VERSION "HNNBNNNYNNNNNNNNNNNNNNNNNNNNNNNNNNNNNNNNNN/4/%%%/4/'%**4NNN///"

NS_ :

BS_:

BU_: AFS AFS_LMod_L AFS_LMod_R BCM1 BVS FCM GLW_LMod_L GLW_LMod_R LCM_L LCM_R LED_DK3_LM_L LED_DK3_LM_R LED_LM_L LED_LM_R LLP_L LLP_R LWR_MXB_L LWR_MXB_R MXB MXB_LM_L MXB_LM_R ZFAS

BO_ 1357 MXB_Feh_LM_R: 8 LED_DK3_LM_R
 SG_ MXB_R_Fernl_MXB_Def_1 : 0|1@1+ (1,0) [0|1] ""  AFS,FCM,MXB
 SG_ MXB_R_Fernl_MXB_Def_2 : 1|1@1+ (1,0) [0|1] ""  AFS,FCM,MXB
 SG_ MXB_R_Fernl_MXB_Def_3 : 2|1@1+ (1,0) [0|1] ""  AFS,FCM,MXB
 SG_ MXB_R_Fernl_MXB_Def_4 : 3|1@1+ (1,0) [0|1] ""  AFS,FCM,MXB
 SG_ MXB_R_Fernl_MXB_Def_5 : 4|1@1+ (1,0) [0|1] ""  AFS,FCM,MXB
 SG_ MXB_R_Fernl_MXB_Def_6 : 5|1@1+ (1,0) [0|1] ""  AFS,FCM,MXB
 SG_ MXB_R_Fernl_MXB_Def_7 : 6|1@1+ (1,0) [0|1] ""  AFS,FCM,MXB
 SG_ MXB_R_Fernl_MXB_Def_Err_Gultig : 7|1@1+ (1,0) [0|1] ""  AFS,FCM,MXB
 SG_ MXB_R_Allg_Elektr_Def_1 : 8|1@1+ (1,0) [0|1] ""  AFS,FCM,MXB
 SG_ MXB_R_Allg_Elektr_Def_2 : 9|1@1+ (1,0) [0|1] ""  AFS,FCM,MXB
 SG_ MXB_R_Allg_Elektr_Def_3 : 10|1@1+ (1,0) [0|1] ""  AFS,FCM,MXB
 SG_ MXB_R_Allg_Elektr_Def_4 : 11|1@1+ (1,0) [0|1] ""  AFS,FCM,MXB
 SG_ MXB_R_Allg_Elektr_Def_5 : 12|1@1+ (1,0) [0|1] ""  AFS,FCM,MXB
 SG_ MXB_R_Allg_Elektr_Def_6 : 13|1@1+ (1,0) [0|1] ""  AFS,FCM,MXB
 SG_ MXB_R_Allg_Elektr_Def_7 : 14|1@1+ (1,0) [0|1] ""  AFS,FCM,MXB
 SG_ MXB_R_Allg_Elektr_Def_8 : 15|1@1+ (1,0) [0|1] ""  AFS,FCM,MXB
 SG_ MXB_R_Allg_Elektr_Def_Err_Gultig : 16|1@1+ (1,0) [0|1] ""  AFS,FCM,MXB
 SG_ MXB_R_Luefter_1_Def_1 : 17|1@1+ (1,0) [0|1] ""  AFS,FCM,MXB
 SG_ MXB_R_Luefter_1_Def_2 : 18|1@1+ (1,0) [0|1] ""  AFS,FCM,MXB
 SG_ MXB_R_Luefter_1_Def_3 : 19|1@1+ (1,0) [0|1] ""  AFS,FCM,MXB
 SG_ MXB_R_Luefter_1_Def_4 : 20|1@1+ (1,0) [0|1] ""  AFS,FCM,MXB
 SG_ MXB_R_Luefter_2_Def_1 : 21|1@1+ (1,0) [0|1] ""  AFS,FCM,MXB
 SG_ MXB_R_Luefter_2_Def_2 : 22|1@1+ (1,0) [0|1] ""  AFS,FCM,MXB
 SG_ MXB_R_Luefter_2_Def_3 : 23|1@1+ (1,0) [0|1] ""  AFS,FCM,MXB
 SG_ MXB_R_Luefter_2_Def_4 : 24|1@1+ (1,0) [0|1] ""  AFS,FCM,MXB
 SG_ MXB_R_Luefter_1_Def_Err_Gultig : 25|1@1+ (1,0) [0|1] ""  AFS,FCM,MXB
 SG_ MXB_R_Luefter_2_Def_Err_Gultig : 26|1@1+ (1,0) [0|1] ""  AFS,FCM,MXB
 SG_ MXB_R_Allg_Elektr_Def : 27|1@1+ (1,0) [0|1] ""  AFS,BCM1,BVS,FCM,MXB,ZFAS
 SG_ MXB_R_Fernl_MXB_Def : 28|1@1+ (1,0) [0|1] ""  AFS,BCM1,BVS,FCM,MXB,ZFAS

BO_ 1438 MXB_Idt_LM_L: 8 LED_LM_L
 SG_ MXB_L_Mux M : 0|8@1+ (1,0) [0|4] ""  AFS,FCM,MXB
 SG_ MXB_L_SW_Idt_Z01 m0 : 8|8@1+ (1,0) [0|255] ""  AFS,FCM,MXB
 SG_ MXB_L_SW_Idt_Z08 m1 : 8|8@1+ (1,0) [0|255] ""  AFS,FCM,MXB
 SG_ MXB_L_SW_Idx_Z04 m2 : 8|8@1+ (1,0) [0|255] ""  AFS,FCM,MXB
 SG_ MXB_L_HW_Idt_Z07 m3 : 8|8@1+ (1,0) [0|255] ""  AFS,FCM,MXB
 SG_ MXB_L_HW_Idx_Z03 m4 : 8|8@1+ (1,0) [0|255] ""  AFS,FCM,MXB
 SG_ MXB_L_SW_Idt_Z02 m0 : 16|8@1+ (1,0) [0|255] ""  AFS,FCM,MXB
 SG_ MXB_L_SW_Idt_Z09 m1 : 16|8@1+ (1,0) [0|255] ""  AFS,FCM,MXB
 SG_ MXB_L_HW_Idt_Z01 m2 : 16|8@1+ (1,0) [0|255] ""  AFS,FCM,MXB
 SG_ MXB_L_HW_Idt_Z08 m3 : 16|8@1+ (1,0) [0|255] ""  AFS,FCM,MXB
 SG_ MXB_L_SW_Idt_Z03 m0 : 24|8@1+ (1,0) [0|255] ""  AFS,FCM,MXB
 SG_ MXB_L_SW_Idt_Z10 m1 : 24|8@1+ (1,0) [0|255] ""  AFS,FCM,MXB
 SG_ MXB_L_HW_Idt_Z02 m2 : 24|8@1+ (1,0) [0|255] ""  AFS,FCM,MXB
 SG_ MXB_L_HW_Idt_Z09 m3 : 24|8@1+ (1,0) [0|255] ""  AFS,FCM,MXB
 SG_ MXB_L_SW_Idt_Z04 m0 : 32|8@1+ (1,0) [0|255] ""  AFS,FCM,MXB
 SG_ MXB_L_SW_Idt_Z11 m1 : 32|8@1+ (1,0) [0|255] ""  AFS,FCM,MXB
 SG_ MXB_L_HW_Idt_Z03 m2 : 32|8@1+ (1,0) [0|255] ""  AFS,FCM,MXB
 SG_ MXB_L_HW_Idt_Z10 m3 : 32|8@1+ (1,0) [0|255] ""  AFS,FCM,MXB
 SG_ MXB_L_SW_Idt_Z05 m0 : 40|8@1+ (1,0) [0|255] ""  AFS,FCM,MXB
 SG_ MXB_L_SW_Idx_Z01 m1 : 40|8@1+ (1,0) [0|255] ""  AFS,FCM,MXB
 SG_ MXB_L_HW_Idt_Z04 m2 : 40|8@1+ (1,0) [0|255] ""  AFS,FCM,MXB
 SG_ MXB_L_HW_Idt_Z11 m3 : 40|8@1+ (1,0) [0|255] ""  AFS,FCM,MXB
 SG_ MXB_L_SW_Idt_Z06 m0 : 48|8@1+ (1,0) [0|255] ""  AFS,FCM,MXB
 SG_ MXB_L_SW_Idx_Z02 m1 : 48|8@1+ (1,0) [0|255] ""  AFS,FCM,MXB
 SG_ MXB_L_HW_Idt_Z05 m2 : 48|8@1+ (1,0) [0|255] ""  AFS,FCM,MXB
 SG_ MXB_L_HW_Idx_Z01 m3 : 48|8@1+ (1,0) [0|255] ""  AFS,FCM,MXB
 SG_ MXB_L_SW_Idt_Z07 m0 : 56|8@1+ (1,0) [0|255] ""  AFS,FCM,MXB
 SG_ MXB_L_SW_Idx_Z03 m1 : 56|8@1+ (1,0) [0|255] ""  AFS,FCM,MXB
 SG_ MXB_L_HW_Idt_Z06 m2 : 56|8@1+ (1,0) [0|255] ""  AFS,FCM,MXB
 SG_ MXB_L_HW_Idx_Z02 m3 : 56|8@1+ (1,0) [0|255] ""  AFS,FCM,MXB

BO_ 1437 MXB_Idt_LM_R: 8 LED_LM_R
 SG_ MXB_R_Mux M : 0|8@1+ (1,0) [0|4] ""  AFS,FCM,MXB
 SG_ MXB_R_SW_Idt_Z01 m0 : 8|8@1+ (1,0) [0|255] ""  AFS,FCM,MXB
 SG_ MXB_R_SW_Idt_Z08 m1 : 8|8@1+ (1,0) [0|255] ""  AFS,FCM,MXB
 SG_ MXB_R_SW_Idx_Z04 m2 : 8|8@1+ (1,0) [0|255] ""  AFS,FCM,MXB
 SG_ MXB_R_HW_Idt_Z07 m3 : 8|8@1+ (1,0) [0|255] ""  AFS,FCM,MXB
 SG_ MXB_R_HW_Idx_Z03 m4 : 8|8@1+ (1,0) [0|255] ""  AFS,FCM,MXB
 SG_ MXB_R_SW_Idt_Z02 m0 : 16|8@1+ (1,0) [0|255] ""  AFS,FCM,MXB
 SG_ MXB_R_SW_Idt_Z09 m1 : 16|8@1+ (1,0) [0|255] ""  AFS,FCM,MXB
 SG_ MXB_R_HW_Idt_Z01 m2 : 16|8@1+ (1,0) [0|255] ""  AFS,FCM,MXB
 SG_ MXB_R_HW_Idt_Z08 m3 : 16|8@1+ (1,0) [0|255] ""  AFS,FCM,MXB
 SG_ MXB_R_SW_Idt_Z03 m0 : 24|8@1+ (1,0) [0|255] ""  AFS,FCM,MXB
 SG_ MXB_R_SW_Idt_Z10 m1 : 24|8@1+ (1,0) [0|255] ""  AFS,FCM,MXB
 SG_ MXB_R_HW_Idt_Z02 m2 : 24|8@1+ (1,0) [0|255] ""  AFS,FCM,MXB
 SG_ MXB_R_HW_Idt_Z09 m3 : 24|8@1+ (1,0) [0|255] ""  AFS,FCM,MXB
 SG_ MXB_R_SW_Idt_Z04 m0 : 32|8@1+ (1,0) [0|255] ""  AFS,FCM,MXB
 SG_ MXB_R_SW_Idt_Z11 m1 : 32|8@1+ (1,0) [0|255] ""  AFS,FCM,MXB
 SG_ MXB_R_HW_Idt_Z03 m2 : 32|8@1+ (1,0) [0|255] ""  AFS,FCM,MXB
 SG_ MXB_R_HW_Idt_Z10 m3 : 32|8@1+ (1,0) [0|255] ""  AFS,FCM,MXB
 SG_ MXB_R_SW_Idt_Z05 m0 : 40|8@1+ (1,0) [0|255] ""  AFS,FCM,MXB
 SG_ MXB_R_SW_Idx_Z01 m1 : 40|8@1+ (1,0) [0|255] ""  AFS,FCM,MXB
 SG_ MXB_R_HW_Idt_Z04 m2 : 40|8@1+ (1,0) [0|255] ""  AFS,FCM,MXB
 SG_ MXB_R_HW_Idt_Z11 m3 : 40|8@1+ (1,0) [0|255] ""  AFS,FCM,MXB
 SG_ MXB_R_SW_Idt_Z06 m0 : 48|8@1+ (1,0) [0|255] ""  AFS,FCM,MXB
 SG_ MXB_R_SW_Idx_Z02 m1 : 48|8@1+ (1,0) [0|255] ""  AFS,FCM,MXB
 SG_ MXB_R_HW_Idt_Z05 m2 : 48|8@1+ (1,0) [0|255] ""  AFS,FCM,MXB
 SG_ MXB_R_HW_Idx_Z01 m3 : 48|8@1+ (1,0) [0|255] ""  AFS,FCM,MXB
 SG_ MXB_R_SW_Idt_Z07 m0 : 56|8@1+ (1,0) [0|255] ""  AFS,FCM,MXB
 SG_ MXB_R_SW_Idx_Z03 m1 : 56|8@1+ (1,0) [0|255] ""  AFS,FCM,MXB
 SG_ MXB_R_HW_Idt_Z06 m2 : 56|8@1+ (1,0) [0|255] ""  AFS,FCM,MXB
 SG_ MXB_R_HW_Idx_Z02 m3 : 56|8@1+ (1,0) [0|255] ""  AFS,FCM,MXB

BO_ 1306 MXB_Ken_LM_L: 8 LED_LM_L
 SG_ MXB_L_Scheinw_Var_1 : 12|8@1+ (1,0) [0|255] ""  AFS,FCM,MXB
 SG_ MXB_L_Scheinw_Var_2 : 20|8@1+ (1,0) [0|255] ""  AFS,FCM,MXB

BO_ 1307 MXB_Ken_LM_R: 8 LED_LM_R
 SG_ MXB_R_Scheinw_Var_1 : 12|8@1+ (1,0) [0|255] ""  AFS,FCM,MXB
 SG_ MXB_R_Scheinw_Var_2 : 20|8@1+ (1,0) [0|255] ""  AFS,FCM,MXB

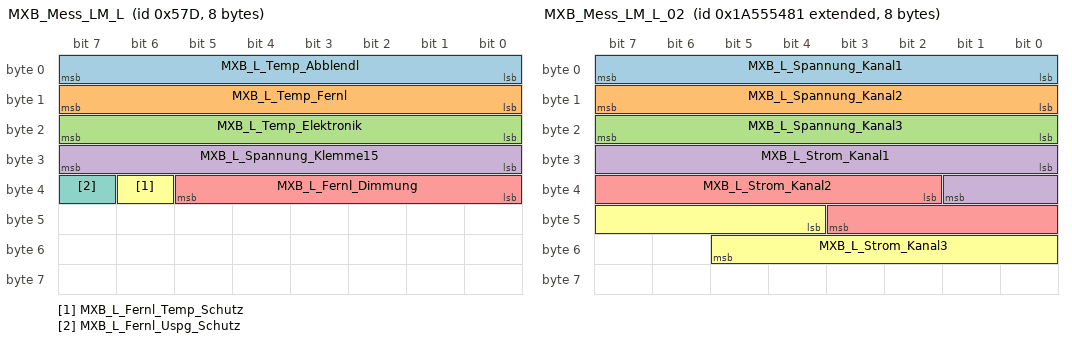
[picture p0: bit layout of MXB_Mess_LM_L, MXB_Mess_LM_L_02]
BO_ 1405 MXB_Mess_LM_L: 8 LED_LM_L
 SG_ MXB_L_Temp_Abblendl : 0|8@1+ (1,-50) [-50|204] "Unit_DegreCelsi"  AFS,FCM,MXB
 SG_ MXB_L_Temp_Fernl : 8|8@1+ (1,-50) [-50|204] "Unit_DegreCelsi"  AFS,FCM,MXB
 SG_ MXB_L_Temp_Elektronik : 16|8@1+ (1,-50) [-50|204] "Unit_DegreCelsi"  AFS,FCM,MXB
 SG_ MXB_L_Spannung_Klemme15 : 24|8@1+ (0.08,0) [0|20.32] "Unit_Volt"  AFS,FCM,MXB
 SG_ MXB_L_Fernl_Dimmung : 32|6@1+ (1.6,0) [1.6|100.8] "Unit_PerCent"  AFS,FCM,MXB
 SG_ MXB_L_Fernl_Temp_Schutz : 38|1@1+ (1,0) [0|1] ""  AFS,FCM,MXB
 SG_ MXB_L_Fernl_Uspg_Schutz : 39|1@1+ (1,0) [0|1] ""  AFS,FCM,MXB

BO_ 2589283457 MXB_Mess_LM_L_02: 8 LED_LM_L
 SG_ MXB_L_Spannung_Kanal1 : 0|8@1+ (0.1,0) [0|25] "Unit_Volt"  FCM,MXB
 SG_ MXB_L_Spannung_Kanal2 : 8|8@1+ (0.1,0) [0|25] "Unit_Volt"  FCM,MXB
 SG_ MXB_L_Spannung_Kanal3 : 16|8@1+ (0.1,0) [0|25] "Unit_Volt"  FCM,MXB
 SG_ MXB_L_Strom_Kanal1 : 24|10@1+ (10,0) [0|10000] "Unit_MilliAmper"  FCM,MXB
 SG_ MXB_L_Strom_Kanal2 : 34|10@1+ (10,0) [0|10000] "Unit_MilliAmper"  FCM,MXB
 SG_ MXB_L_Strom_Kanal3 : 44|10@1+ (10,0) [0|10000] "Unit_MilliAmper"  FCM,MXB

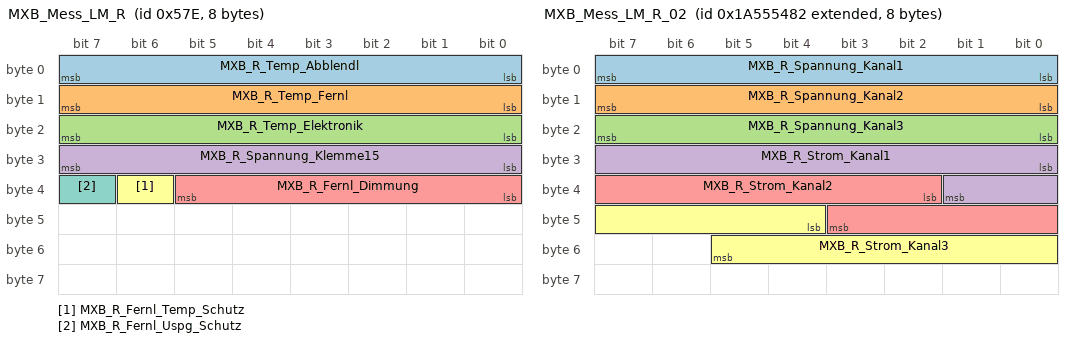
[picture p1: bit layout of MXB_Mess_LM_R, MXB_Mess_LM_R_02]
BO_ 1406 MXB_Mess_LM_R: 8 LED_LM_R
 SG_ MXB_R_Temp_Abblendl : 0|8@1+ (1,-50) [-50|204] "Unit_DegreCelsi"  AFS,FCM,MXB
 SG_ MXB_R_Temp_Fernl : 8|8@1+ (1,-50) [-50|204] "Unit_DegreCelsi"  AFS,FCM,MXB
 SG_ MXB_R_Temp_Elektronik : 16|8@1+ (1,-50) [-50|204] "Unit_DegreCelsi"  AFS,FCM,MXB
 SG_ MXB_R_Spannung_Klemme15 : 24|8@1+ (0.08,0) [0|20.32] "Unit_Volt"  AFS,FCM,MXB
 SG_ MXB_R_Fernl_Dimmung : 32|6@1+ (1.6,0) [1.6|100.8] "Unit_PerCent"  AFS,FCM,MXB
 SG_ MXB_R_Fernl_Temp_Schutz : 38|1@1+ (1,0) [0|1] ""  AFS,FCM,MXB
 SG_ MXB_R_Fernl_Uspg_Schutz : 39|1@1+ (1,0) [0|1] ""  AFS,FCM,MXB

BO_ 2589283458 MXB_Mess_LM_R_02: 8 LED_LM_R
 SG_ MXB_R_Spannung_Kanal1 : 0|8@1+ (0.1,0) [0|25] "Unit_Volt"  FCM,MXB
 SG_ MXB_R_Spannung_Kanal2 : 8|8@1+ (0.1,0) [0|25] "Unit_Volt"  FCM,MXB
 SG_ MXB_R_Spannung_Kanal3 : 16|8@1+ (0.1,0) [0|25] "Unit_Volt"  FCM,MXB
 SG_ MXB_R_Strom_Kanal1 : 24|10@1+ (10,0) [0|10000] "Unit_MilliAmper"  FCM,MXB
 SG_ MXB_R_Strom_Kanal2 : 34|10@1+ (10,0) [0|10000] "Unit_MilliAmper"  FCM,MXB
 SG_ MXB_R_Strom_Kanal3 : 44|10@1+ (10,0) [0|10000] "Unit_MilliAmper"  FCM,MXB

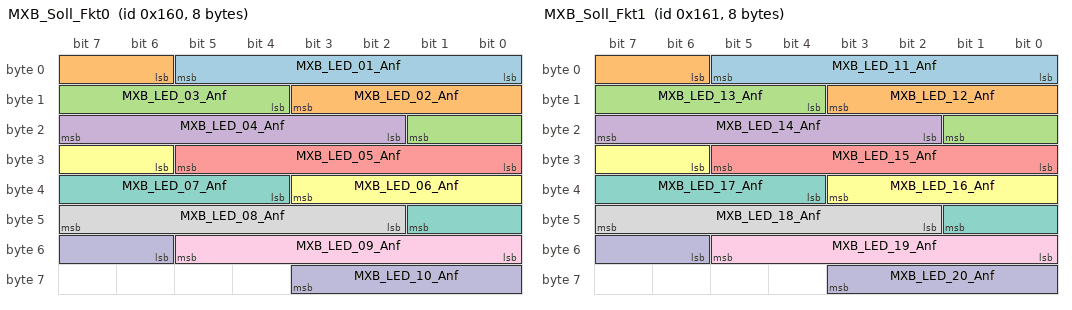
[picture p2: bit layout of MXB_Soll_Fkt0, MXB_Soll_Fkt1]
BO_ 352 MXB_Soll_Fkt0: 8 AFS
 SG_ MXB_LED_01_Anf : 0|6@1+ (1.6,0) [1.6|100.8] "Unit_PerCent"  LED_DK3_LM_L,LED_LM_L,LLP_L,LWR_MXB_L,MXB_LM_L
 SG_ MXB_LED_02_Anf : 6|6@1+ (1.6,0) [1.6|100.8] "Unit_PerCent"  LED_DK3_LM_L,LED_LM_L,LLP_L,LWR_MXB_L,MXB_LM_L
 SG_ MXB_LED_03_Anf : 12|6@1+ (1.6,0) [1.6|100.8] "Unit_PerCent"  LED_DK3_LM_L,LED_LM_L,LLP_L,LWR_MXB_L,MXB_LM_L
 SG_ MXB_LED_04_Anf : 18|6@1+ (1.6,0) [1.6|100.8] "Unit_PerCent"  LED_DK3_LM_L,LED_LM_L,LLP_L,LWR_MXB_L,MXB_LM_L
 SG_ MXB_LED_05_Anf : 24|6@1+ (1.6,0) [1.6|100.8] "Unit_PerCent"  LED_DK3_LM_L,LED_LM_L,LLP_L,LWR_MXB_L,MXB_LM_L
 SG_ MXB_LED_06_Anf : 30|6@1+ (1.6,0) [1.6|100.8] "Unit_PerCent"  LED_DK3_LM_L,LED_LM_L,LLP_L,LWR_MXB_L,MXB_LM_L
 SG_ MXB_LED_07_Anf : 36|6@1+ (1.6,0) [1.6|100.8] "Unit_PerCent"  LED_DK3_LM_L,LED_LM_L,LLP_L,LWR_MXB_L,MXB_LM_L
 SG_ MXB_LED_08_Anf : 42|6@1+ (1.6,0) [1.6|100.8] "Unit_PerCent"  LED_DK3_LM_L,LED_LM_L,LLP_L,LWR_MXB_L,MXB_LM_L
 SG_ MXB_LED_09_Anf : 48|6@1+ (1.6,0) [1.6|100.8] "Unit_PerCent"  LED_DK3_LM_L,LED_LM_L,LLP_L,LWR_MXB_L,MXB_LM_L
 SG_ MXB_LED_10_Anf : 54|6@1+ (1.6,0) [1.6|100.8] "Unit_PerCent"  LED_DK3_LM_L,LED_LM_L,LLP_L,LWR_MXB_L,MXB_LM_L

BO_ 353 MXB_Soll_Fkt1: 8 AFS
 SG_ MXB_LED_11_Anf : 0|6@1+ (1.6,0) [1.6|100.8] "Unit_PerCent"  LED_DK3_LM_L,LED_LM_L,LLP_L,LWR_MXB_L,MXB_LM_L
 SG_ MXB_LED_12_Anf : 6|6@1+ (1.6,0) [1.6|100.8] "Unit_PerCent"  LED_DK3_LM_L,LED_LM_L,LLP_L,LWR_MXB_L,MXB_LM_L
 SG_ MXB_LED_13_Anf : 12|6@1+ (1.6,0) [1.6|100.8] "Unit_PerCent"  LED_DK3_LM_L,LED_LM_L,LLP_L,MXB_LM_L
 SG_ MXB_LED_14_Anf : 18|6@1+ (1.6,0) [1.6|100.8] "Unit_PerCent"  LED_DK3_LM_L,LED_LM_L,LLP_L,MXB_LM_L
 SG_ MXB_LED_15_Anf : 24|6@1+ (1.6,0) [1.6|100.8] "Unit_PerCent"  LED_DK3_LM_L,LED_LM_L,LLP_L,MXB_LM_L
 SG_ MXB_LED_16_Anf : 30|6@1+ (1.6,0) [1.6|100.8] "Unit_PerCent"  LED_DK3_LM_L,LED_LM_L,LLP_L,MXB_LM_L
 SG_ MXB_LED_17_Anf : 36|6@1+ (1.6,0) [1.6|100.8] "Unit_PerCent"  LED_DK3_LM_L,LED_LM_L,LLP_L,MXB_LM_L
 SG_ MXB_LED_18_Anf : 42|6@1+ (1.6,0) [1.6|100.8] "Unit_PerCent"  LED_DK3_LM_L,LED_LM_L,LLP_L,MXB_LM_L
 SG_ MXB_LED_19_Anf : 48|6@1+ (1.6,0) [1.6|100.8] "Unit_PerCent"  LED_DK3_LM_L,LED_LM_L,LLP_L,MXB_LM_L
 SG_ MXB_LED_20_Anf : 54|6@1+ (1.6,0) [1.6|100.8] "Unit_PerCent"  LED_DK3_LM_L,LED_LM_L,LLP_L,MXB_LM_L

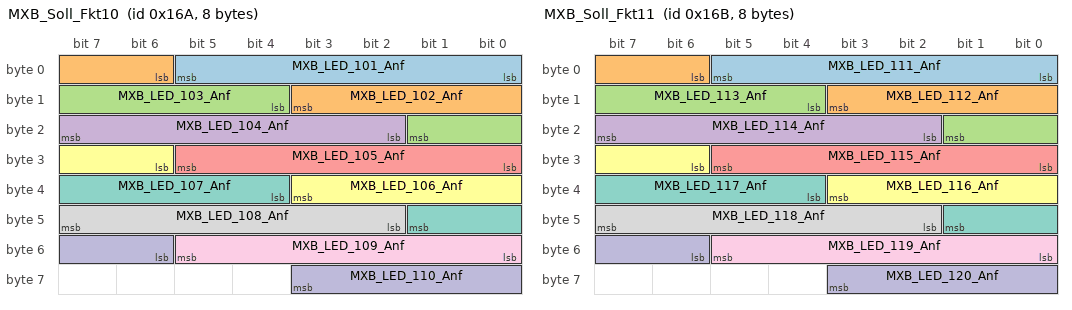
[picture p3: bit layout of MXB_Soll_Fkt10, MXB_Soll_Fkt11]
BO_ 362 MXB_Soll_Fkt10: 8 BVS
 SG_ MXB_LED_101_Anf : 0|6@1+ (1.6,0) [1.6|100.8] "Unit_PerCent"  LED_DK3_LM_R,LLP_R
 SG_ MXB_LED_102_Anf : 6|6@1+ (1.6,0) [1.6|100.8] "Unit_PerCent"  LED_DK3_LM_R,LLP_R
 SG_ MXB_LED_103_Anf : 12|6@1+ (1.6,0) [1.6|100.8] "Unit_PerCent"  LED_DK3_LM_R,LLP_R
 SG_ MXB_LED_104_Anf : 18|6@1+ (1.6,0) [1.6|100.8] "Unit_PerCent"  LED_DK3_LM_R,LLP_R
 SG_ MXB_LED_105_Anf : 24|6@1+ (1.6,0) [1.6|100.8] "Unit_PerCent"  LED_DK3_LM_R,LLP_R
 SG_ MXB_LED_106_Anf : 30|6@1+ (1.6,0) [1.6|100.8] "Unit_PerCent"  LED_DK3_LM_R,LLP_R
 SG_ MXB_LED_107_Anf : 36|6@1+ (1.6,0) [1.6|100.8] "Unit_PerCent"  LED_DK3_LM_R,LLP_R
 SG_ MXB_LED_108_Anf : 42|6@1+ (1.6,0) [1.6|100.8] "Unit_PerCent"  LED_DK3_LM_R,LLP_R
 SG_ MXB_LED_109_Anf : 48|6@1+ (1.6,0) [1.6|100.8] "Unit_PerCent"  LED_DK3_LM_R,LLP_R
 SG_ MXB_LED_110_Anf : 54|6@1+ (1.6,0) [1.6|100.8] "Unit_PerCent"  LED_DK3_LM_R,LLP_R

BO_ 363 MXB_Soll_Fkt11: 8 BVS
 SG_ MXB_LED_111_Anf : 0|6@1+ (1.6,0) [1.6|100.8] "Unit_PerCent"  LED_DK3_LM_R,LLP_R
 SG_ MXB_LED_112_Anf : 6|6@1+ (1.6,0) [1.6|100.8] "Unit_PerCent"  LED_DK3_LM_R,LLP_R
 SG_ MXB_LED_113_Anf : 12|6@1+ (1.6,0) [1.6|100.8] "Unit_PerCent"  LED_DK3_LM_R,LLP_R
 SG_ MXB_LED_114_Anf : 18|6@1+ (1.6,0) [1.6|100.8] "Unit_PerCent"  LED_DK3_LM_R,LLP_R
 SG_ MXB_LED_115_Anf : 24|6@1+ (1.6,0) [1.6|100.8] "Unit_PerCent"  LED_DK3_LM_R,LLP_R
 SG_ MXB_LED_116_Anf : 30|6@1+ (1.6,0) [1.6|100.8] "Unit_PerCent"  LED_DK3_LM_R,LLP_R
 SG_ MXB_LED_117_Anf : 36|6@1+ (1.6,0) [1.6|100.8] "Unit_PerCent"  LED_DK3_LM_R,LLP_R
 SG_ MXB_LED_118_Anf : 42|6@1+ (1.6,0) [1.6|100.8] "Unit_PerCent"  LED_DK3_LM_R,LLP_R
 SG_ MXB_LED_119_Anf : 48|6@1+ (1.6,0) [1.6|100.8] "Unit_PerCent"  LED_DK3_LM_R,LLP_R
 SG_ MXB_LED_120_Anf : 54|6@1+ (1.6,0) [1.6|100.8] "Unit_PerCent"  LED_DK3_LM_R,LLP_R

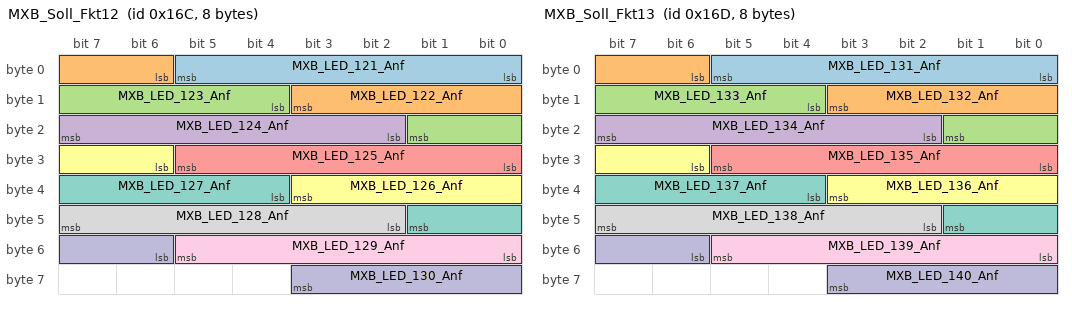
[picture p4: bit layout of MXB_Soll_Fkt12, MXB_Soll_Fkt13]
BO_ 364 MXB_Soll_Fkt12: 8 BVS
 SG_ MXB_LED_121_Anf : 0|6@1+ (1.6,0) [1.6|100.8] "Unit_PerCent"  LED_DK3_LM_R,LLP_R
 SG_ MXB_LED_122_Anf : 6|6@1+ (1.6,0) [1.6|100.8] "Unit_PerCent"  LED_DK3_LM_R,LLP_R
 SG_ MXB_LED_123_Anf : 12|6@1+ (1.6,0) [1.6|100.8] "Unit_PerCent"  LED_DK3_LM_R,LLP_R
 SG_ MXB_LED_124_Anf : 18|6@1+ (1.6,0) [1.6|100.8] "Unit_PerCent"  LED_DK3_LM_R,LLP_R
 SG_ MXB_LED_125_Anf : 24|6@1+ (1.6,0) [1.6|100.8] "Unit_PerCent"  LED_DK3_LM_R,LLP_R
 SG_ MXB_LED_126_Anf : 30|6@1+ (1.6,0) [1.6|100.8] "Unit_PerCent"  LED_DK3_LM_R,LLP_R
 SG_ MXB_LED_127_Anf : 36|6@1+ (1.6,0) [1.6|100.8] "Unit_PerCent"  LED_DK3_LM_R,LLP_R
 SG_ MXB_LED_128_Anf : 42|6@1+ (1.6,0) [1.6|100.8] "Unit_PerCent"  LED_DK3_LM_R,LLP_R
 SG_ MXB_LED_129_Anf : 48|6@1+ (1.6,0) [1.6|100.8] "Unit_PerCent"  LED_DK3_LM_R,LLP_R
 SG_ MXB_LED_130_Anf : 54|6@1+ (1.6,0) [1.6|100.8] "Unit_PerCent"  LED_DK3_LM_R,LLP_R

BO_ 365 MXB_Soll_Fkt13: 8 BVS
 SG_ MXB_LED_131_Anf : 0|6@1+ (1.6,0) [1.6|100.8] "Unit_PerCent"  LED_DK3_LM_R,LLP_R
 SG_ MXB_LED_132_Anf : 6|6@1+ (1.6,0) [1.6|100.8] "Unit_PerCent"  LED_DK3_LM_R,LLP_R
 SG_ MXB_LED_133_Anf : 12|6@1+ (1.6,0) [1.6|100.8] "Unit_PerCent"  LED_DK3_LM_R,LLP_R
 SG_ MXB_LED_134_Anf : 18|6@1+ (1.6,0) [1.6|100.8] "Unit_PerCent"  LED_DK3_LM_R,LLP_R
 SG_ MXB_LED_135_Anf : 24|6@1+ (1.6,0) [1.6|100.8] "Unit_PerCent"  LED_DK3_LM_R,LLP_R
 SG_ MXB_LED_136_Anf : 30|6@1+ (1.6,0) [1.6|100.8] "Unit_PerCent"  LED_DK3_LM_R,LLP_R
 SG_ MXB_LED_137_Anf : 36|6@1+ (1.6,0) [1.6|100.8] "Unit_PerCent"  LED_DK3_LM_R,LLP_R
 SG_ MXB_LED_138_Anf : 42|6@1+ (1.6,0) [1.6|100.8] "Unit_PerCent"  LED_DK3_LM_R,LLP_R
 SG_ MXB_LED_139_Anf : 48|6@1+ (1.6,0) [1.6|100.8] "Unit_PerCent"  LED_DK3_LM_R,LLP_R
 SG_ MXB_LED_140_Anf : 54|6@1+ (1.6,0) [1.6|100.8] "Unit_PerCent"  LED_DK3_LM_R,LLP_R

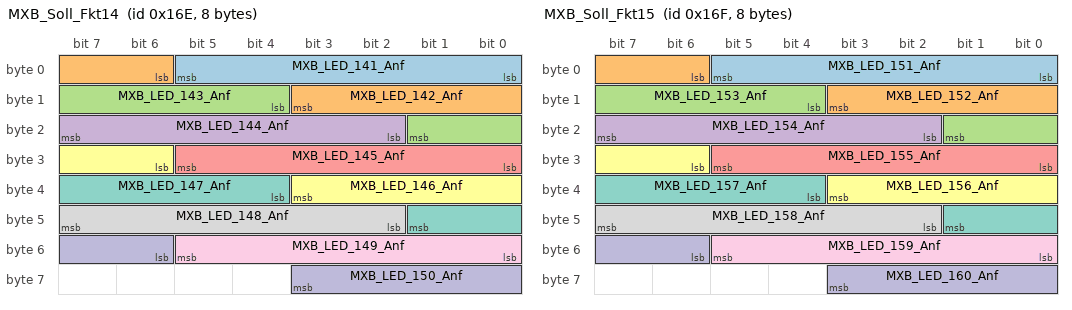
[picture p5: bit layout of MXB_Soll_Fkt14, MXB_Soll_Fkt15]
BO_ 366 MXB_Soll_Fkt14: 8 BVS
 SG_ MXB_LED_141_Anf : 0|6@1+ (1.6,0) [1.6|100.8] "Unit_PerCent"  LED_DK3_LM_R,LLP_R
 SG_ MXB_LED_142_Anf : 6|6@1+ (1.6,0) [1.6|100.8] "Unit_PerCent"  LED_DK3_LM_R,LLP_R
 SG_ MXB_LED_143_Anf : 12|6@1+ (1.6,0) [1.6|100.8] "Unit_PerCent"  LED_DK3_LM_R,LLP_R
 SG_ MXB_LED_144_Anf : 18|6@1+ (1.6,0) [1.6|100.8] "Unit_PerCent"  LED_DK3_LM_R,LLP_R
 SG_ MXB_LED_145_Anf : 24|6@1+ (1.6,0) [1.6|100.8] "Unit_PerCent"  LED_DK3_LM_R,LLP_R
 SG_ MXB_LED_146_Anf : 30|6@1+ (1.6,0) [1.6|100.8] "Unit_PerCent"  LED_DK3_LM_R,LLP_R
 SG_ MXB_LED_147_Anf : 36|6@1+ (1.6,0) [1.6|100.8] "Unit_PerCent"  LED_DK3_LM_R,LLP_R
 SG_ MXB_LED_148_Anf : 42|6@1+ (1.6,0) [1.6|100.8] "Unit_PerCent"  LED_DK3_LM_R,LLP_R
 SG_ MXB_LED_149_Anf : 48|6@1+ (1.6,0) [1.6|100.8] "Unit_PerCent"  LED_DK3_LM_R,LLP_R
 SG_ MXB_LED_150_Anf : 54|6@1+ (1.6,0) [1.6|100.8] "Unit_PerCent"  LED_DK3_LM_R,LLP_R

BO_ 367 MXB_Soll_Fkt15: 8 BVS
 SG_ MXB_LED_151_Anf : 0|6@1+ (1.6,0) [1.6|100.8] "Unit_PerCent"  LED_DK3_LM_R,LLP_R
 SG_ MXB_LED_152_Anf : 6|6@1+ (1.6,0) [1.6|100.8] "Unit_PerCent"  LED_DK3_LM_R,LLP_R
 SG_ MXB_LED_153_Anf : 12|6@1+ (1.6,0) [1.6|100.8] "Unit_PerCent"  LED_DK3_LM_R,LLP_R
 SG_ MXB_LED_154_Anf : 18|6@1+ (1.6,0) [1.6|100.8] "Unit_PerCent"  LED_DK3_LM_R,LLP_R
 SG_ MXB_LED_155_Anf : 24|6@1+ (1.6,0) [1.6|100.8] "Unit_PerCent"  LED_DK3_LM_R,LLP_R
 SG_ MXB_LED_156_Anf : 30|6@1+ (1.6,0) [1.6|100.8] "Unit_PerCent"  LED_DK3_LM_R,LLP_R
 SG_ MXB_LED_157_Anf : 36|6@1+ (1.6,0) [1.6|100.8] "Unit_PerCent"  LED_DK3_LM_R,LLP_R
 SG_ MXB_LED_158_Anf : 42|6@1+ (1.6,0) [1.6|100.8] "Unit_PerCent"  LED_DK3_LM_R,LLP_R
 SG_ MXB_LED_159_Anf : 48|6@1+ (1.6,0) [1.6|100.8] "Unit_PerCent"  LED_DK3_LM_R,LLP_R
 SG_ MXB_LED_160_Anf : 54|6@1+ (1.6,0) [1.6|100.8] "Unit_PerCent"  LED_DK3_LM_R,LLP_R

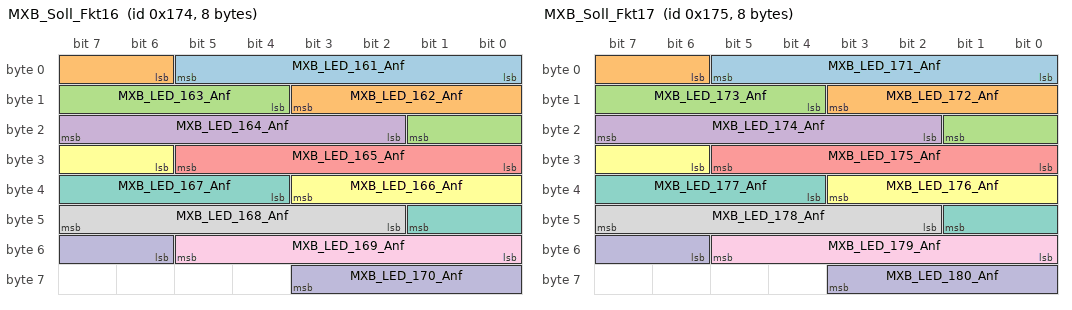
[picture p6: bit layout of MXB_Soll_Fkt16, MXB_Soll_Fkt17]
BO_ 372 MXB_Soll_Fkt16: 8 BVS
 SG_ MXB_LED_161_Anf : 0|6@1+ (1.6,0) [1.6|100.8] "Unit_PerCent"  LED_DK3_LM_R,LLP_R
 SG_ MXB_LED_162_Anf : 6|6@1+ (1.6,0) [1.6|100.8] "Unit_PerCent"  LED_DK3_LM_R,LLP_R
 SG_ MXB_LED_163_Anf : 12|6@1+ (1.6,0) [1.6|100.8] "Unit_PerCent"  LED_DK3_LM_R,LLP_R
 SG_ MXB_LED_164_Anf : 18|6@1+ (1.6,0) [1.6|100.8] "Unit_PerCent"  LED_DK3_LM_R,LLP_R
 SG_ MXB_LED_165_Anf : 24|6@1+ (1.6,0) [1.6|100.8] "Unit_PerCent"  LED_DK3_LM_R,LLP_R
 SG_ MXB_LED_166_Anf : 30|6@1+ (1.6,0) [1.6|100.8] "Unit_PerCent"  LED_DK3_LM_R,LLP_R
 SG_ MXB_LED_167_Anf : 36|6@1+ (1.6,0) [1.6|100.8] "Unit_PerCent"  LED_DK3_LM_R,LLP_R
 SG_ MXB_LED_168_Anf : 42|6@1+ (1.6,0) [1.6|100.8] "Unit_PerCent"  LED_DK3_LM_R,LLP_R
 SG_ MXB_LED_169_Anf : 48|6@1+ (1.6,0) [1.6|100.8] "Unit_PerCent"  LED_DK3_LM_R,LLP_R
 SG_ MXB_LED_170_Anf : 54|6@1+ (1.6,0) [1.6|100.8] "Unit_PerCent"  LED_DK3_LM_R,LLP_R

BO_ 373 MXB_Soll_Fkt17: 8 BVS
 SG_ MXB_LED_171_Anf : 0|6@1+ (1.6,0) [1.6|100.8] "Unit_PerCent"  LED_DK3_LM_R,LLP_R
 SG_ MXB_LED_172_Anf : 6|6@1+ (1.6,0) [1.6|100.8] "Unit_PerCent"  LED_DK3_LM_R,LLP_R
 SG_ MXB_LED_173_Anf : 12|6@1+ (1.6,0) [1.6|100.8] "Unit_PerCent"  LED_DK3_LM_R,LLP_R
 SG_ MXB_LED_174_Anf : 18|6@1+ (1.6,0) [1.6|100.8] "Unit_PerCent"  LED_DK3_LM_R,LLP_R
 SG_ MXB_LED_175_Anf : 24|6@1+ (1.6,0) [1.6|100.8] "Unit_PerCent"  LED_DK3_LM_R,LLP_R
 SG_ MXB_LED_176_Anf : 30|6@1+ (1.6,0) [1.6|100.8] "Unit_PerCent"  LED_DK3_LM_R,LLP_R
 SG_ MXB_LED_177_Anf : 36|6@1+ (1.6,0) [1.6|100.8] "Unit_PerCent"  LED_DK3_LM_R,LLP_R
 SG_ MXB_LED_178_Anf : 42|6@1+ (1.6,0) [1.6|100.8] "Unit_PerCent"  LED_DK3_LM_R,LLP_R
 SG_ MXB_LED_179_Anf : 48|6@1+ (1.6,0) [1.6|100.8] "Unit_PerCent"  LED_DK3_LM_R,LLP_R
 SG_ MXB_LED_180_Anf : 54|6@1+ (1.6,0) [1.6|100.8] "Unit_PerCent"  LED_DK3_LM_R,LLP_R

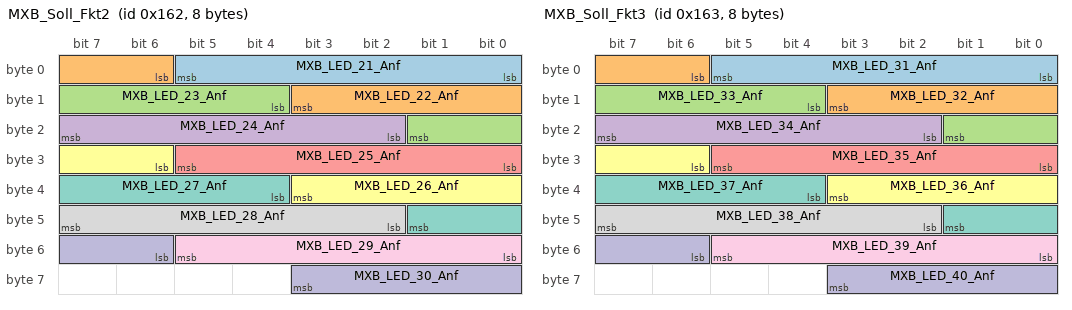
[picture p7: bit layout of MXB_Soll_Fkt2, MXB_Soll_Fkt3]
BO_ 354 MXB_Soll_Fkt2: 8 AFS
 SG_ MXB_LED_21_Anf : 0|6@1+ (1.6,0) [1.6|100.8] "Unit_PerCent"  LED_DK3_LM_L,LED_LM_L,LLP_L,MXB_LM_L
 SG_ MXB_LED_22_Anf : 6|6@1+ (1.6,0) [1.6|100.8] "Unit_PerCent"  LED_DK3_LM_L,LED_LM_L,LLP_L,MXB_LM_L
 SG_ MXB_LED_23_Anf : 12|6@1+ (1.6,0) [1.6|100.8] "Unit_PerCent"  LED_DK3_LM_L,LED_LM_L,LLP_L,MXB_LM_L
 SG_ MXB_LED_24_Anf : 18|6@1+ (1.6,0) [1.6|100.8] "Unit_PerCent"  LED_DK3_LM_L,LED_LM_L,LLP_L,MXB_LM_L
 SG_ MXB_LED_25_Anf : 24|6@1+ (1.6,0) [1.6|100.8] "Unit_PerCent"  LED_DK3_LM_L,LED_LM_L,LLP_L,MXB_LM_L
 SG_ MXB_LED_26_Anf : 30|6@1+ (1.6,0) [1.6|100.8] "Unit_PerCent"  LED_DK3_LM_L,LED_LM_L,LLP_L,MXB_LM_L
 SG_ MXB_LED_27_Anf : 36|6@1+ (1.6,0) [1.6|100.8] "Unit_PerCent"  LED_DK3_LM_L,LED_LM_L,LLP_L,MXB_LM_L
 SG_ MXB_LED_28_Anf : 42|6@1+ (1.6,0) [1.6|100.8] "Unit_PerCent"  LED_DK3_LM_L,LED_LM_L,LLP_L,MXB_LM_L
 SG_ MXB_LED_29_Anf : 48|6@1+ (1.6,0) [1.6|100.8] "Unit_PerCent"  LED_DK3_LM_L,LED_LM_L,LLP_L,MXB_LM_L
 SG_ MXB_LED_30_Anf : 54|6@1+ (1.6,0) [1.6|100.8] "Unit_PerCent"  LED_DK3_LM_L,LED_LM_L,LLP_L,MXB_LM_L

BO_ 355 MXB_Soll_Fkt3: 8 AFS
 SG_ MXB_LED_31_Anf : 0|6@1+ (1.6,0) [1.6|100.8] "Unit_PerCent"  LED_DK3_LM_L,LED_LM_L,LLP_L,MXB_LM_L
 SG_ MXB_LED_32_Anf : 6|6@1+ (1.6,0) [1.6|100.8] "Unit_PerCent"  LED_DK3_LM_L,LED_LM_L,LLP_L,MXB_LM_L
 SG_ MXB_LED_33_Anf : 12|6@1+ (1.6,0) [1.6|100.8] "Unit_PerCent"  LED_DK3_LM_L,LED_LM_L,LLP_L,MXB_LM_L
 SG_ MXB_LED_34_Anf : 18|6@1+ (1.6,0) [1.6|100.8] "Unit_PerCent"  LED_DK3_LM_L,LED_LM_L,LLP_L,MXB_LM_L
 SG_ MXB_LED_35_Anf : 24|6@1+ (1.6,0) [1.6|100.8] "Unit_PerCent"  LED_DK3_LM_L,LED_LM_L,LLP_L,MXB_LM_L
 SG_ MXB_LED_36_Anf : 30|6@1+ (1.6,0) [1.6|100.8] "Unit_PerCent"  LED_DK3_LM_L,LED_LM_L,LLP_L,MXB_LM_L
 SG_ MXB_LED_37_Anf : 36|6@1+ (1.6,0) [1.6|100.8] "Unit_PerCent"  LED_DK3_LM_L,LED_LM_L,LLP_L,MXB_LM_L
 SG_ MXB_LED_38_Anf : 42|6@1+ (1.6,0) [1.6|100.8] "Unit_PerCent"  LED_DK3_LM_L,LED_LM_L,LLP_L,MXB_LM_L
 SG_ MXB_LED_39_Anf : 48|6@1+ (1.6,0) [1.6|100.8] "Unit_PerCent"  LED_DK3_LM_L,LED_LM_L,LLP_L,MXB_LM_L
 SG_ MXB_LED_40_Anf : 54|6@1+ (1.6,0) [1.6|100.8] "Unit_PerCent"  LED_DK3_LM_L,LED_LM_L,LLP_L,MXB_LM_L

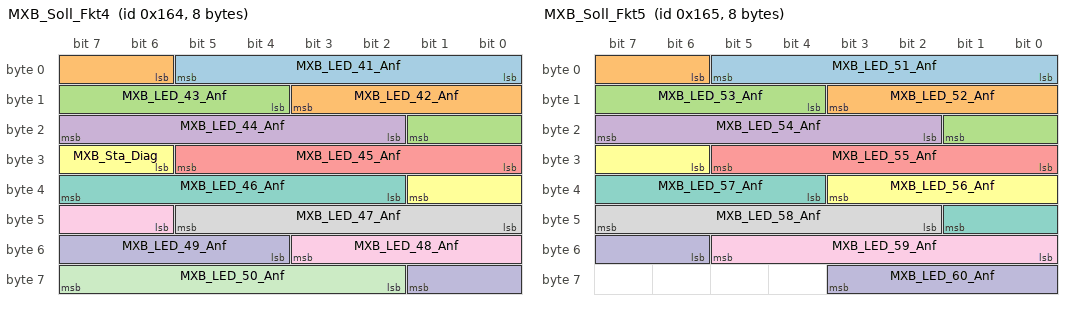
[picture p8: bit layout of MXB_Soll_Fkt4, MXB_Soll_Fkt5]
BO_ 356 MXB_Soll_Fkt4: 8 AFS
 SG_ MXB_LED_41_Anf : 0|6@1+ (1.6,0) [1.6|100.8] "Unit_PerCent"  LED_DK3_LM_L,LED_LM_L,LLP_L,MXB_LM_L
 SG_ MXB_LED_42_Anf : 6|6@1+ (1.6,0) [1.6|100.8] "Unit_PerCent"  LED_DK3_LM_L,LED_LM_L,LLP_L,MXB_LM_L
 SG_ MXB_LED_43_Anf : 12|6@1+ (1.6,0) [1.6|100.8] "Unit_PerCent"  LED_DK3_LM_L,LED_LM_L,LLP_L,MXB_LM_L
 SG_ MXB_LED_44_Anf : 18|6@1+ (1.6,0) [1.6|100.8] "Unit_PerCent"  LED_DK3_LM_L,LED_LM_L,LLP_L,MXB_LM_L
 SG_ MXB_LED_45_Anf : 24|6@1+ (1.6,0) [1.6|100.8] "Unit_PerCent"  LED_DK3_LM_L,LED_LM_L,LLP_L,MXB_LM_L
 SG_ MXB_Sta_Diag : 30|4@1+ (1,0) [0|15] ""  LWR_MXB_L,LWR_MXB_R,MXB_LM_L,MXB_LM_R
 SG_ MXB_LED_46_Anf : 34|6@1+ (1.6,0) [1.6|100.8] "Unit_PerCent"  LED_DK3_LM_L,LED_LM_R,LLP_L,LWR_MXB_R,MXB_LM_R
 SG_ MXB_LED_47_Anf : 40|6@1+ (1.6,0) [1.6|100.8] "Unit_PerCent"  LED_DK3_LM_L,LED_LM_R,LLP_L,LWR_MXB_R,MXB_LM_R
 SG_ MXB_LED_48_Anf : 46|6@1+ (1.6,0) [1.6|100.8] "Unit_PerCent"  LED_DK3_LM_L,LED_LM_R,LLP_L,LWR_MXB_R,MXB_LM_R
 SG_ MXB_LED_49_Anf : 52|6@1+ (1.6,0) [1.6|100.8] "Unit_PerCent"  LED_DK3_LM_L,LED_LM_R,LLP_L,LWR_MXB_R,MXB_LM_R
 SG_ MXB_LED_50_Anf : 58|6@1+ (1.6,0) [1.6|100.8] "Unit_PerCent"  LED_DK3_LM_L,LED_LM_R,LLP_L,LWR_MXB_R,MXB_LM_R

BO_ 357 MXB_Soll_Fkt5: 8 AFS
 SG_ MXB_LED_51_Anf : 0|6@1+ (1.6,0) [1.6|100.8] "Unit_PerCent"  LED_DK3_LM_L,LED_LM_R,LLP_L,LWR_MXB_R,MXB_LM_R
 SG_ MXB_LED_52_Anf : 6|6@1+ (1.6,0) [1.6|100.8] "Unit_PerCent"  LED_DK3_LM_L,LED_LM_R,LLP_L,LWR_MXB_R,MXB_LM_R
 SG_ MXB_LED_53_Anf : 12|6@1+ (1.6,0) [1.6|100.8] "Unit_PerCent"  LED_DK3_LM_L,LED_LM_R,LLP_L,LWR_MXB_R,MXB_LM_R
 SG_ MXB_LED_54_Anf : 18|6@1+ (1.6,0) [1.6|100.8] "Unit_PerCent"  LED_DK3_LM_L,LED_LM_R,LLP_L,LWR_MXB_R,MXB_LM_R
 SG_ MXB_LED_55_Anf : 24|6@1+ (1.6,0) [1.6|100.8] "Unit_PerCent"  LED_DK3_LM_L,LED_LM_R,LLP_L,LWR_MXB_R,MXB_LM_R
 SG_ MXB_LED_56_Anf : 30|6@1+ (1.6,0) [1.6|100.8] "Unit_PerCent"  LED_DK3_LM_L,LED_LM_R,LLP_L,LWR_MXB_R,MXB_LM_R
 SG_ MXB_LED_57_Anf : 36|6@1+ (1.6,0) [1.6|100.8] "Unit_PerCent"  LED_DK3_LM_L,LED_LM_R,LLP_L,LWR_MXB_R,MXB_LM_R
 SG_ MXB_LED_58_Anf : 42|6@1+ (1.6,0) [1.6|100.8] "Unit_PerCent"  LED_DK3_LM_L,LED_LM_R,LLP_L,MXB_LM_R
 SG_ MXB_LED_59_Anf : 48|6@1+ (1.6,0) [1.6|100.8] "Unit_PerCent"  LED_DK3_LM_L,LED_LM_R,LLP_L,MXB_LM_R
 SG_ MXB_LED_60_Anf : 54|6@1+ (1.6,0) [1.6|100.8] "Unit_PerCent"  LED_DK3_LM_L,LED_LM_R,LLP_L,MXB_LM_R

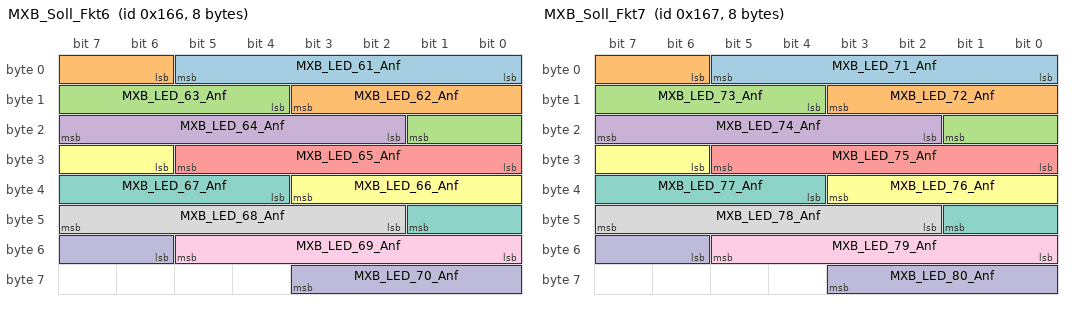
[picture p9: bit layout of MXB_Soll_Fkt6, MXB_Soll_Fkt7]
BO_ 358 MXB_Soll_Fkt6: 8 AFS
 SG_ MXB_LED_61_Anf : 0|6@1+ (1.6,0) [1.6|100.8] "Unit_PerCent"  LED_DK3_LM_L,LED_LM_R,LLP_L,MXB_LM_R
 SG_ MXB_LED_62_Anf : 6|6@1+ (1.6,0) [1.6|100.8] "Unit_PerCent"  LED_DK3_LM_L,LED_LM_R,LLP_L,MXB_LM_R
 SG_ MXB_LED_63_Anf : 12|6@1+ (1.6,0) [1.6|100.8] "Unit_PerCent"  LED_DK3_LM_L,LED_LM_R,LLP_L,MXB_LM_R
 SG_ MXB_LED_64_Anf : 18|6@1+ (1.6,0) [1.6|100.8] "Unit_PerCent"  LED_DK3_LM_L,LED_LM_R,LLP_L,MXB_LM_R
 SG_ MXB_LED_65_Anf : 24|6@1+ (1.6,0) [1.6|100.8] "Unit_PerCent"  LED_DK3_LM_L,LED_LM_R,LLP_L,MXB_LM_R
 SG_ MXB_LED_66_Anf : 30|6@1+ (1.6,0) [1.6|100.8] "Unit_PerCent"  LED_DK3_LM_L,LED_LM_R,LLP_L,MXB_LM_R
 SG_ MXB_LED_67_Anf : 36|6@1+ (1.6,0) [1.6|100.8] "Unit_PerCent"  LED_DK3_LM_L,LED_LM_R,LLP_L,MXB_LM_R
 SG_ MXB_LED_68_Anf : 42|6@1+ (1.6,0) [1.6|100.8] "Unit_PerCent"  LED_DK3_LM_L,LED_LM_R,LLP_L,MXB_LM_R
 SG_ MXB_LED_69_Anf : 48|6@1+ (1.6,0) [1.6|100.8] "Unit_PerCent"  LED_DK3_LM_L,LED_LM_R,LLP_L,MXB_LM_R
 SG_ MXB_LED_70_Anf : 54|6@1+ (1.6,0) [1.6|100.8] "Unit_PerCent"  LED_DK3_LM_L,LED_LM_R,LLP_L,MXB_LM_R

BO_ 359 MXB_Soll_Fkt7: 8 AFS
 SG_ MXB_LED_71_Anf : 0|6@1+ (1.6,0) [1.6|100.8] "Unit_PerCent"  LED_DK3_LM_L,LED_LM_R,LLP_L,MXB_LM_R
 SG_ MXB_LED_72_Anf : 6|6@1+ (1.6,0) [1.6|100.8] "Unit_PerCent"  LED_DK3_LM_L,LED_LM_R,LLP_L,MXB_LM_R
 SG_ MXB_LED_73_Anf : 12|6@1+ (1.6,0) [1.6|100.8] "Unit_PerCent"  LED_DK3_LM_L,LED_LM_R,LLP_L,MXB_LM_R
 SG_ MXB_LED_74_Anf : 18|6@1+ (1.6,0) [1.6|100.8] "Unit_PerCent"  LED_DK3_LM_L,LED_LM_R,LLP_L,MXB_LM_R
 SG_ MXB_LED_75_Anf : 24|6@1+ (1.6,0) [1.6|100.8] "Unit_PerCent"  LED_DK3_LM_L,LED_LM_R,LLP_L,MXB_LM_R
 SG_ MXB_LED_76_Anf : 30|6@1+ (1.6,0) [1.6|100.8] "Unit_PerCent"  LED_DK3_LM_L,LED_LM_R,LLP_L,MXB_LM_R
 SG_ MXB_LED_77_Anf : 36|6@1+ (1.6,0) [1.6|100.8] "Unit_PerCent"  LED_DK3_LM_L,LED_LM_R,LLP_L,MXB_LM_R
 SG_ MXB_LED_78_Anf : 42|6@1+ (1.6,0) [1.6|100.8] "Unit_PerCent"  LED_DK3_LM_L,LED_LM_R,LLP_L,MXB_LM_R
 SG_ MXB_LED_79_Anf : 48|6@1+ (1.6,0) [1.6|100.8] "Unit_PerCent"  LED_DK3_LM_L,LED_LM_R,LLP_L,MXB_LM_R
 SG_ MXB_LED_80_Anf : 54|6@1+ (1.6,0) [1.6|100.8] "Unit_PerCent"  LED_DK3_LM_L,LED_LM_R,LLP_L,MXB_LM_R

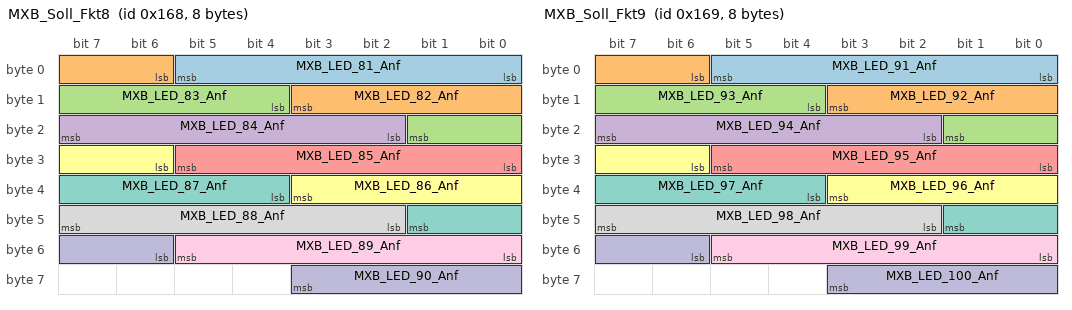
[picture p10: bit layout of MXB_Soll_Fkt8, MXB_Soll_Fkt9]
BO_ 360 MXB_Soll_Fkt8: 8 AFS
 SG_ MXB_LED_81_Anf : 0|6@1+ (1.6,0) [1.6|100.8] "Unit_PerCent"  LED_DK3_LM_L,LED_LM_R,LLP_L,MXB_LM_R
 SG_ MXB_LED_82_Anf : 6|6@1+ (1.6,0) [1.6|100.8] "Unit_PerCent"  LED_DK3_LM_L,LED_LM_R,LLP_L,MXB_LM_R
 SG_ MXB_LED_83_Anf : 12|6@1+ (1.6,0) [1.6|100.8] "Unit_PerCent"  LED_DK3_LM_L,LED_LM_R,LLP_L,MXB_LM_R
 SG_ MXB_LED_84_Anf : 18|6@1+ (1.6,0) [1.6|100.8] "Unit_PerCent"  LED_DK3_LM_L,LED_LM_R,LLP_L,MXB_LM_R
 SG_ MXB_LED_85_Anf : 24|6@1+ (1.6,0) [1.6|100.8] "Unit_PerCent"  LED_DK3_LM_L,LED_LM_R,LLP_L,MXB_LM_R
 SG_ MXB_LED_86_Anf : 30|6@1+ (1.6,0) [1.6|100.8] "Unit_PerCent"  LED_DK3_LM_L,LED_LM_R,LLP_L,MXB_LM_R
 SG_ MXB_LED_87_Anf : 36|6@1+ (1.6,0) [1.6|100.8] "Unit_PerCent"  LED_DK3_LM_L,LED_LM_R,LLP_L,MXB_LM_R
 SG_ MXB_LED_88_Anf : 42|6@1+ (1.6,0) [1.6|100.8] "Unit_PerCent"  LED_DK3_LM_L,LED_LM_R,LLP_L,MXB_LM_R
 SG_ MXB_LED_89_Anf : 48|6@1+ (1.6,0) [1.6|100.8] "Unit_PerCent"  LED_DK3_LM_L,LED_LM_R,LLP_L,MXB_LM_R
 SG_ MXB_LED_90_Anf : 54|6@1+ (1.6,0) [1.6|100.8] "Unit_PerCent"  LED_DK3_LM_L,LED_LM_R,LLP_L,MXB_LM_R

BO_ 361 MXB_Soll_Fkt9: 8 BVS
 SG_ MXB_LED_91_Anf : 0|6@1+ (1.6,0) [1.6|100.8] "Unit_PerCent"  LED_DK3_LM_R,LLP_R
 SG_ MXB_LED_92_Anf : 6|6@1+ (1.6,0) [1.6|100.8] "Unit_PerCent"  LED_DK3_LM_R,LLP_R
 SG_ MXB_LED_93_Anf : 12|6@1+ (1.6,0) [1.6|100.8] "Unit_PerCent"  LED_DK3_LM_R,LLP_R
 SG_ MXB_LED_94_Anf : 18|6@1+ (1.6,0) [1.6|100.8] "Unit_PerCent"  LED_DK3_LM_R,LLP_R
 SG_ MXB_LED_95_Anf : 24|6@1+ (1.6,0) [1.6|100.8] "Unit_PerCent"  LED_DK3_LM_R,LLP_R
 SG_ MXB_LED_96_Anf : 30|6@1+ (1.6,0) [1.6|100.8] "Unit_PerCent"  LED_DK3_LM_R,LLP_R
 SG_ MXB_LED_97_Anf : 36|6@1+ (1.6,0) [1.6|100.8] "Unit_PerCent"  LED_DK3_LM_R,LLP_R
 SG_ MXB_LED_98_Anf : 42|6@1+ (1.6,0) [1.6|100.8] "Unit_PerCent"  LED_DK3_LM_R,LLP_R
 SG_ MXB_LED_99_Anf : 48|6@1+ (1.6,0) [1.6|100.8] "Unit_PerCent"  LED_DK3_LM_R,LLP_R
 SG_ MXB_LED_100_Anf : 54|6@1+ (1.6,0) [1.6|100.8] "Unit_PerCent"  LED_DK3_LM_R,LLP_R

BO_ 2549875330 OBDC_LCM_L_Req: 8 AFS
 SG_ OBDC_LCM_L_Req_Data : 0|64@1+ (1,0) [0|1.84467440737096E+019] ""  LCM_L

BO_ 2550006402 OBDC_LCM_L_Resp: 8 LCM_L
 SG_ OBDC_LCM_L_Resp_Data : 0|64@1+ (1,0) [0|1.84467440737096E+019] ""  AFS,BCM1,FCM,MXB

BO_ 2549875331 OBDC_LCM_R_Req: 8 AFS
 SG_ OBDC_LCM_R_Req_Data : 0|64@1+ (1,0) [0|1.84467440737096E+019] ""  LCM_R

BO_ 2550006403 OBDC_LCM_R_Resp: 8 LCM_R
 SG_ OBDC_LCM_R_Resp_Data : 0|64@1+ (1,0) [0|1.84467440737096E+019] ""  AFS,BCM1,FCM,MXB

BO_ 2549875350 OBDC_LED_LM_L_Req: 8 AFS
 SG_ OBDC_LED_LM_L_Req_Data : 0|64@1+ (1,0) [0|1.84467440737096E+019] ""  LED_DK3_LM_L,LED_LM_L,LLP_L

BO_ 2550006422 OBDC_LED_LM_L_Resp: 8 LED_DK3_LM_L
 SG_ OBDC_LED_LM_L_Resp_Data : 0|64@1+ (1,0) [0|1.84467440737096E+019] ""  AFS,BCM1,FCM,MXB

BO_ 2549875351 OBDC_LED_LM_R_Req: 8 AFS
 SG_ OBDC_LED_LM_R_Req_Data : 0|64@1+ (1,0) [0|1.84467440737096E+019] ""  LED_DK3_LM_R,LED_LM_R,LLP_R

BO_ 2550006423 OBDC_LED_LM_R_Resp: 8 LED_DK3_LM_R
 SG_ OBDC_LED_LM_R_Resp_Data : 0|64@1+ (1,0) [0|1.84467440737096E+019] ""  AFS,BCM1,FCM,MXB

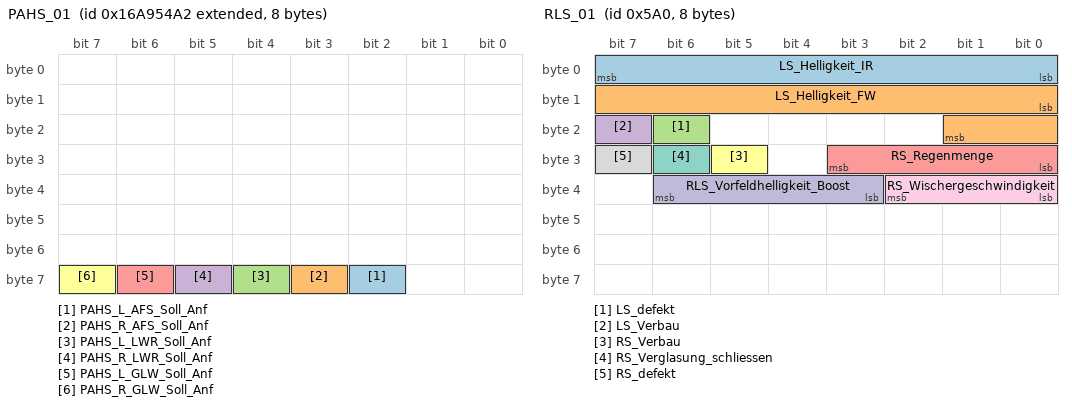
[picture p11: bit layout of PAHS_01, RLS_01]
BO_ 2527679650 PAHS_01: 8 ZFAS
 SG_ PAHS_L_AFS_Soll_Anf : 58|1@1+ (1,0) [0|1] ""  BCM1
 SG_ PAHS_R_AFS_Soll_Anf : 59|1@1+ (1,0) [0|1] ""  BCM1
 SG_ PAHS_L_LWR_Soll_Anf : 60|1@1+ (1,0) [0|1] ""  BCM1
 SG_ PAHS_R_LWR_Soll_Anf : 61|1@1+ (1,0) [0|1] ""  BCM1
 SG_ PAHS_L_GLW_Soll_Anf : 62|1@1+ (1,0) [0|1] ""  BCM1
 SG_ PAHS_R_GLW_Soll_Anf : 63|1@1+ (1,0) [0|1] ""  BCM1

BO_ 1440 RLS_01: 8 AFS
 SG_ LS_Helligkeit_IR : 0|8@1+ (400,0) [0|101200] "Unit_Lux" Vector__XXX
 SG_ LS_Helligkeit_FW : 8|10@1+ (6,0) [0|6126] "Unit_Lux"  LCM_L,LCM_R,LLP_L,LLP_R
 SG_ LS_defekt : 22|1@1+ (1,0) [0|1] "" Vector__XXX
 SG_ LS_Verbau : 23|1@1+ (1,0) [0|1] "" Vector__XXX
 SG_ RS_Regenmenge : 24|4@1+ (10,0) [0|100] "Unit_PerCent" Vector__XXX
 SG_ RS_Verbau : 29|1@1+ (1,0) [0|1] "" Vector__XXX
 SG_ RS_Verglasung_schliessen : 30|1@1+ (1,0) [0|1] "" Vector__XXX
 SG_ RS_defekt : 31|1@1+ (1,0) [0|1] "" Vector__XXX
 SG_ RS_Wischergeschwindigkeit : 32|3@1+ (1,0) [0|7] "" Vector__XXX
 SG_ RLS_Vorfeldhelligkeit_Boost : 35|4@1+ (1,0) [0|15] "" Vector__XXX

BO_ 1413 Systeminfo_01: 8 AFS
 SG_ SI_Sammel_SG_Fehler : 0|6@1+ (1,0) [0|60] "" Vector__XXX
 SG_ SI_Diagnose_Aktiv : 7|1@1+ (1,0) [0|1] "" Vector__XXX
 SG_ SI_QRS_Mode : 8|1@1+ (1,0) [0|1] "" Vector__XXX
 SG_ SI_T_Mode : 9|1@1+ (1,0) [0|1] "" Vector__XXX
 SG_ SI_NWDF : 10|1@1+ (1,0) [0|1] ""  LCM_L,LCM_R,LED_DK3_LM_L,LED_DK3_LM_R,LLP_L,LLP_R
 SG_ SI_NWDF_gueltig : 11|1@1+ (1,0) [0|1] ""  LCM_L,LCM_R,LED_DK3_LM_L,LED_DK3_LM_R,LLP_L,LLP_R
 SG_ SI_Sammelfehler : 12|1@1+ (1,0) [0|1] "" Vector__XXX
 SG_ GW_KD_Fehler : 13|1@1+ (1,0) [0|1] "" Vector__XXX
 SG_ SI_T_Schutz : 14|1@1+ (1,0) [0|1] "" Vector__XXX
 SG_ SI_BUS_01 : 16|1@1+ (1,0) [0|1] "" Vector__XXX
 SG_ SI_BUS_02 : 17|1@1+ (1,0) [0|1] "" Vector__XXX
 SG_ SI_BUS_03 : 18|1@1+ (1,0) [0|1] "" Vector__XXX
 SG_ SI_BUS_04 : 19|1@1+ (1,0) [0|1] "" Vector__XXX
 SG_ SI_BUS_05 : 20|1@1+ (1,0) [0|1] "" Vector__XXX
 SG_ SI_BUS_06 : 21|1@1+ (1,0) [0|1] "" Vector__XXX
 SG_ SI_BUS_07 : 22|1@1+ (1,0) [0|1] "" Vector__XXX
 SG_ SI_BUS_08 : 23|1@1+ (1,0) [0|1] "" Vector__XXX
 SG_ SI_BUS_09 : 24|1@1+ (1,0) [0|1] "" Vector__XXX
 SG_ SI_BUS_10 : 25|1@1+ (1,0) [0|1] "" Vector__XXX
 SG_ SI_BUS_11 : 26|1@1+ (1,0) [0|1] "" Vector__XXX
 SG_ SI_BUS_12 : 27|1@1+ (1,0) [0|1] "" Vector__XXX
 SG_ SI_BUS_13 : 28|1@1+ (1,0) [0|1] "" Vector__XXX
 SG_ SI_BUS_14 : 29|1@1+ (1,0) [0|1] "" Vector__XXX
 SG_ SI_BUS_15 : 30|1@1+ (1,0) [0|1] "" Vector__XXX
 SG_ SI_Bus_Identifikation : 32|8@1+ (1,0) [0|255] "" Vector__XXX

BO_ 2616989440 XCP_LCM_L_CRO_01: 8 Vector__XXX
 SG_ XCP_LCM_L_CRO_01_Data : 0|64@1+ (1,0) [0|1] ""  LCM_L

BO_ 2616989441 XCP_LCM_L_DTO_01: 8 LCM_L
 SG_ XCP_LCM_L_DTO_01_Data : 0|64@1+ (1,0) [0|1] "" Vector__XXX

BO_ 2616991488 XCP_LCM_R_CRO_01: 8 Vector__XXX
 SG_ XCP_LCM_R_CRO_01_Data : 0|64@1+ (1,0) [0|1] ""  LCM_R

BO_ 2616991489 XCP_LCM_R_DTO_01: 8 LCM_R
 SG_ XCP_LCM_R_DTO_01_Data : 0|64@1+ (1,0) [0|1] "" Vector__XXX

BO_ 2617030400 XCP_LED_DK3_L_CRO_01: 8 Vector__XXX
 SG_ XCP_LED_DK3_L_CRO_01_Data : 0|64@1+ (1,0) [0|1] ""  LED_DK3_LM_L,LLP_L

BO_ 2617030401 XCP_LED_DK3_L_DTO_01: 8 LED_DK3_LM_L
 SG_ XCP_LED_DK3_L_DTO_01_Data : 0|64@1+ (1,0) [0|1] "" Vector__XXX

BO_ 2617032448 XCP_LED_DK3_R_CRO_01: 8 Vector__XXX
 SG_ XCP_LED_DK3_R_CRO_01_Data : 0|64@1+ (1,0) [0|1] ""  LED_DK3_LM_R,LLP_R

BO_ 2617032449 XCP_LED_DK3_R_DTO_01: 8 LED_DK3_LM_R
 SG_ XCP_LED_DK3_R_DTO_01_Data : 0|64@1+ (1,0) [0|1] "" Vector__XXX

BO_TX_BU_ 1357 : LED_DK3_LM_R,LED_LM_R,LLP_R,LWR_MXB_R,MXB_LM_R;
BO_TX_BU_ 1438 : LED_LM_L,LWR_MXB_L,MXB_LM_L;
BO_TX_BU_ 1437 : LED_LM_R,LWR_MXB_R,MXB_LM_R;
BO_TX_BU_ 1306 : LED_LM_L,LWR_MXB_L,MXB_LM_L;
BO_TX_BU_ 1307 : LED_LM_R,LWR_MXB_R,MXB_LM_R;
BO_TX_BU_ 1405 : LED_LM_L,LWR_MXB_L,MXB_LM_L;
BO_TX_BU_ 2589283457 : LED_LM_L,LWR_MXB_L,MXB_LM_L;
BO_TX_BU_ 1406 : LED_LM_R,LWR_MXB_R,MXB_LM_R;
BO_TX_BU_ 2589283458 : LED_LM_R,LWR_MXB_R,MXB_LM_R;
BO_TX_BU_ 352 : AFS,BVS,FCM,MXB,ZFAS;
BO_TX_BU_ 353 : AFS,BVS,FCM,MXB,ZFAS;
BO_TX_BU_ 362 : BVS,MXB,ZFAS;
BO_TX_BU_ 363 : BVS,MXB,ZFAS;
BO_TX_BU_ 364 : BVS,MXB,ZFAS;
BO_TX_BU_ 365 : BVS,MXB,ZFAS;
BO_TX_BU_ 366 : BVS,MXB,ZFAS;
BO_TX_BU_ 367 : BVS,MXB,ZFAS;
BO_TX_BU_ 372 : BVS,MXB,ZFAS;
BO_TX_BU_ 373 : BVS,MXB,ZFAS;
BO_TX_BU_ 354 : AFS,BVS,FCM,MXB,ZFAS;
BO_TX_BU_ 355 : AFS,BVS,FCM,MXB,ZFAS;
BO_TX_BU_ 356 : AFS,BVS,FCM,MXB,ZFAS;
BO_TX_BU_ 357 : AFS,BVS,FCM,MXB,ZFAS;
BO_TX_BU_ 358 : AFS,BVS,FCM,MXB,ZFAS;
BO_TX_BU_ 359 : AFS,BVS,FCM,MXB,ZFAS;
BO_TX_BU_ 360 : AFS,BVS,FCM,MXB,ZFAS;
BO_TX_BU_ 361 : BVS,MXB,ZFAS;
BO_TX_BU_ 2549875330 : AFS,BCM1,FCM,MXB;
BO_TX_BU_ 2549875331 : AFS,BCM1,FCM,MXB;
BO_TX_BU_ 2549875350 : AFS,BCM1,FCM,MXB;
BO_TX_BU_ 2550006422 : LED_DK3_LM_L,LLP_L;
BO_TX_BU_ 2549875351 : AFS,BCM1,FCM,MXB;
BO_TX_BU_ 2550006423 : LED_DK3_LM_R,LLP_R;
BO_TX_BU_ 1440 : AFS,BCM1,FCM,MXB;
BO_TX_BU_ 1413 : AFS,BCM1,FCM,MXB;
BO_TX_BU_ 2617030401 : LED_DK3_LM_L,LLP_L;
BO_TX_BU_ 2617032449 : LED_DK3_LM_R,LLP_R;
CM_ SG_ 1357 MXB_R_Fernl_MXB_Def_1 "Unterspannung";
CM_ SG_ 1357 MXB_R_Fernl_MXB_Def_2 "Ueberspannung";
CM_ SG_ 1357 MXB_R_Fernl_MXB_Def_3 "Abweichung_CAN_Info_zu_Klemmenspg";
CM_ SG_ 1357 MXB_R_Fernl_MXB_Def_4 "Fehler_Stromcodierung";
CM_ SG_ 1357 MXB_R_Fernl_MXB_Def_5 "Fehler_Temperatursensor";
CM_ SG_ 1357 MXB_R_Fernl_MXB_Def_6 "Uebertemperatur";
CM_ SG_ 1357 MXB_R_Fernl_MXB_Def_7 "Fehler_Lichtfunktion";
CM_ SG_ 1357 MXB_R_Allg_Elektr_Def_1 "Fehler_Versorgungsspannung";
CM_ SG_ 1357 MXB_R_Allg_Elektr_Def_2 "Uebertemperatur";
CM_ SG_ 1357 MXB_R_Allg_Elektr_Def_3 "Fehler_RAM_Check";
CM_ SG_ 1357 MXB_R_Allg_Elektr_Def_4 "Fehler_ROM_Check";
CM_ SG_ 1357 MXB_R_Allg_Elektr_Def_5 "Fehler_EEPROM";
CM_ SG_ 1357 MXB_R_Allg_Elektr_Def_6 "Fehler_interner_Temperatursensor";
CM_ SG_ 1357 MXB_R_Allg_Elektr_Def_7 "Fehler_R_L_Erkennung";
CM_ SG_ 1357 MXB_R_Allg_Elektr_Def_8 "Sonstige_Fehler";
CM_ SG_ 1357 MXB_R_Luefter_1_Def_1 "Luefter_1_Open_Load";
CM_ SG_ 1357 MXB_R_Luefter_1_Def_2 "Luefter_1_Kurzschluss";
CM_ SG_ 1357 MXB_R_Luefter_1_Def_3 "Luefter_1_Unterspannung";
CM_ SG_ 1357 MXB_R_Luefter_1_Def_4 "Luefter_1_Ueberspannung";
CM_ SG_ 1357 MXB_R_Luefter_2_Def_1 "Luefter_2_Open_Load";
CM_ SG_ 1357 MXB_R_Luefter_2_Def_2 "Luefter_2_Kurzschluss";
CM_ SG_ 1357 MXB_R_Luefter_2_Def_3 "Luefter_2_Unterspannung";
CM_ SG_ 1357 MXB_R_Luefter_2_Def_4 "Luefter_2_Ueberspannung";
CM_ SG_ 1357 MXB_R_Allg_Elektr_Def "MXB-Leimo defekt";
CM_ SG_ 1357 MXB_R_Fernl_MXB_Def "MXB-Fernlicht defekt";
CM_ SG_ 1438 MXB_L_Mux "Durch Setzen der Multiplexer-IDENT Bits werden die einzelnen Bytes der Botschaft abgefragt ähnlich der Wegfahrsperre";
CM_ SG_ 1438 MXB_L_SW_Idt_Z01 "Software Ident Zeichen 1";
CM_ SG_ 1438 MXB_L_SW_Idt_Z08 "Software Ident Zeichen 8";
CM_ SG_ 1438 MXB_L_SW_Idx_Z04 "Software Idex Zeichen 4";
CM_ SG_ 1438 MXB_L_HW_Idt_Z07 "Hardware Ident Zeichen 1";
CM_ SG_ 1438 MXB_L_HW_Idx_Z03 "Hardware Index Zeichen 3";
CM_ SG_ 1438 MXB_L_SW_Idt_Z02 "Software Ident Zeichen 2";
CM_ SG_ 1438 MXB_L_SW_Idt_Z09 "Software Ident Zeichen 9";
CM_ SG_ 1438 MXB_L_HW_Idt_Z01 "Hardware Ident Zeichen 1";
CM_ SG_ 1438 MXB_L_HW_Idt_Z08 "Hardware Ident Zeichen 1";
CM_ SG_ 1438 MXB_L_SW_Idt_Z03 "Software Ident Zeichen 3";
CM_ SG_ 1438 MXB_L_SW_Idt_Z10 "Software Ident Zeichen 10";
CM_ SG_ 1438 MXB_L_HW_Idt_Z02 "Hardware Ident Zeichen 2";
CM_ SG_ 1438 MXB_L_HW_Idt_Z09 "Hardware Ident Zeichen 9";
CM_ SG_ 1438 MXB_L_SW_Idt_Z04 "Software Ident Zeichen 4";
CM_ SG_ 1438 MXB_L_SW_Idt_Z11 "Software Ident Zeichen 11";
CM_ SG_ 1438 MXB_L_HW_Idt_Z03 "Hardware Ident Zeichen 1";
CM_ SG_ 1438 MXB_L_HW_Idt_Z10 "Hardware Ident Zeichen 1";
CM_ SG_ 1438 MXB_L_SW_Idt_Z05 "Software Ident Zeichen 5";
CM_ SG_ 1438 MXB_L_SW_Idx_Z01 "Software Idex Zeichen 1";
CM_ SG_ 1438 MXB_L_HW_Idt_Z04 "Hardware Ident Zeichen 4";
CM_ SG_ 1438 MXB_L_HW_Idt_Z11 "Hardware Ident Zeichen 11";
CM_ SG_ 1438 MXB_L_SW_Idt_Z06 "Software Ident Zeichen 6";
CM_ SG_ 1438 MXB_L_SW_Idx_Z02 "Software Idex Zeichen 2";
CM_ SG_ 1438 MXB_L_HW_Idt_Z05 "Hardware Ident Zeichen 1";
CM_ SG_ 1438 MXB_L_HW_Idx_Z01 "Hardware Index Zeichen 1";
CM_ SG_ 1438 MXB_L_SW_Idt_Z07 "Software Ident Zeichen 7";
CM_ SG_ 1438 MXB_L_SW_Idx_Z03 "Software Idex Zeichen 3";
CM_ SG_ 1438 MXB_L_HW_Idt_Z06 "Hardware Ident Zeichen 6";
CM_ SG_ 1438 MXB_L_HW_Idx_Z02 "Hardware Index Zeichen 2";
CM_ SG_ 1437 MXB_R_Mux "Durch Setzen der Multiplexer-IDENT Bits werden die einzelnen Bytes der Botschaft abgefragt ähnlich der Wegfahrsperre";
CM_ SG_ 1437 MXB_R_SW_Idt_Z01 "Software Ident Zeichen 1";
CM_ SG_ 1437 MXB_R_SW_Idt_Z08 "Software Ident Zeichen 8";
CM_ SG_ 1437 MXB_R_SW_Idx_Z04 "Software Idex Zeichen 4";
CM_ SG_ 1437 MXB_R_HW_Idt_Z07 "Hardware Ident Zeichen 7";
CM_ SG_ 1437 MXB_R_HW_Idx_Z03 "Hardware Index Zeichen 3";
CM_ SG_ 1437 MXB_R_SW_Idt_Z02 "Software Ident Zeichen 2";
CM_ SG_ 1437 MXB_R_SW_Idt_Z09 "Software Ident Zeichen 9";
CM_ SG_ 1437 MXB_R_HW_Idt_Z01 "Hardware Ident Zeichen 1";
CM_ SG_ 1437 MXB_R_HW_Idt_Z08 "Hardware Ident Zeichen 8";
CM_ SG_ 1437 MXB_R_SW_Idt_Z03 "Software Ident Zeichen 3";
CM_ SG_ 1437 MXB_R_SW_Idt_Z10 "Software Ident Zeichen 10";
CM_ SG_ 1437 MXB_R_HW_Idt_Z02 "Hardware Ident Zeichen 2";
CM_ SG_ 1437 MXB_R_HW_Idt_Z09 "Hardware Ident Zeichen 9";
CM_ SG_ 1437 MXB_R_SW_Idt_Z04 "Software Ident Zeichen 4";
CM_ SG_ 1437 MXB_R_SW_Idt_Z11 "Software Ident Zeichen 11";
CM_ SG_ 1437 MXB_R_HW_Idt_Z03 "Hardware Ident Zeichen 3";
CM_ SG_ 1437 MXB_R_HW_Idt_Z10 "Hardware Ident Zeichen 10";
CM_ SG_ 1437 MXB_R_SW_Idt_Z05 "Software Ident Zeichen 5";
CM_ SG_ 1437 MXB_R_SW_Idx_Z01 "Software Idex Zeichen 1";
CM_ SG_ 1437 MXB_R_HW_Idt_Z04 "Hardware Ident Zeichen 4";
CM_ SG_ 1437 MXB_R_HW_Idt_Z11 "Hardware Ident Zeichen 11";
CM_ SG_ 1437 MXB_R_SW_Idt_Z06 "Software Ident Zeichen 6";
CM_ SG_ 1437 MXB_R_SW_Idx_Z02 "Software Idex Zeichen 2";
CM_ SG_ 1437 MXB_R_HW_Idt_Z05 "Hardware Ident Zeichen 5";
CM_ SG_ 1437 MXB_R_HW_Idx_Z01 "Hardware Index Zeichen 1";
CM_ SG_ 1437 MXB_R_SW_Idt_Z07 "Software Ident Zeichen 7";
CM_ SG_ 1437 MXB_R_SW_Idx_Z03 "Software Idex Zeichen 3";
CM_ SG_ 1437 MXB_R_HW_Idt_Z06 "Hardware Ident Zeichen 6";
CM_ SG_ 1437 MXB_R_HW_Idx_Z02 "Hardware Index Zeichen 2";
CM_ SG_ 1306 MXB_L_Scheinw_Var_1 "MXB_L_Scheinw_Var_1 und MXB_L_Scheinw_Var_2 bilden zusammen eine laufende Nummer zur Spezifierung der scheinwerfervarianten- abhängigen Codierung.

Die Scheinwerfervariante beinhaltet die firmenspezifische Funktionalität im Master!
Der Codierforgang wi";
CM_ SG_ 1306 MXB_L_Scheinw_Var_2 "MXB_L_Scheinw_Var_1 und MXB_L_Scheinw_Var_2 bilden zusammen eine laufende Nummer zur Spezifierung der scheinwerfervarianten- abhängigen Codierung.

Die Scheinwerfervariante beinhaltet die firmenspezifische Funktionalität im Master!
Der Codierforgang wi";
CM_ SG_ 1307 MXB_R_Scheinw_Var_1 "MXB_R_Scheinw_Var_1 und MXB_R_Scheinw_Var_2 bilden zusammen eine laufende Nummer zur Spezifierung der scheinwerfervarianten- abhängigen Codierung.

Die Scheinwerfervariante beinhaltet die firmenspezifische Funktionalität im Master!
Der Codierforgang wi";
CM_ SG_ 1307 MXB_R_Scheinw_Var_2 "MXB_R_Scheinw_Var_1 und MXB_R_Scheinw_Var_2 bilden zusammen eine laufende Nummer zur Spezifierung der scheinwerfervarianten- abhängigen Codierung.

Die Scheinwerfervariante beinhaltet die firmenspezifische Funktionalität im Master!
Der Codierforgang wi";
CM_ SG_ 1405 MXB_L_Temp_Abblendl "Temperaturwert an Hot Spot Abblendlicht";
CM_ SG_ 1405 MXB_L_Temp_Fernl "Temperaturwert an Hot Spot Fernlicht";
CM_ SG_ 1405 MXB_L_Temp_Elektronik "Temperaturwert an Hot Spot Elektronik";
CM_ SG_ 1405 MXB_L_Spannung_Klemme15 "Versorgungsspannung";
CM_ SG_ 1405 MXB_L_Fernl_Dimmung "Max. LED PWM Ansteuerung";
CM_ SG_ 1405 MXB_L_Fernl_Temp_Schutz "Temperatur-Schutz in einem der MXB-Fernlicht-Kanäle";
CM_ SG_ 1405 MXB_L_Fernl_Uspg_Schutz "Unterspannungs-Schutz in einem der MXB-Fernlicht-Kanäle";
CM_ SG_ 2589283457 MXB_L_Spannung_Kanal1 "Spannung am MXB-Kanal 1";
CM_ SG_ 2589283457 MXB_L_Spannung_Kanal2 "Spannung am MXB-Kanal 2";
CM_ SG_ 2589283457 MXB_L_Spannung_Kanal3 "Spannung am MXB-Kanal 3";
CM_ SG_ 2589283457 MXB_L_Strom_Kanal1 "Strom von MXB-Kanal 1";
CM_ SG_ 2589283457 MXB_L_Strom_Kanal2 "Strom von MXB-Kanal 2";
CM_ SG_ 2589283457 MXB_L_Strom_Kanal3 "Strom von MXB-Kanal 3";
CM_ SG_ 1406 MXB_R_Temp_Abblendl "Temperaturwert an Hot Spot Abblendlicht";
CM_ SG_ 1406 MXB_R_Temp_Fernl "Temperaturwert an Hot Spot Fernlicht";
CM_ SG_ 1406 MXB_R_Temp_Elektronik "Temperaturwert an Hot Spot Elektronik";
CM_ SG_ 1406 MXB_R_Spannung_Klemme15 "Versorgungsspannung";
CM_ SG_ 1406 MXB_R_Fernl_Dimmung "Max. LED PWM Ansteuerung";
CM_ SG_ 1406 MXB_R_Fernl_Temp_Schutz "Temperatur-Schutz in einem der MXB-Fernlicht-Kanäle";
CM_ SG_ 1406 MXB_R_Fernl_Uspg_Schutz "Unterspannungs-Schutz in einem der MXB-Fernlicht-Kanäle";
CM_ SG_ 2589283458 MXB_R_Spannung_Kanal1 "Spannung am MXB-Kanal 1";
CM_ SG_ 2589283458 MXB_R_Spannung_Kanal2 "Spannung am MXB-Kanal 2";
CM_ SG_ 2589283458 MXB_R_Spannung_Kanal3 "Spannung am MXB-Kanal 3";
CM_ SG_ 2589283458 MXB_R_Strom_Kanal1 "Strom von MXB-Kanal 1";
CM_ SG_ 2589283458 MXB_R_Strom_Kanal2 "Strom von MXB-Kanal 2";
CM_ SG_ 2589283458 MXB_R_Strom_Kanal3 "Strom von MXB-Kanal 3";
CM_ SG_ 352 MXB_LED_01_Anf "LED PWM Ansteuerung
Die Skalierung erfolgt von 0% - 100%  je nach Kennlinie im LEIMO";
CM_ SG_ 352 MXB_LED_02_Anf "LED PWM Ansteuerung
Die Skalierung erfolgt von 0% - 100%  je nach Kennlinie im LEIMO";
CM_ SG_ 352 MXB_LED_03_Anf "LED PWM Ansteuerung
Die Skalierung erfolgt von 0% - 100%  je nach Kennlinie im LEIMO";
CM_ SG_ 352 MXB_LED_04_Anf "LED PWM Ansteuerung
Die Skalierung erfolgt von 0% - 100%  je nach Kennlinie im LEIMO";
CM_ SG_ 352 MXB_LED_05_Anf "LED PWM Ansteuerung
Die Skalierung erfolgt von 0% - 100%  je nach Kennlinie im LEIMO";
CM_ SG_ 352 MXB_LED_06_Anf "LED PWM Ansteuerung
Die Skalierung erfolgt von 0% - 100%  je nach Kennlinie im LEIMO";
CM_ SG_ 352 MXB_LED_07_Anf "LED PWM Ansteuerung
Die Skalierung erfolgt von 0% - 100%  je nach Kennlinie im LEIMO";
CM_ SG_ 352 MXB_LED_08_Anf "LED PWM Ansteuerung
Die Skalierung erfolgt von 0% - 100%  je nach Kennlinie im LEIMO";
CM_ SG_ 352 MXB_LED_09_Anf "LED PWM Ansteuerung
Die Skalierung erfolgt von 0% - 100%  je nach Kennlinie im LEIMO";
CM_ SG_ 352 MXB_LED_10_Anf "LED PWM Ansteuerung
Die Skalierung erfolgt von 0% - 100%  je nach Kennlinie im LEIMO";
CM_ SG_ 353 MXB_LED_11_Anf "LED PWM Ansteuerung
Die Skalierung erfolgt von 0% - 100%  je nach Kennlinie im LEIMO";
CM_ SG_ 353 MXB_LED_12_Anf "LED PWM Ansteuerung
Die Skalierung erfolgt von 0% - 100%  je nach Kennlinie im LEIMO";
CM_ SG_ 353 MXB_LED_13_Anf "LED PWM Ansteuerung
Die Skalierung erfolgt von 0% - 100%  je nach Kennlinie im LEIMO";
CM_ SG_ 353 MXB_LED_14_Anf "LED PWM Ansteuerung
Die Skalierung erfolgt von 0% - 100%  je nach Kennlinie im LEIMO";
CM_ SG_ 353 MXB_LED_15_Anf "LED PWM Ansteuerung
Die Skalierung erfolgt von 0% - 100%  je nach Kennlinie im LEIMO";
CM_ SG_ 353 MXB_LED_16_Anf "LED PWM Ansteuerung
Die Skalierung erfolgt von 0% - 100%  je nach Kennlinie im LEIMO";
CM_ SG_ 353 MXB_LED_17_Anf "LED PWM Ansteuerung
Die Skalierung erfolgt von 0% - 100%  je nach Kennlinie im LEIMO";
CM_ SG_ 353 MXB_LED_18_Anf "LED PWM Ansteuerung
Die Skalierung erfolgt von 0% - 100%  je nach Kennlinie im LEIMO";
CM_ SG_ 353 MXB_LED_19_Anf "LED PWM Ansteuerung
Die Skalierung erfolgt von 0% - 100%  je nach Kennlinie im LEIMO";
CM_ SG_ 353 MXB_LED_20_Anf "LED PWM Ansteuerung
Die Skalierung erfolgt von 0% - 100%  je nach Kennlinie im LEIMO";
CM_ SG_ 362 MXB_LED_101_Anf "LED PWM Ansteuerung
Die Skalierung erfolgt von 0% - 100%  je nach Kennlinie im LEIMO";
CM_ SG_ 362 MXB_LED_102_Anf "LED PWM Ansteuerung
Die Skalierung erfolgt von 0% - 100%  je nach Kennlinie im LEIMO";
CM_ SG_ 362 MXB_LED_103_Anf "LED PWM Ansteuerung
Die Skalierung erfolgt von 0% - 100%  je nach Kennlinie im LEIMO";
CM_ SG_ 362 MXB_LED_104_Anf "LED PWM Ansteuerung
Die Skalierung erfolgt von 0% - 100%  je nach Kennlinie im LEIMO";
CM_ SG_ 362 MXB_LED_105_Anf "LED PWM Ansteuerung
Die Skalierung erfolgt von 0% - 100%  je nach Kennlinie im LEIMO";
CM_ SG_ 362 MXB_LED_106_Anf "LED PWM Ansteuerung
Die Skalierung erfolgt von 0% - 100%  je nach Kennlinie im LEIMO";
CM_ SG_ 362 MXB_LED_107_Anf "LED PWM Ansteuerung
Die Skalierung erfolgt von 0% - 100%  je nach Kennlinie im LEIMO";
CM_ SG_ 362 MXB_LED_108_Anf "LED PWM Ansteuerung
Die Skalierung erfolgt von 0% - 100%  je nach Kennlinie im LEIMO";
CM_ SG_ 362 MXB_LED_109_Anf "LED PWM Ansteuerung
Die Skalierung erfolgt von 0% - 100%  je nach Kennlinie im LEIMO";
CM_ SG_ 362 MXB_LED_110_Anf "LED PWM Ansteuerung
Die Skalierung erfolgt von 0% - 100%  je nach Kennlinie im LEIMO";
CM_ SG_ 363 MXB_LED_111_Anf "LED PWM Ansteuerung
Die Skalierung erfolgt von 0% - 100%  je nach Kennlinie im LEIMO";
CM_ SG_ 363 MXB_LED_112_Anf "LED PWM Ansteuerung
Die Skalierung erfolgt von 0% - 100%  je nach Kennlinie im LEIMO";
CM_ SG_ 363 MXB_LED_113_Anf "LED PWM Ansteuerung
Die Skalierung erfolgt von 0% - 100%  je nach Kennlinie im LEIMO";
CM_ SG_ 363 MXB_LED_114_Anf "LED PWM Ansteuerung
Die Skalierung erfolgt von 0% - 100%  je nach Kennlinie im LEIMO";
CM_ SG_ 363 MXB_LED_115_Anf "LED PWM Ansteuerung
Die Skalierung erfolgt von 0% - 100%  je nach Kennlinie im LEIMO";
CM_ SG_ 363 MXB_LED_116_Anf "LED PWM Ansteuerung
Die Skalierung erfolgt von 0% - 100%  je nach Kennlinie im LEIMO";
CM_ SG_ 363 MXB_LED_117_Anf "LED PWM Ansteuerung
Die Skalierung erfolgt von 0% - 100%  je nach Kennlinie im LEIMO";
CM_ SG_ 363 MXB_LED_118_Anf "LED PWM Ansteuerung
Die Skalierung erfolgt von 0% - 100%  je nach Kennlinie im LEIMO";
CM_ SG_ 363 MXB_LED_119_Anf "LED PWM Ansteuerung
Die Skalierung erfolgt von 0% - 100%  je nach Kennlinie im LEIMO";
CM_ SG_ 363 MXB_LED_120_Anf "LED PWM Ansteuerung
Die Skalierung erfolgt von 0% - 100%  je nach Kennlinie im LEIMO";
CM_ SG_ 364 MXB_LED_121_Anf "LED PWM Ansteuerung
Die Skalierung erfolgt von 0% - 100%  je nach Kennlinie im LEIMO";
CM_ SG_ 364 MXB_LED_122_Anf "LED PWM Ansteuerung
Die Skalierung erfolgt von 0% - 100%  je nach Kennlinie im LEIMO";
CM_ SG_ 364 MXB_LED_123_Anf "LED PWM Ansteuerung
Die Skalierung erfolgt von 0% - 100%  je nach Kennlinie im LEIMO";
CM_ SG_ 364 MXB_LED_124_Anf "LED PWM Ansteuerung
Die Skalierung erfolgt von 0% - 100%  je nach Kennlinie im LEIMO";
CM_ SG_ 364 MXB_LED_125_Anf "LED PWM Ansteuerung
Die Skalierung erfolgt von 0% - 100%  je nach Kennlinie im LEIMO";
CM_ SG_ 364 MXB_LED_126_Anf "LED PWM Ansteuerung
Die Skalierung erfolgt von 0% - 100%  je nach Kennlinie im LEIMO";
CM_ SG_ 364 MXB_LED_127_Anf "LED PWM Ansteuerung
Die Skalierung erfolgt von 0% - 100%  je nach Kennlinie im LEIMO";
CM_ SG_ 364 MXB_LED_128_Anf "LED PWM Ansteuerung
Die Skalierung erfolgt von 0% - 100%  je nach Kennlinie im LEIMO";
CM_ SG_ 364 MXB_LED_129_Anf "LED PWM Ansteuerung
Die Skalierung erfolgt von 0% - 100%  je nach Kennlinie im LEIMO";
CM_ SG_ 364 MXB_LED_130_Anf "LED PWM Ansteuerung
Die Skalierung erfolgt von 0% - 100%  je nach Kennlinie im LEIMO";
CM_ SG_ 365 MXB_LED_131_Anf "LED PWM Ansteuerung
Die Skalierung erfolgt von 0% - 100%  je nach Kennlinie im LEIMO";
CM_ SG_ 365 MXB_LED_132_Anf "LED PWM Ansteuerung
Die Skalierung erfolgt von 0% - 100%  je nach Kennlinie im LEIMO";
CM_ SG_ 365 MXB_LED_133_Anf "LED PWM Ansteuerung
Die Skalierung erfolgt von 0% - 100%  je nach Kennlinie im LEIMO";
CM_ SG_ 365 MXB_LED_134_Anf "LED PWM Ansteuerung
Die Skalierung erfolgt von 0% - 100%  je nach Kennlinie im LEIMO";
CM_ SG_ 365 MXB_LED_135_Anf "LED PWM Ansteuerung
Die Skalierung erfolgt von 0% - 100%  je nach Kennlinie im LEIMO";
CM_ SG_ 365 MXB_LED_136_Anf "LED PWM Ansteuerung
Die Skalierung erfolgt von 0% - 100%  je nach Kennlinie im LEIMO";
CM_ SG_ 365 MXB_LED_137_Anf "LED PWM Ansteuerung
Die Skalierung erfolgt von 0% - 100%  je nach Kennlinie im LEIMO";
CM_ SG_ 365 MXB_LED_138_Anf "LED PWM Ansteuerung
Die Skalierung erfolgt von 0% - 100%  je nach Kennlinie im LEIMO";
CM_ SG_ 365 MXB_LED_139_Anf "LED PWM Ansteuerung
Die Skalierung erfolgt von 0% - 100%  je nach Kennlinie im LEIMO";
CM_ SG_ 365 MXB_LED_140_Anf "LED PWM Ansteuerung
Die Skalierung erfolgt von 0% - 100%  je nach Kennlinie im LEIMO";
CM_ SG_ 366 MXB_LED_141_Anf "LED PWM Ansteuerung
Die Skalierung erfolgt von 0% - 100%  je nach Kennlinie im LEIMO";
CM_ SG_ 366 MXB_LED_142_Anf "LED PWM Ansteuerung
Die Skalierung erfolgt von 0% - 100%  je nach Kennlinie im LEIMO";
CM_ SG_ 366 MXB_LED_143_Anf "LED PWM Ansteuerung
Die Skalierung erfolgt von 0% - 100%  je nach Kennlinie im LEIMO";
CM_ SG_ 366 MXB_LED_144_Anf "LED PWM Ansteuerung
Die Skalierung erfolgt von 0% - 100%  je nach Kennlinie im LEIMO";
CM_ SG_ 366 MXB_LED_145_Anf "LED PWM Ansteuerung
Die Skalierung erfolgt von 0% - 100%  je nach Kennlinie im LEIMO";
CM_ SG_ 366 MXB_LED_146_Anf "LED PWM Ansteuerung
Die Skalierung erfolgt von 0% - 100%  je nach Kennlinie im LEIMO";
CM_ SG_ 366 MXB_LED_147_Anf "LED PWM Ansteuerung
Die Skalierung erfolgt von 0% - 100%  je nach Kennlinie im LEIMO";
CM_ SG_ 366 MXB_LED_148_Anf "LED PWM Ansteuerung
Die Skalierung erfolgt von 0% - 100%  je nach Kennlinie im LEIMO";
CM_ SG_ 366 MXB_LED_149_Anf "LED PWM Ansteuerung
Die Skalierung erfolgt von 0% - 100%  je nach Kennlinie im LEIMO";
CM_ SG_ 366 MXB_LED_150_Anf "LED PWM Ansteuerung
Die Skalierung erfolgt von 0% - 100%  je nach Kennlinie im LEIMO";
CM_ SG_ 367 MXB_LED_151_Anf "LED PWM Ansteuerung
Die Skalierung erfolgt von 0% - 100%  je nach Kennlinie im LEIMO";
CM_ SG_ 367 MXB_LED_152_Anf "LED PWM Ansteuerung
Die Skalierung erfolgt von 0% - 100%  je nach Kennlinie im LEIMO";
CM_ SG_ 367 MXB_LED_153_Anf "LED PWM Ansteuerung
Die Skalierung erfolgt von 0% - 100%  je nach Kennlinie im LEIMO";
CM_ SG_ 367 MXB_LED_154_Anf "LED PWM Ansteuerung
Die Skalierung erfolgt von 0% - 100%  je nach Kennlinie im LEIMO";
CM_ SG_ 367 MXB_LED_155_Anf "LED PWM Ansteuerung
Die Skalierung erfolgt von 0% - 100%  je nach Kennlinie im LEIMO";
CM_ SG_ 367 MXB_LED_156_Anf "LED PWM Ansteuerung
Die Skalierung erfolgt von 0% - 100%  je nach Kennlinie im LEIMO";
CM_ SG_ 367 MXB_LED_157_Anf "LED PWM Ansteuerung
Die Skalierung erfolgt von 0% - 100%  je nach Kennlinie im LEIMO";
CM_ SG_ 367 MXB_LED_158_Anf "LED PWM Ansteuerung
Die Skalierung erfolgt von 0% - 100%  je nach Kennlinie im LEIMO";
CM_ SG_ 367 MXB_LED_159_Anf "LED PWM Ansteuerung
Die Skalierung erfolgt von 0% - 100%  je nach Kennlinie im LEIMO";
CM_ SG_ 367 MXB_LED_160_Anf "LED PWM Ansteuerung
Die Skalierung erfolgt von 0% - 100%  je nach Kennlinie im LEIMO";
CM_ SG_ 372 MXB_LED_161_Anf "LED PWM Ansteuerung
Die Skalierung erfolgt von 0% - 100%  je nach Kennlinie im LEIMO";
CM_ SG_ 372 MXB_LED_162_Anf "LED PWM Ansteuerung
Die Skalierung erfolgt von 0% - 100%  je nach Kennlinie im LEIMO";
CM_ SG_ 372 MXB_LED_163_Anf "LED PWM Ansteuerung
Die Skalierung erfolgt von 0% - 100%  je nach Kennlinie im LEIMO";
CM_ SG_ 372 MXB_LED_164_Anf "LED PWM Ansteuerung
Die Skalierung erfolgt von 0% - 100%  je nach Kennlinie im LEIMO";
CM_ SG_ 372 MXB_LED_165_Anf "LED PWM Ansteuerung
Die Skalierung erfolgt von 0% - 100%  je nach Kennlinie im LEIMO";
CM_ SG_ 372 MXB_LED_166_Anf "LED PWM Ansteuerung
Die Skalierung erfolgt von 0% - 100%  je nach Kennlinie im LEIMO";
CM_ SG_ 372 MXB_LED_167_Anf "LED PWM Ansteuerung
Die Skalierung erfolgt von 0% - 100%  je nach Kennlinie im LEIMO";
CM_ SG_ 372 MXB_LED_168_Anf "LED PWM Ansteuerung
Die Skalierung erfolgt von 0% - 100%  je nach Kennlinie im LEIMO";
CM_ SG_ 372 MXB_LED_169_Anf "LED PWM Ansteuerung
Die Skalierung erfolgt von 0% - 100%  je nach Kennlinie im LEIMO";
CM_ SG_ 372 MXB_LED_170_Anf "LED PWM Ansteuerung
Die Skalierung erfolgt von 0% - 100%  je nach Kennlinie im LEIMO";
CM_ SG_ 373 MXB_LED_171_Anf "LED PWM Ansteuerung
Die Skalierung erfolgt von 0% - 100%  je nach Kennlinie im LEIMO";
CM_ SG_ 373 MXB_LED_172_Anf "LED PWM Ansteuerung
Die Skalierung erfolgt von 0% - 100%  je nach Kennlinie im LEIMO";
CM_ SG_ 373 MXB_LED_173_Anf "LED PWM Ansteuerung
Die Skalierung erfolgt von 0% - 100%  je nach Kennlinie im LEIMO";
CM_ SG_ 373 MXB_LED_174_Anf "LED PWM Ansteuerung
Die Skalierung erfolgt von 0% - 100%  je nach Kennlinie im LEIMO";
CM_ SG_ 373 MXB_LED_175_Anf "LED PWM Ansteuerung
Die Skalierung erfolgt von 0% - 100%  je nach Kennlinie im LEIMO";
CM_ SG_ 373 MXB_LED_176_Anf "LED PWM Ansteuerung
Die Skalierung erfolgt von 0% - 100%  je nach Kennlinie im LEIMO";
CM_ SG_ 373 MXB_LED_177_Anf "LED PWM Ansteuerung
Die Skalierung erfolgt von 0% - 100%  je nach Kennlinie im LEIMO";
CM_ SG_ 373 MXB_LED_178_Anf "LED PWM Ansteuerung
Die Skalierung erfolgt von 0% - 100%  je nach Kennlinie im LEIMO";
CM_ SG_ 373 MXB_LED_179_Anf "LED PWM Ansteuerung
Die Skalierung erfolgt von 0% - 100%  je nach Kennlinie im LEIMO";
CM_ SG_ 373 MXB_LED_180_Anf "LED PWM Ansteuerung
Die Skalierung erfolgt von 0% - 100%  je nach Kennlinie im LEIMO";
CM_ SG_ 354 MXB_LED_21_Anf "LED PWM Ansteuerung
Die Skalierung erfolgt von 0% - 100%  je nach Kennlinie im LEIMO";
CM_ SG_ 354 MXB_LED_22_Anf "LED PWM Ansteuerung
Die Skalierung erfolgt von 0% - 100%  je nach Kennlinie im LEIMO";
CM_ SG_ 354 MXB_LED_23_Anf "LED PWM Ansteuerung
Die Skalierung erfolgt von 0% - 100%  je nach Kennlinie im LEIMO";
CM_ SG_ 354 MXB_LED_24_Anf "LED PWM Ansteuerung
Die Skalierung erfolgt von 0% - 100%  je nach Kennlinie im LEIMO";
CM_ SG_ 354 MXB_LED_25_Anf "LED PWM Ansteuerung
Die Skalierung erfolgt von 0% - 100%  je nach Kennlinie im LEIMO";
CM_ SG_ 354 MXB_LED_26_Anf "LED PWM Ansteuerung
Die Skalierung erfolgt von 0% - 100%  je nach Kennlinie im LEIMO";
CM_ SG_ 354 MXB_LED_27_Anf "LED PWM Ansteuerung
Die Skalierung erfolgt von 0% - 100%  je nach Kennlinie im LEIMO";
CM_ SG_ 354 MXB_LED_28_Anf "LED PWM Ansteuerung
Die Skalierung erfolgt von 0% - 100%  je nach Kennlinie im LEIMO";
CM_ SG_ 354 MXB_LED_29_Anf "LED PWM Ansteuerung
Die Skalierung erfolgt von 0% - 100%  je nach Kennlinie im LEIMO";
CM_ SG_ 354 MXB_LED_30_Anf "LED PWM Ansteuerung
Die Skalierung erfolgt von 0% - 100%  je nach Kennlinie im LEIMO";
CM_ SG_ 355 MXB_LED_31_Anf "LED PWM Ansteuerung
Die Skalierung erfolgt von 0% - 100%  je nach Kennlinie im LEIMO";
CM_ SG_ 355 MXB_LED_32_Anf "LED PWM Ansteuerung
Die Skalierung erfolgt von 0% - 100%  je nach Kennlinie im LEIMO";
CM_ SG_ 355 MXB_LED_33_Anf "LED PWM Ansteuerung
Die Skalierung erfolgt von 0% - 100%  je nach Kennlinie im LEIMO";
CM_ SG_ 355 MXB_LED_34_Anf "LED PWM Ansteuerung
Die Skalierung erfolgt von 0% - 100%  je nach Kennlinie im LEIMO";
CM_ SG_ 355 MXB_LED_35_Anf "LED PWM Ansteuerung
Die Skalierung erfolgt von 0% - 100%  je nach Kennlinie im LEIMO";
CM_ SG_ 355 MXB_LED_36_Anf "LED PWM Ansteuerung
Die Skalierung erfolgt von 0% - 100%  je nach Kennlinie im LEIMO";
CM_ SG_ 355 MXB_LED_37_Anf "LED PWM Ansteuerung
Die Skalierung erfolgt von 0% - 100%  je nach Kennlinie im LEIMO";
CM_ SG_ 355 MXB_LED_38_Anf "LED PWM Ansteuerung
Die Skalierung erfolgt von 0% - 100%  je nach Kennlinie im LEIMO";
CM_ SG_ 355 MXB_LED_39_Anf "LED PWM Ansteuerung
Die Skalierung erfolgt von 0% - 100%  je nach Kennlinie im LEIMO";
CM_ SG_ 355 MXB_LED_40_Anf "LED PWM Ansteuerung
Die Skalierung erfolgt von 0% - 100%  je nach Kennlinie im LEIMO";
CM_ SG_ 356 MXB_LED_41_Anf "LED PWM Ansteuerung
Die Skalierung erfolgt von 0% - 100%  je nach Kennlinie im LEIMO";
CM_ SG_ 356 MXB_LED_42_Anf "LED PWM Ansteuerung
Die Skalierung erfolgt von 0% - 100%  je nach Kennlinie im LEIMO";
CM_ SG_ 356 MXB_LED_43_Anf "LED PWM Ansteuerung
Die Skalierung erfolgt von 0% - 100%  je nach Kennlinie im LEIMO";
CM_ SG_ 356 MXB_LED_44_Anf "LED PWM Ansteuerung
Die Skalierung erfolgt von 0% - 100%  je nach Kennlinie im LEIMO";
CM_ SG_ 356 MXB_LED_45_Anf "LED PWM Ansteuerung
Die Skalierung erfolgt von 0% - 100%  je nach Kennlinie im LEIMO";
CM_ SG_ 356 MXB_Sta_Diag "1010: Normalbetrieb: Diagnose nicht eingeleitet. Eine Umcodierung, Stellgliedtest, und Fehlerspeicherlöschen der Slaves ist über diese Bitreihenfolge verriegelt!
0101: Diagnosebetrieb. Diagnose mit VAS Tester läuft. Ein Stellgliedtest, und Fehlerspeicher";
CM_ SG_ 356 MXB_LED_46_Anf "LED PWM Ansteuerung
Die Skalierung erfolgt von 0% - 100%  je nach Kennlinie im LEIMO";
CM_ SG_ 356 MXB_LED_47_Anf "LED PWM Ansteuerung
Die Skalierung erfolgt von 0% - 100%  je nach Kennlinie im LEIMO";
CM_ SG_ 356 MXB_LED_48_Anf "LED PWM Ansteuerung
Die Skalierung erfolgt von 0% - 100%  je nach Kennlinie im LEIMO";
CM_ SG_ 356 MXB_LED_49_Anf "LED PWM Ansteuerung
Die Skalierung erfolgt von 0% - 100%  je nach Kennlinie im LEIMO";
CM_ SG_ 356 MXB_LED_50_Anf "LED PWM Ansteuerung
Die Skalierung erfolgt von 0% - 100%  je nach Kennlinie im LEIMO";
CM_ SG_ 357 MXB_LED_51_Anf "LED PWM Ansteuerung
Die Skalierung erfolgt von 0% - 100%  je nach Kennlinie im LEIMO";
CM_ SG_ 357 MXB_LED_52_Anf "LED PWM Ansteuerung
Die Skalierung erfolgt von 0% - 100%  je nach Kennlinie im LEIMO";
CM_ SG_ 357 MXB_LED_53_Anf "LED PWM Ansteuerung
Die Skalierung erfolgt von 0% - 100%  je nach Kennlinie im LEIMO";
CM_ SG_ 357 MXB_LED_54_Anf "LED PWM Ansteuerung
Die Skalierung erfolgt von 0% - 100%  je nach Kennlinie im LEIMO";
CM_ SG_ 357 MXB_LED_55_Anf "LED PWM Ansteuerung
Die Skalierung erfolgt von 0% - 100%  je nach Kennlinie im LEIMO";
CM_ SG_ 357 MXB_LED_56_Anf "LED PWM Ansteuerung
Die Skalierung erfolgt von 0% - 100%  je nach Kennlinie im LEIMO";
CM_ SG_ 357 MXB_LED_57_Anf "LED PWM Ansteuerung
Die Skalierung erfolgt von 0% - 100%  je nach Kennlinie im LEIMO";
CM_ SG_ 357 MXB_LED_58_Anf "LED PWM Ansteuerung
Die Skalierung erfolgt von 0% - 100%  je nach Kennlinie im LEIMO";
CM_ SG_ 357 MXB_LED_59_Anf "LED PWM Ansteuerung
Die Skalierung erfolgt von 0% - 100%  je nach Kennlinie im LEIMO";
CM_ SG_ 357 MXB_LED_60_Anf "LED PWM Ansteuerung
Die Skalierung erfolgt von 0% - 100%  je nach Kennlinie im LEIMO";
CM_ SG_ 358 MXB_LED_61_Anf "LED PWM Ansteuerung
Die Skalierung erfolgt von 0% - 100%  je nach Kennlinie im LEIMO";
CM_ SG_ 358 MXB_LED_62_Anf "LED PWM Ansteuerung
Die Skalierung erfolgt von 0% - 100%  je nach Kennlinie im LEIMO";
CM_ SG_ 358 MXB_LED_63_Anf "LED PWM Ansteuerung
Die Skalierung erfolgt von 0% - 100%  je nach Kennlinie im LEIMO";
CM_ SG_ 358 MXB_LED_64_Anf "LED PWM Ansteuerung
Die Skalierung erfolgt von 0% - 100%  je nach Kennlinie im LEIMO";
CM_ SG_ 358 MXB_LED_65_Anf "LED PWM Ansteuerung
Die Skalierung erfolgt von 0% - 100%  je nach Kennlinie im LEIMO";
CM_ SG_ 358 MXB_LED_66_Anf "LED PWM Ansteuerung
Die Skalierung erfolgt von 0% - 100%  je nach Kennlinie im LEIMO";
CM_ SG_ 358 MXB_LED_67_Anf "LED PWM Ansteuerung
Die Skalierung erfolgt von 0% - 100%  je nach Kennlinie im LEIMO";
CM_ SG_ 358 MXB_LED_68_Anf "LED PWM Ansteuerung
Die Skalierung erfolgt von 0% - 100%  je nach Kennlinie im LEIMO";
CM_ SG_ 358 MXB_LED_69_Anf "LED PWM Ansteuerung
Die Skalierung erfolgt von 0% - 100%  je nach Kennlinie im LEIMO";
CM_ SG_ 358 MXB_LED_70_Anf "LED PWM Ansteuerung
Die Skalierung erfolgt von 0% - 100%  je nach Kennlinie im LEIMO";
CM_ SG_ 359 MXB_LED_71_Anf "LED PWM Ansteuerung
Die Skalierung erfolgt von 0% - 100%  je nach Kennlinie im LEIMO";
CM_ SG_ 359 MXB_LED_72_Anf "LED PWM Ansteuerung
Die Skalierung erfolgt von 0% - 100%  je nach Kennlinie im LEIMO";
CM_ SG_ 359 MXB_LED_73_Anf "LED PWM Ansteuerung
Die Skalierung erfolgt von 0% - 100%  je nach Kennlinie im LEIMO";
CM_ SG_ 359 MXB_LED_74_Anf "LED PWM Ansteuerung
Die Skalierung erfolgt von 0% - 100%  je nach Kennlinie im LEIMO";
CM_ SG_ 359 MXB_LED_75_Anf "LED PWM Ansteuerung
Die Skalierung erfolgt von 0% - 100%  je nach Kennlinie im LEIMO";
CM_ SG_ 359 MXB_LED_76_Anf "LED PWM Ansteuerung
Die Skalierung erfolgt von 0% - 100%  je nach Kennlinie im LEIMO";
CM_ SG_ 359 MXB_LED_77_Anf "LED PWM Ansteuerung
Die Skalierung erfolgt von 0% - 100%  je nach Kennlinie im LEIMO";
CM_ SG_ 359 MXB_LED_78_Anf "LED PWM Ansteuerung
Die Skalierung erfolgt von 0% - 100%  je nach Kennlinie im LEIMO";
CM_ SG_ 359 MXB_LED_79_Anf "LED PWM Ansteuerung
Die Skalierung erfolgt von 0% - 100%  je nach Kennlinie im LEIMO";
CM_ SG_ 359 MXB_LED_80_Anf "LED PWM Ansteuerung
Die Skalierung erfolgt von 0% - 100%  je nach Kennlinie im LEIMO";
CM_ SG_ 360 MXB_LED_81_Anf "LED PWM Ansteuerung
Die Skalierung erfolgt von 0% - 100%  je nach Kennlinie im LEIMO";
CM_ SG_ 360 MXB_LED_82_Anf "LED PWM Ansteuerung
Die Skalierung erfolgt von 0% - 100%  je nach Kennlinie im LEIMO";
CM_ SG_ 360 MXB_LED_83_Anf "LED PWM Ansteuerung
Die Skalierung erfolgt von 0% - 100%  je nach Kennlinie im LEIMO";
CM_ SG_ 360 MXB_LED_84_Anf "LED PWM Ansteuerung
Die Skalierung erfolgt von 0% - 100%  je nach Kennlinie im LEIMO";
CM_ SG_ 360 MXB_LED_85_Anf "LED PWM Ansteuerung
Die Skalierung erfolgt von 0% - 100%  je nach Kennlinie im LEIMO";
CM_ SG_ 360 MXB_LED_86_Anf "LED PWM Ansteuerung
Die Skalierung erfolgt von 0% - 100%  je nach Kennlinie im LEIMO";
CM_ SG_ 360 MXB_LED_87_Anf "LED PWM Ansteuerung
Die Skalierung erfolgt von 0% - 100%  je nach Kennlinie im LEIMO";
CM_ SG_ 360 MXB_LED_88_Anf "LED PWM Ansteuerung
Die Skalierung erfolgt von 0% - 100%  je nach Kennlinie im LEIMO";
CM_ SG_ 360 MXB_LED_89_Anf "LED PWM Ansteuerung
Die Skalierung erfolgt von 0% - 100%  je nach Kennlinie im LEIMO";
CM_ SG_ 360 MXB_LED_90_Anf "LED PWM Ansteuerung
Die Skalierung erfolgt von 0% - 100%  je nach Kennlinie im LEIMO";
CM_ SG_ 361 MXB_LED_91_Anf "LED PWM Ansteuerung
Die Skalierung erfolgt von 0% - 100%  je nach Kennlinie im LEIMO";
CM_ SG_ 361 MXB_LED_92_Anf "LED PWM Ansteuerung
Die Skalierung erfolgt von 0% - 100%  je nach Kennlinie im LEIMO";
CM_ SG_ 361 MXB_LED_93_Anf "LED PWM Ansteuerung
Die Skalierung erfolgt von 0% - 100%  je nach Kennlinie im LEIMO";
CM_ SG_ 361 MXB_LED_94_Anf "LED PWM Ansteuerung
Die Skalierung erfolgt von 0% - 100%  je nach Kennlinie im LEIMO";
CM_ SG_ 361 MXB_LED_95_Anf "LED PWM Ansteuerung
Die Skalierung erfolgt von 0% - 100%  je nach Kennlinie im LEIMO";
CM_ SG_ 361 MXB_LED_96_Anf "LED PWM Ansteuerung
Die Skalierung erfolgt von 0% - 100%  je nach Kennlinie im LEIMO";
CM_ SG_ 361 MXB_LED_97_Anf "LED PWM Ansteuerung
Die Skalierung erfolgt von 0% - 100%  je nach Kennlinie im LEIMO";
CM_ SG_ 361 MXB_LED_98_Anf "LED PWM Ansteuerung
Die Skalierung erfolgt von 0% - 100%  je nach Kennlinie im LEIMO";
CM_ SG_ 361 MXB_LED_99_Anf "LED PWM Ansteuerung
Die Skalierung erfolgt von 0% - 100%  je nach Kennlinie im LEIMO";
CM_ SG_ 361 MXB_LED_100_Anf "LED PWM Ansteuerung
Die Skalierung erfolgt von 0% - 100%  je nach Kennlinie im LEIMO";
CM_ SG_ 2527679650 PAHS_L_AFS_Soll_Anf "PAHS Verstellanforderung für AFS";
CM_ SG_ 2527679650 PAHS_R_AFS_Soll_Anf "PAHS Verstellanforderung für AFS";
CM_ SG_ 2527679650 PAHS_L_LWR_Soll_Anf "PAHS Verstellanforderung für LWR";
CM_ SG_ 2527679650 PAHS_R_LWR_Soll_Anf "PAHS Verstellanforderung für LWR";
CM_ SG_ 2527679650 PAHS_L_GLW_Soll_Anf "PAHS Verstellanforderung für GLW";
CM_ SG_ 2527679650 PAHS_R_GLW_Soll_Anf "PAHS Verstellanforderung für GLW";
CM_ BO_ 1440 "8Byte ab MLBevo
LIN-CAN (1:1) Botschaften werden geroutet
-  wenn entsprechender Slave codiert ist
-  wenn fehlerfreie Kommunikation zum Slave besteht
-  bei fehlerhafter Kommunikation zum Slave wird die Botschaft für 4s mit den letzten gültigen Werte";
CM_ SG_ 1440 LS_defekt "Fehlererkennung Lichtsensor
";
CM_ SG_ 1440 LS_Verbau "Verbauinfo Lichtsensor
";
CM_ SG_ 1440 RS_Regenmenge "Regenmenge für intel. Heckleuchte ";
CM_ SG_ 1440 RS_Verbau "Verbauinfo Regensensor";
CM_ SG_ 1440 RS_Verglasung_schliessen "Anforderung: Verglasung schliessen
";
CM_ SG_ 1440 RS_defekt "Fehlererkennung Regensensor";
CM_ SG_ 1440 RS_Wischergeschwindigkeit "Wischergeschwindigkeit (Hübe/min)";
CM_ SG_ 1440 RLS_Vorfeldhelligkeit_Boost "erweiterte Helligkeitssensierung für HUD";
CM_ BO_ 1413 "MQB, MLBevo";
CM_ SG_ 1413 SI_Sammel_SG_Fehler "Anzahl der gesetzten KD-Fehler direkt angeschlossener Steuergeräte der DK3 und DK4 gemäß 80127.
Hinweis: Ein Subbusmaster stellt nur die gesammelte Information der an ihn angeschlossenen Steuergeräte der DK3 und DK4 zur Verfügung.

Für ServiceKey Auswe";
CM_ SG_ 1413 SI_Diagnose_Aktiv "Gibt an ob Diagnose-Botschaften empfangen werden und somit eine Diagnose aktiv ist.
MQB: Gibt an ob Diagnose-Bus Botschaften empfangen werden und somit eine Diagnose aktiv ist.";
CM_ SG_ 1413 SI_T_Mode "0x0: Transportmodus nicht aktiv
0x1: Transportmodus aktiv";
CM_ SG_ 1413 SI_NWDF "Netzwerk-Diagnose Freigebe zur zentralen Aktivierung der Netzwerkdiagnose";
CM_ SG_ 1413 SI_NWDF_gueltig "Gültigkeitsbit zu SI_NWDF gemäß Lastenheft: Zentrale Aktivierung Netzwerkdiagnose";
CM_ SG_ 1413 SI_Sammelfehler "Sammelfehlermeldung zur Anzeige im Kombi - siehe Spez. Sammelfehlermeldung
Hinweis: Einzelne Steuergeräte können zur Anpassung an den Produktionsprozess im Gateway auskodiert werden!";
CM_ SG_ 1413 GW_KD_Fehler "Kundendienstfehlerbit Gateway zur Anzeige eines im Gateway abgelegten Fehlerspeichereintrages.";
CM_ SG_ 1413 SI_T_Schutz "Transportschutz-Signal, das bei Transportmodus und Motorlauf aktiv bleibt
0x0: Transportschutz nicht aktiv
0x1: Transportschutz aktiv";
CM_ SG_ 1413 SI_BUS_01 "MQB/PQ26: ACAN
MLBevo: HCAN";
CM_ SG_ 1413 SI_BUS_02 "MQB: FCAN
MLBevo: Frei";
CM_ SG_ 1413 SI_BUS_03 "MQB/PQ26: KCAN
MLBevo: KCAN";
CM_ SG_ 1413 SI_BUS_04 "MQB: ICAN
MLBevo: ICAN";
CM_ SG_ 1413 SI_BUS_05 "MQB/PQ26: DiagCAN
MLBevo: DiagCAN";
CM_ SG_ 1413 SI_BUS_06 "MQB/PQ26: ECAN
MLBevo: ECAN";
CM_ SG_ 1413 SI_BUS_07 "MQB: LIN1 (Energie)
MLBevo: LIN1 (Energie)";
CM_ SG_ 1413 SI_BUS_08 "MQB: LIN2 (MFL)
MLBevo: LIN2 (MFL)";
CM_ SG_ 1413 SI_BUS_09 "MQB: LIN3 (unbelegt)
MLBevo: LIN3 (Energie2)";
CM_ SG_ 1413 SI_BUS_10 "MLBevo: Flexray";
CM_ SG_ 1413 SI_BUS_11 "MLBevo: Ethernet";
CM_ SG_ 1413 SI_BUS_12 "MQB: unbelegt
MLBevo: K2CAN";
CM_ SG_ 1413 SI_BUS_13 "MQB: unbelegt
MLBevo: DCAN";
CM_ SG_ 1413 SI_Bus_Identifikation "Das Signal identifiziert den Bus eindeutig. Das Signal ist konstant auf jedem Bus.
Der Signalwert entspricht dem Wert 'Busnummer' aus der VW80127 Gateway_component_list_databus_identification (0x2A2D) 'Bus-Identifier'.";
BA_DEF_ BO_  "DiagRequest" ENUM  "No","Yes";
BA_DEF_ BO_  "DiagResponse" ENUM  "No","Yes";
BA_DEF_ BO_  "DiagState" ENUM  "No","Yes";
BA_DEF_ BO_  "GenMsgChkConstant" HEX 0 4095;
BA_DEF_ BO_  "GenMsgCycleTime" INT 0 65535;
BA_DEF_ BO_  "GenMsgCycleTimeFast" INT 0 65535;
BA_DEF_ BO_  "GenMsgDelayTime" INT 0 100000;
BA_DEF_ BO_  "GenMsgILSupport" ENUM  "No","Yes";
BA_DEF_ BO_  "GenMsgNrOfRepetition" INT 0 100;
BA_DEF_ BO_  "GenMsgPDUConstants" STRING ;
BA_DEF_ BO_  "GenMsgSendType" ENUM  "Cyclic","not_used","not_used","not_used","not_used","not_used","not_used","IfActive","NoMsgSendType";
BA_DEF_ BO_  "GenMsgStartDelayTime" INT 0 100000;
BA_DEF_ BO_  "NmMessage" ENUM  "No","Yes";
BA_DEF_ BO_  "NmhMessage" ENUM  "No","Yes";
BA_DEF_ BO_  "MsgType" ENUM  "Application","NM ","NMH","TP2.0","ISO-TP ","BAP","EID","KS";
BA_DEF_ BO_  "VAGTP20_API" HEX 0 255;
BA_DEF_ BO_  "VAGTP20_DynConnection" ENUM  "No","Yes";
BA_DEF_ BO_  "VAGTP20_DynSetup" ENUM  "No","Yes";
BA_DEF_ BO_  "VAGTP20_StatConnection" ENUM  "No","Yes";
BA_DEF_ SG_  "GenSigActiveRepetitions" INT -2147483648 2147483647;
BA_DEF_ SG_  "GenSigSendType" ENUM  "Cyclic","OnWrite","OnWriteWithRepetition","OnChange","OnChangeWithRepetition","IfActive","IfActiveWithRepetition","NoSigSendType","OnChangeAndIfActive","OnChangeAndIfActiveWithRepetition";
BA_DEF_ SG_  "GenSigStartValue" INT -2147483648 2147483647;
BA_DEF_ SG_  "NWM-WakeupAllowed" ENUM  "No","Yes";
BA_DEF_ SG_  "GenSigFuncType" ENUM  "NoFunction","MsgCounter","CRC-8","XOR","XOR-2","DatedBit","SW-Kl15","CHK","Constant","Protocol","CRC-8-SAE_J1850";
BA_DEF_ SG_  "GenSigSwitchedByIgnition" ENUM  "No","Yes";
BA_DEF_ SG_  "Fehlerwert" HEX 0 2147483647;
BA_DEF_ SG_  "GenSigMissingSourceValue" HEX 0 2147483647;
BA_DEF_REL_ BU_SG_REL_  "GenSigTimeoutTime" INT 0 65535;
BA_DEF_DEF_  "DiagRequest" "No";
BA_DEF_DEF_  "DiagResponse" "No";
BA_DEF_DEF_  "DiagState" "No";
BA_DEF_DEF_  "GenMsgChkConstant" 0;
BA_DEF_DEF_  "GenMsgCycleTime" 0;
BA_DEF_DEF_  "GenMsgCycleTimeFast" 0;
BA_DEF_DEF_  "GenMsgDelayTime" 0;
BA_DEF_DEF_  "GenMsgILSupport" "No";
BA_DEF_DEF_  "GenMsgNrOfRepetition" 0;
BA_DEF_DEF_  "GenMsgPDUConstants" "";
BA_DEF_DEF_  "GenMsgSendType" "NoMsgSendType";
BA_DEF_DEF_  "GenMsgStartDelayTime" 0;
BA_DEF_DEF_  "NmMessage" "No";
BA_DEF_DEF_  "NmhMessage" "No";
BA_DEF_DEF_  "MsgType" "Application";
BA_DEF_DEF_  "VAGTP20_API" 0;
BA_DEF_DEF_  "VAGTP20_DynConnection" "No";
BA_DEF_DEF_  "VAGTP20_DynSetup" "No";
BA_DEF_DEF_  "VAGTP20_StatConnection" "No";
BA_DEF_DEF_  "GenSigActiveRepetitions" 0;
BA_DEF_DEF_  "GenSigSendType" "NoSigSendType";
BA_DEF_DEF_  "GenSigStartValue" 0;
BA_DEF_DEF_  "NWM-WakeupAllowed" "No";
BA_DEF_DEF_  "GenSigFuncType" "NoFunction";
BA_DEF_DEF_  "GenSigSwitchedByIgnition" "Yes";
BA_DEF_DEF_  "Fehlerwert" 0;
BA_DEF_DEF_  "GenSigMissingSourceValue" 0;
BA_DEF_DEF_REL_ "GenSigTimeoutTime" 0;
BA_ "GenMsgCycleTime" BO_ 1357 200;
BA_ "GenMsgILSupport" BO_ 1357 1;
BA_ "GenMsgSendType" BO_ 1357 0;
BA_ "GenMsgCycleTime" BO_ 1438 100;
BA_ "GenMsgILSupport" BO_ 1438 1;
BA_ "GenMsgSendType" BO_ 1438 0;
BA_ "GenMsgCycleTime" BO_ 1437 100;
BA_ "GenMsgILSupport" BO_ 1437 1;
BA_ "GenMsgSendType" BO_ 1437 0;
BA_ "GenMsgCycleTime" BO_ 1306 100;
BA_ "GenMsgILSupport" BO_ 1306 1;
BA_ "GenMsgSendType" BO_ 1306 0;
BA_ "GenMsgCycleTime" BO_ 1307 100;
BA_ "GenMsgILSupport" BO_ 1307 1;
BA_ "GenMsgSendType" BO_ 1307 0;
BA_ "GenMsgCycleTime" BO_ 1405 1000;
BA_ "GenMsgILSupport" BO_ 1405 1;
BA_ "GenMsgSendType" BO_ 1405 0;
BA_ "GenMsgCycleTime" BO_ 2589283457 1000;
BA_ "GenMsgILSupport" BO_ 2589283457 1;
BA_ "GenMsgSendType" BO_ 2589283457 0;
BA_ "GenMsgCycleTime" BO_ 1406 1000;
BA_ "GenMsgILSupport" BO_ 1406 1;
BA_ "GenMsgSendType" BO_ 1406 0;
BA_ "GenMsgCycleTime" BO_ 2589283458 1000;
BA_ "GenMsgILSupport" BO_ 2589283458 1;
BA_ "GenMsgSendType" BO_ 2589283458 0;
BA_ "GenMsgCycleTime" BO_ 352 200;
BA_ "GenMsgDelayTime" BO_ 352 20;
BA_ "GenMsgILSupport" BO_ 352 1;
BA_ "GenMsgSendType" BO_ 352 0;
BA_ "GenMsgCycleTime" BO_ 353 200;
BA_ "GenMsgDelayTime" BO_ 353 20;
BA_ "GenMsgILSupport" BO_ 353 1;
BA_ "GenMsgSendType" BO_ 353 0;
BA_ "GenMsgCycleTime" BO_ 362 200;
BA_ "GenMsgDelayTime" BO_ 362 20;
BA_ "GenMsgILSupport" BO_ 362 1;
BA_ "GenMsgSendType" BO_ 362 0;
BA_ "GenMsgStartDelayTime" BO_ 362 5;
BA_ "GenMsgCycleTime" BO_ 363 200;
BA_ "GenMsgDelayTime" BO_ 363 20;
BA_ "GenMsgILSupport" BO_ 363 1;
BA_ "GenMsgSendType" BO_ 363 0;
BA_ "GenMsgStartDelayTime" BO_ 363 5;
BA_ "GenMsgCycleTime" BO_ 364 200;
BA_ "GenMsgDelayTime" BO_ 364 20;
BA_ "GenMsgILSupport" BO_ 364 1;
BA_ "GenMsgSendType" BO_ 364 0;
BA_ "GenMsgStartDelayTime" BO_ 364 10;
BA_ "GenMsgCycleTime" BO_ 365 200;
BA_ "GenMsgDelayTime" BO_ 365 20;
BA_ "GenMsgILSupport" BO_ 365 1;
BA_ "GenMsgSendType" BO_ 365 0;
BA_ "GenMsgStartDelayTime" BO_ 365 10;
BA_ "GenMsgCycleTime" BO_ 366 200;
BA_ "GenMsgDelayTime" BO_ 366 20;
BA_ "GenMsgILSupport" BO_ 366 1;
BA_ "GenMsgSendType" BO_ 366 0;
BA_ "GenMsgStartDelayTime" BO_ 366 10;
BA_ "GenMsgCycleTime" BO_ 367 200;
BA_ "GenMsgDelayTime" BO_ 367 20;
BA_ "GenMsgILSupport" BO_ 367 1;
BA_ "GenMsgSendType" BO_ 367 0;
BA_ "GenMsgStartDelayTime" BO_ 367 10;
BA_ "GenMsgCycleTime" BO_ 372 200;
BA_ "GenMsgDelayTime" BO_ 372 20;
BA_ "GenMsgILSupport" BO_ 372 1;
BA_ "GenMsgSendType" BO_ 372 0;
BA_ "GenMsgStartDelayTime" BO_ 372 10;
BA_ "GenMsgCycleTime" BO_ 373 200;
BA_ "GenMsgDelayTime" BO_ 373 20;
BA_ "GenMsgILSupport" BO_ 373 1;
BA_ "GenMsgSendType" BO_ 373 0;
BA_ "GenMsgStartDelayTime" BO_ 373 10;
BA_ "GenMsgCycleTime" BO_ 354 200;
BA_ "GenMsgDelayTime" BO_ 354 20;
BA_ "GenMsgILSupport" BO_ 354 1;
BA_ "GenMsgSendType" BO_ 354 0;
BA_ "GenMsgCycleTime" BO_ 355 200;
BA_ "GenMsgDelayTime" BO_ 355 20;
BA_ "GenMsgILSupport" BO_ 355 1;
BA_ "GenMsgSendType" BO_ 355 0;
BA_ "GenMsgCycleTime" BO_ 356 200;
BA_ "GenMsgDelayTime" BO_ 356 20;
BA_ "GenMsgILSupport" BO_ 356 1;
BA_ "GenMsgSendType" BO_ 356 0;
BA_ "GenMsgCycleTime" BO_ 357 200;
BA_ "GenMsgDelayTime" BO_ 357 20;
BA_ "GenMsgILSupport" BO_ 357 1;
BA_ "GenMsgSendType" BO_ 357 0;
BA_ "GenMsgCycleTime" BO_ 358 200;
BA_ "GenMsgDelayTime" BO_ 358 20;
BA_ "GenMsgILSupport" BO_ 358 1;
BA_ "GenMsgSendType" BO_ 358 0;
BA_ "GenMsgStartDelayTime" BO_ 358 5;
BA_ "GenMsgCycleTime" BO_ 359 200;
BA_ "GenMsgDelayTime" BO_ 359 20;
BA_ "GenMsgILSupport" BO_ 359 1;
BA_ "GenMsgSendType" BO_ 359 0;
BA_ "GenMsgStartDelayTime" BO_ 359 5;
BA_ "GenMsgCycleTime" BO_ 360 200;
BA_ "GenMsgDelayTime" BO_ 360 20;
BA_ "GenMsgILSupport" BO_ 360 1;
BA_ "GenMsgSendType" BO_ 360 0;
BA_ "GenMsgStartDelayTime" BO_ 360 5;
BA_ "GenMsgCycleTime" BO_ 361 200;
BA_ "GenMsgDelayTime" BO_ 361 20;
BA_ "GenMsgILSupport" BO_ 361 1;
BA_ "GenMsgSendType" BO_ 361 0;
BA_ "GenMsgStartDelayTime" BO_ 361 5;
BA_ "MsgType" BO_ 2549875330 4;
BA_ "MsgType" BO_ 2550006402 4;
BA_ "MsgType" BO_ 2549875331 4;
BA_ "MsgType" BO_ 2550006403 4;
BA_ "MsgType" BO_ 2549875350 4;
BA_ "MsgType" BO_ 2550006422 4;
BA_ "MsgType" BO_ 2549875351 4;
BA_ "MsgType" BO_ 2550006423 4;
BA_ "GenMsgCycleTime" BO_ 2527679650 1000;
BA_ "GenMsgDelayTime" BO_ 2527679650 100;
BA_ "GenMsgILSupport" BO_ 2527679650 1;
BA_ "GenMsgSendType" BO_ 2527679650 0;
BA_ "GenMsgCycleTime" BO_ 1440 200;
BA_ "GenMsgILSupport" BO_ 1440 1;
BA_ "GenMsgSendType" BO_ 1440 0;
BA_ "GenMsgCycleTime" BO_ 1413 1000;
BA_ "GenMsgDelayTime" BO_ 1413 10;
BA_ "GenMsgILSupport" BO_ 1413 1;
BA_ "GenMsgSendType" BO_ 1413 0;
BA_ "MsgType" BO_ 2616989440 6;
BA_ "MsgType" BO_ 2616989441 6;
BA_ "MsgType" BO_ 2616991488 6;
BA_ "MsgType" BO_ 2616991489 6;
BA_ "MsgType" BO_ 2617030400 6;
BA_ "MsgType" BO_ 2617030401 6;
BA_ "MsgType" BO_ 2617032448 6;
BA_ "MsgType" BO_ 2617032449 6;
BA_ "GenSigSendType" SG_ 1357 MXB_R_Fernl_MXB_Def_1 0;
BA_ "Fehlerwert" SG_ 1357 MXB_R_Fernl_MXB_Def_1 1;
BA_ "GenSigSendType" SG_ 1357 MXB_R_Fernl_MXB_Def_2 0;
BA_ "Fehlerwert" SG_ 1357 MXB_R_Fernl_MXB_Def_2 1;
BA_ "GenSigSendType" SG_ 1357 MXB_R_Fernl_MXB_Def_3 0;
BA_ "Fehlerwert" SG_ 1357 MXB_R_Fernl_MXB_Def_3 1;
BA_ "GenSigSendType" SG_ 1357 MXB_R_Fernl_MXB_Def_4 0;
BA_ "Fehlerwert" SG_ 1357 MXB_R_Fernl_MXB_Def_4 1;
BA_ "GenSigSendType" SG_ 1357 MXB_R_Fernl_MXB_Def_5 0;
BA_ "Fehlerwert" SG_ 1357 MXB_R_Fernl_MXB_Def_5 1;
BA_ "GenSigSendType" SG_ 1357 MXB_R_Fernl_MXB_Def_6 0;
BA_ "Fehlerwert" SG_ 1357 MXB_R_Fernl_MXB_Def_6 1;
BA_ "GenSigSendType" SG_ 1357 MXB_R_Fernl_MXB_Def_7 0;
BA_ "Fehlerwert" SG_ 1357 MXB_R_Fernl_MXB_Def_7 1;
BA_ "GenSigSendType" SG_ 1357 MXB_R_Fernl_MXB_Def_Err_Gultig 0;
BA_ "GenSigSendType" SG_ 1357 MXB_R_Allg_Elektr_Def_1 0;
BA_ "Fehlerwert" SG_ 1357 MXB_R_Allg_Elektr_Def_1 1;
BA_ "GenSigSendType" SG_ 1357 MXB_R_Allg_Elektr_Def_2 0;
BA_ "Fehlerwert" SG_ 1357 MXB_R_Allg_Elektr_Def_2 1;
BA_ "GenSigSendType" SG_ 1357 MXB_R_Allg_Elektr_Def_3 0;
BA_ "Fehlerwert" SG_ 1357 MXB_R_Allg_Elektr_Def_3 1;
BA_ "GenSigSendType" SG_ 1357 MXB_R_Allg_Elektr_Def_4 0;
BA_ "Fehlerwert" SG_ 1357 MXB_R_Allg_Elektr_Def_4 1;
BA_ "GenSigSendType" SG_ 1357 MXB_R_Allg_Elektr_Def_5 0;
BA_ "Fehlerwert" SG_ 1357 MXB_R_Allg_Elektr_Def_5 1;
BA_ "GenSigSendType" SG_ 1357 MXB_R_Allg_Elektr_Def_6 0;
BA_ "Fehlerwert" SG_ 1357 MXB_R_Allg_Elektr_Def_6 1;
BA_ "GenSigSendType" SG_ 1357 MXB_R_Allg_Elektr_Def_7 0;
BA_ "Fehlerwert" SG_ 1357 MXB_R_Allg_Elektr_Def_7 1;
BA_ "GenSigSendType" SG_ 1357 MXB_R_Allg_Elektr_Def_8 0;
BA_ "Fehlerwert" SG_ 1357 MXB_R_Allg_Elektr_Def_8 1;
BA_ "GenSigSendType" SG_ 1357 MXB_R_Allg_Elektr_Def_Err_Gultig 0;
BA_ "GenSigSendType" SG_ 1357 MXB_R_Luefter_1_Def_1 0;
BA_ "Fehlerwert" SG_ 1357 MXB_R_Luefter_1_Def_1 1;
BA_ "GenSigSendType" SG_ 1357 MXB_R_Luefter_1_Def_2 0;
BA_ "Fehlerwert" SG_ 1357 MXB_R_Luefter_1_Def_2 1;
BA_ "GenSigSendType" SG_ 1357 MXB_R_Luefter_1_Def_3 0;
BA_ "Fehlerwert" SG_ 1357 MXB_R_Luefter_1_Def_3 1;
BA_ "GenSigSendType" SG_ 1357 MXB_R_Luefter_1_Def_4 0;
BA_ "Fehlerwert" SG_ 1357 MXB_R_Luefter_1_Def_4 1;
BA_ "GenSigSendType" SG_ 1357 MXB_R_Luefter_2_Def_1 0;
BA_ "Fehlerwert" SG_ 1357 MXB_R_Luefter_2_Def_1 1;
BA_ "GenSigSendType" SG_ 1357 MXB_R_Luefter_2_Def_2 0;
BA_ "Fehlerwert" SG_ 1357 MXB_R_Luefter_2_Def_2 1;
BA_ "GenSigSendType" SG_ 1357 MXB_R_Luefter_2_Def_3 0;
BA_ "Fehlerwert" SG_ 1357 MXB_R_Luefter_2_Def_3 1;
BA_ "GenSigSendType" SG_ 1357 MXB_R_Luefter_2_Def_4 0;
BA_ "Fehlerwert" SG_ 1357 MXB_R_Luefter_2_Def_4 1;
BA_ "GenSigSendType" SG_ 1357 MXB_R_Luefter_1_Def_Err_Gultig 0;
BA_ "GenSigSendType" SG_ 1357 MXB_R_Luefter_2_Def_Err_Gultig 0;
BA_ "GenSigSendType" SG_ 1357 MXB_R_Allg_Elektr_Def 0;
BA_ "GenSigSendType" SG_ 1357 MXB_R_Fernl_MXB_Def 0;
BA_ "GenSigSendType" SG_ 1438 MXB_L_Mux 0;
BA_ "GenSigSendType" SG_ 1437 MXB_R_Mux 0;
BA_ "GenSigSendType" SG_ 1306 MXB_L_Scheinw_Var_1 0;
BA_ "GenSigSendType" SG_ 1306 MXB_L_Scheinw_Var_2 0;
BA_ "GenSigSendType" SG_ 1307 MXB_R_Scheinw_Var_1 0;
BA_ "GenSigSendType" SG_ 1307 MXB_R_Scheinw_Var_2 0;
BA_ "GenSigSendType" SG_ 1405 MXB_L_Temp_Abblendl 0;
BA_ "Fehlerwert" SG_ 1405 MXB_L_Temp_Abblendl 255;
BA_ "GenSigSendType" SG_ 1405 MXB_L_Temp_Fernl 0;
BA_ "Fehlerwert" SG_ 1405 MXB_L_Temp_Fernl 255;
BA_ "GenSigSendType" SG_ 1405 MXB_L_Temp_Elektronik 0;
BA_ "Fehlerwert" SG_ 1405 MXB_L_Temp_Elektronik 255;
BA_ "GenSigSendType" SG_ 1405 MXB_L_Spannung_Klemme15 0;
BA_ "Fehlerwert" SG_ 1405 MXB_L_Spannung_Klemme15 255;
BA_ "GenSigSendType" SG_ 1405 MXB_L_Fernl_Dimmung 0;
BA_ "GenSigSendType" SG_ 1405 MXB_L_Fernl_Temp_Schutz 0;
BA_ "GenSigSendType" SG_ 1405 MXB_L_Fernl_Uspg_Schutz 0;
BA_ "GenSigSendType" SG_ 2589283457 MXB_L_Spannung_Kanal1 0;
BA_ "Fehlerwert" SG_ 2589283457 MXB_L_Spannung_Kanal1 255;
BA_ "GenSigSendType" SG_ 2589283457 MXB_L_Spannung_Kanal2 0;
BA_ "Fehlerwert" SG_ 2589283457 MXB_L_Spannung_Kanal2 255;
BA_ "GenSigSendType" SG_ 2589283457 MXB_L_Spannung_Kanal3 0;
BA_ "Fehlerwert" SG_ 2589283457 MXB_L_Spannung_Kanal3 255;
BA_ "GenSigSendType" SG_ 2589283457 MXB_L_Strom_Kanal1 0;
BA_ "GenSigStartValue" SG_ 2589283457 MXB_L_Strom_Kanal1 1021;
BA_ "Fehlerwert" SG_ 2589283457 MXB_L_Strom_Kanal1 1023;
BA_ "GenSigSendType" SG_ 2589283457 MXB_L_Strom_Kanal2 0;
BA_ "GenSigStartValue" SG_ 2589283457 MXB_L_Strom_Kanal2 1021;
BA_ "Fehlerwert" SG_ 2589283457 MXB_L_Strom_Kanal2 1023;
BA_ "GenSigSendType" SG_ 2589283457 MXB_L_Strom_Kanal3 0;
BA_ "GenSigStartValue" SG_ 2589283457 MXB_L_Strom_Kanal3 1021;
BA_ "Fehlerwert" SG_ 2589283457 MXB_L_Strom_Kanal3 1023;
BA_ "GenSigSendType" SG_ 1406 MXB_R_Temp_Abblendl 0;
BA_ "Fehlerwert" SG_ 1406 MXB_R_Temp_Abblendl 255;
BA_ "GenSigSendType" SG_ 1406 MXB_R_Temp_Fernl 0;
BA_ "Fehlerwert" SG_ 1406 MXB_R_Temp_Fernl 255;
BA_ "GenSigSendType" SG_ 1406 MXB_R_Temp_Elektronik 0;
BA_ "Fehlerwert" SG_ 1406 MXB_R_Temp_Elektronik 255;
BA_ "GenSigSendType" SG_ 1406 MXB_R_Spannung_Klemme15 0;
BA_ "Fehlerwert" SG_ 1406 MXB_R_Spannung_Klemme15 255;
BA_ "GenSigSendType" SG_ 1406 MXB_R_Fernl_Dimmung 0;
BA_ "GenSigSendType" SG_ 1406 MXB_R_Fernl_Temp_Schutz 0;
BA_ "GenSigSendType" SG_ 1406 MXB_R_Fernl_Uspg_Schutz 0;
BA_ "GenSigSendType" SG_ 2589283458 MXB_R_Spannung_Kanal1 0;
BA_ "GenSigStartValue" SG_ 2589283458 MXB_R_Spannung_Kanal1 253;
BA_ "Fehlerwert" SG_ 2589283458 MXB_R_Spannung_Kanal1 255;
BA_ "GenSigSendType" SG_ 2589283458 MXB_R_Spannung_Kanal2 0;
BA_ "GenSigStartValue" SG_ 2589283458 MXB_R_Spannung_Kanal2 253;
BA_ "Fehlerwert" SG_ 2589283458 MXB_R_Spannung_Kanal2 255;
BA_ "GenSigSendType" SG_ 2589283458 MXB_R_Spannung_Kanal3 0;
BA_ "GenSigStartValue" SG_ 2589283458 MXB_R_Spannung_Kanal3 253;
BA_ "Fehlerwert" SG_ 2589283458 MXB_R_Spannung_Kanal3 255;
BA_ "GenSigSendType" SG_ 2589283458 MXB_R_Strom_Kanal1 0;
BA_ "GenSigStartValue" SG_ 2589283458 MXB_R_Strom_Kanal1 1021;
BA_ "Fehlerwert" SG_ 2589283458 MXB_R_Strom_Kanal1 1023;
BA_ "GenSigSendType" SG_ 2589283458 MXB_R_Strom_Kanal2 0;
BA_ "GenSigStartValue" SG_ 2589283458 MXB_R_Strom_Kanal2 1021;
BA_ "Fehlerwert" SG_ 2589283458 MXB_R_Strom_Kanal2 1023;
BA_ "GenSigSendType" SG_ 2589283458 MXB_R_Strom_Kanal3 0;
BA_ "GenSigStartValue" SG_ 2589283458 MXB_R_Strom_Kanal3 1021;
BA_ "Fehlerwert" SG_ 2589283458 MXB_R_Strom_Kanal3 1023;
BA_ "GenSigSendType" SG_ 352 MXB_LED_01_Anf 3;
BA_ "GenSigSendType" SG_ 352 MXB_LED_02_Anf 3;
BA_ "GenSigSendType" SG_ 352 MXB_LED_03_Anf 3;
BA_ "GenSigSendType" SG_ 352 MXB_LED_04_Anf 3;
BA_ "GenSigSendType" SG_ 352 MXB_LED_05_Anf 3;
BA_ "GenSigSendType" SG_ 352 MXB_LED_06_Anf 3;
BA_ "GenSigSendType" SG_ 352 MXB_LED_07_Anf 3;
BA_ "GenSigSendType" SG_ 352 MXB_LED_08_Anf 3;
BA_ "GenSigSendType" SG_ 352 MXB_LED_09_Anf 3;
BA_ "GenSigSendType" SG_ 352 MXB_LED_10_Anf 3;
BA_ "GenSigSendType" SG_ 353 MXB_LED_11_Anf 3;
BA_ "GenSigSendType" SG_ 353 MXB_LED_12_Anf 3;
BA_ "GenSigSendType" SG_ 353 MXB_LED_13_Anf 3;
BA_ "GenSigSendType" SG_ 353 MXB_LED_14_Anf 3;
BA_ "GenSigSendType" SG_ 353 MXB_LED_15_Anf 3;
BA_ "GenSigSendType" SG_ 353 MXB_LED_16_Anf 3;
BA_ "GenSigSendType" SG_ 353 MXB_LED_17_Anf 3;
BA_ "GenSigSendType" SG_ 353 MXB_LED_18_Anf 3;
BA_ "GenSigSendType" SG_ 353 MXB_LED_19_Anf 3;
BA_ "GenSigSendType" SG_ 353 MXB_LED_20_Anf 3;
BA_ "GenSigSendType" SG_ 362 MXB_LED_101_Anf 3;
BA_ "GenSigSendType" SG_ 362 MXB_LED_102_Anf 3;
BA_ "GenSigSendType" SG_ 362 MXB_LED_103_Anf 3;
BA_ "GenSigSendType" SG_ 362 MXB_LED_104_Anf 3;
BA_ "GenSigSendType" SG_ 362 MXB_LED_105_Anf 3;
BA_ "GenSigSendType" SG_ 362 MXB_LED_106_Anf 3;
BA_ "GenSigSendType" SG_ 362 MXB_LED_107_Anf 3;
BA_ "GenSigSendType" SG_ 362 MXB_LED_108_Anf 3;
BA_ "GenSigSendType" SG_ 362 MXB_LED_109_Anf 3;
BA_ "GenSigSendType" SG_ 362 MXB_LED_110_Anf 3;
BA_ "GenSigSendType" SG_ 363 MXB_LED_111_Anf 3;
BA_ "GenSigSendType" SG_ 363 MXB_LED_112_Anf 3;
BA_ "GenSigSendType" SG_ 363 MXB_LED_113_Anf 3;
BA_ "GenSigSendType" SG_ 363 MXB_LED_114_Anf 3;
BA_ "GenSigSendType" SG_ 363 MXB_LED_115_Anf 3;
BA_ "GenSigSendType" SG_ 363 MXB_LED_116_Anf 3;
BA_ "GenSigSendType" SG_ 363 MXB_LED_117_Anf 3;
BA_ "GenSigSendType" SG_ 363 MXB_LED_118_Anf 3;
BA_ "GenSigSendType" SG_ 363 MXB_LED_119_Anf 3;
BA_ "GenSigSendType" SG_ 363 MXB_LED_120_Anf 3;
BA_ "GenSigSendType" SG_ 364 MXB_LED_121_Anf 3;
BA_ "GenSigSendType" SG_ 364 MXB_LED_122_Anf 3;
BA_ "GenSigSendType" SG_ 364 MXB_LED_123_Anf 3;
BA_ "GenSigSendType" SG_ 364 MXB_LED_124_Anf 3;
BA_ "GenSigSendType" SG_ 364 MXB_LED_125_Anf 3;
BA_ "GenSigSendType" SG_ 364 MXB_LED_126_Anf 3;
BA_ "GenSigSendType" SG_ 364 MXB_LED_127_Anf 3;
BA_ "GenSigSendType" SG_ 364 MXB_LED_128_Anf 3;
BA_ "GenSigSendType" SG_ 364 MXB_LED_129_Anf 3;
BA_ "GenSigSendType" SG_ 364 MXB_LED_130_Anf 3;
BA_ "GenSigSendType" SG_ 365 MXB_LED_131_Anf 3;
BA_ "GenSigSendType" SG_ 365 MXB_LED_132_Anf 3;
BA_ "GenSigSendType" SG_ 365 MXB_LED_133_Anf 3;
BA_ "GenSigSendType" SG_ 365 MXB_LED_134_Anf 3;
BA_ "GenSigSendType" SG_ 365 MXB_LED_135_Anf 3;
BA_ "GenSigSendType" SG_ 365 MXB_LED_136_Anf 3;
BA_ "GenSigSendType" SG_ 365 MXB_LED_137_Anf 3;
BA_ "GenSigSendType" SG_ 365 MXB_LED_138_Anf 3;
BA_ "GenSigSendType" SG_ 365 MXB_LED_139_Anf 3;
BA_ "GenSigSendType" SG_ 365 MXB_LED_140_Anf 3;
BA_ "GenSigSendType" SG_ 366 MXB_LED_141_Anf 3;
BA_ "GenSigSendType" SG_ 366 MXB_LED_142_Anf 3;
BA_ "GenSigSendType" SG_ 366 MXB_LED_143_Anf 3;
BA_ "GenSigSendType" SG_ 366 MXB_LED_144_Anf 3;
BA_ "GenSigSendType" SG_ 366 MXB_LED_145_Anf 3;
BA_ "GenSigSendType" SG_ 366 MXB_LED_146_Anf 3;
BA_ "GenSigSendType" SG_ 366 MXB_LED_147_Anf 3;
BA_ "GenSigSendType" SG_ 366 MXB_LED_148_Anf 3;
BA_ "GenSigSendType" SG_ 366 MXB_LED_149_Anf 3;
BA_ "GenSigSendType" SG_ 366 MXB_LED_150_Anf 3;
BA_ "GenSigSendType" SG_ 367 MXB_LED_151_Anf 3;
BA_ "GenSigSendType" SG_ 367 MXB_LED_152_Anf 3;
BA_ "GenSigSendType" SG_ 367 MXB_LED_153_Anf 3;
BA_ "GenSigSendType" SG_ 367 MXB_LED_154_Anf 3;
BA_ "GenSigSendType" SG_ 367 MXB_LED_155_Anf 3;
BA_ "GenSigSendType" SG_ 367 MXB_LED_156_Anf 3;
BA_ "GenSigSendType" SG_ 367 MXB_LED_157_Anf 3;
BA_ "GenSigSendType" SG_ 367 MXB_LED_158_Anf 3;
BA_ "GenSigSendType" SG_ 367 MXB_LED_159_Anf 3;
BA_ "GenSigSendType" SG_ 367 MXB_LED_160_Anf 3;
BA_ "GenSigSendType" SG_ 372 MXB_LED_161_Anf 3;
BA_ "GenSigSendType" SG_ 372 MXB_LED_162_Anf 3;
BA_ "GenSigSendType" SG_ 372 MXB_LED_163_Anf 3;
BA_ "GenSigSendType" SG_ 372 MXB_LED_164_Anf 3;
BA_ "GenSigSendType" SG_ 372 MXB_LED_165_Anf 3;
BA_ "GenSigSendType" SG_ 372 MXB_LED_166_Anf 3;
BA_ "GenSigSendType" SG_ 372 MXB_LED_167_Anf 3;
BA_ "GenSigSendType" SG_ 372 MXB_LED_168_Anf 3;
BA_ "GenSigSendType" SG_ 372 MXB_LED_169_Anf 3;
BA_ "GenSigSendType" SG_ 372 MXB_LED_170_Anf 3;
BA_ "GenSigSendType" SG_ 373 MXB_LED_171_Anf 3;
BA_ "GenSigSendType" SG_ 373 MXB_LED_172_Anf 3;
BA_ "GenSigSendType" SG_ 373 MXB_LED_173_Anf 3;
BA_ "GenSigSendType" SG_ 373 MXB_LED_174_Anf 3;
BA_ "GenSigSendType" SG_ 373 MXB_LED_175_Anf 3;
BA_ "GenSigSendType" SG_ 373 MXB_LED_176_Anf 3;
BA_ "GenSigSendType" SG_ 373 MXB_LED_177_Anf 3;
BA_ "GenSigSendType" SG_ 373 MXB_LED_178_Anf 3;
BA_ "GenSigSendType" SG_ 373 MXB_LED_179_Anf 3;
BA_ "GenSigSendType" SG_ 373 MXB_LED_180_Anf 3;
BA_ "GenSigSendType" SG_ 354 MXB_LED_21_Anf 3;
BA_ "GenSigSendType" SG_ 354 MXB_LED_22_Anf 3;
BA_ "GenSigSendType" SG_ 354 MXB_LED_23_Anf 3;
BA_ "GenSigSendType" SG_ 354 MXB_LED_24_Anf 3;
BA_ "GenSigSendType" SG_ 354 MXB_LED_25_Anf 3;
BA_ "GenSigSendType" SG_ 354 MXB_LED_26_Anf 3;
BA_ "GenSigSendType" SG_ 354 MXB_LED_27_Anf 3;
BA_ "GenSigSendType" SG_ 354 MXB_LED_28_Anf 3;
BA_ "GenSigSendType" SG_ 354 MXB_LED_29_Anf 3;
BA_ "GenSigSendType" SG_ 354 MXB_LED_30_Anf 3;
BA_ "GenSigSendType" SG_ 355 MXB_LED_31_Anf 3;
BA_ "GenSigSendType" SG_ 355 MXB_LED_32_Anf 3;
BA_ "GenSigSendType" SG_ 355 MXB_LED_33_Anf 3;
BA_ "GenSigSendType" SG_ 355 MXB_LED_34_Anf 3;
BA_ "GenSigSendType" SG_ 355 MXB_LED_35_Anf 3;
BA_ "GenSigSendType" SG_ 355 MXB_LED_36_Anf 3;
BA_ "GenSigSendType" SG_ 355 MXB_LED_37_Anf 3;
BA_ "GenSigSendType" SG_ 355 MXB_LED_38_Anf 3;
BA_ "GenSigSendType" SG_ 355 MXB_LED_39_Anf 3;
BA_ "GenSigSendType" SG_ 355 MXB_LED_40_Anf 3;
BA_ "GenSigSendType" SG_ 356 MXB_LED_41_Anf 3;
BA_ "GenSigSendType" SG_ 356 MXB_LED_42_Anf 3;
BA_ "GenSigSendType" SG_ 356 MXB_LED_43_Anf 3;
BA_ "GenSigSendType" SG_ 356 MXB_LED_44_Anf 3;
BA_ "GenSigSendType" SG_ 356 MXB_LED_45_Anf 3;
BA_ "GenSigSendType" SG_ 356 MXB_Sta_Diag 3;
BA_ "GenSigSendType" SG_ 356 MXB_LED_46_Anf 3;
BA_ "GenSigSendType" SG_ 356 MXB_LED_47_Anf 3;
BA_ "GenSigSendType" SG_ 356 MXB_LED_48_Anf 3;
BA_ "GenSigSendType" SG_ 356 MXB_LED_49_Anf 3;
BA_ "GenSigSendType" SG_ 356 MXB_LED_50_Anf 3;
BA_ "GenSigSendType" SG_ 357 MXB_LED_51_Anf 3;
BA_ "GenSigSendType" SG_ 357 MXB_LED_52_Anf 3;
BA_ "GenSigSendType" SG_ 357 MXB_LED_53_Anf 3;
BA_ "GenSigSendType" SG_ 357 MXB_LED_54_Anf 3;
BA_ "GenSigSendType" SG_ 357 MXB_LED_55_Anf 3;
BA_ "GenSigSendType" SG_ 357 MXB_LED_56_Anf 3;
BA_ "GenSigSendType" SG_ 357 MXB_LED_57_Anf 3;
BA_ "GenSigSendType" SG_ 357 MXB_LED_58_Anf 3;
BA_ "GenSigSendType" SG_ 357 MXB_LED_59_Anf 3;
BA_ "GenSigSendType" SG_ 357 MXB_LED_60_Anf 3;
BA_ "GenSigSendType" SG_ 358 MXB_LED_61_Anf 3;
BA_ "GenSigSendType" SG_ 358 MXB_LED_62_Anf 3;
BA_ "GenSigSendType" SG_ 358 MXB_LED_63_Anf 3;
BA_ "GenSigSendType" SG_ 358 MXB_LED_64_Anf 3;
BA_ "GenSigSendType" SG_ 358 MXB_LED_65_Anf 3;
BA_ "GenSigSendType" SG_ 358 MXB_LED_66_Anf 3;
BA_ "GenSigSendType" SG_ 358 MXB_LED_67_Anf 3;
BA_ "GenSigSendType" SG_ 358 MXB_LED_68_Anf 3;
BA_ "GenSigSendType" SG_ 358 MXB_LED_69_Anf 3;
BA_ "GenSigSendType" SG_ 358 MXB_LED_70_Anf 3;
BA_ "GenSigSendType" SG_ 359 MXB_LED_71_Anf 3;
BA_ "GenSigSendType" SG_ 359 MXB_LED_72_Anf 3;
BA_ "GenSigSendType" SG_ 359 MXB_LED_73_Anf 3;
BA_ "GenSigSendType" SG_ 359 MXB_LED_74_Anf 3;
BA_ "GenSigSendType" SG_ 359 MXB_LED_75_Anf 3;
BA_ "GenSigSendType" SG_ 359 MXB_LED_76_Anf 3;
BA_ "GenSigSendType" SG_ 359 MXB_LED_77_Anf 3;
BA_ "GenSigSendType" SG_ 359 MXB_LED_78_Anf 3;
BA_ "GenSigSendType" SG_ 359 MXB_LED_79_Anf 3;
BA_ "GenSigSendType" SG_ 359 MXB_LED_80_Anf 3;
BA_ "GenSigSendType" SG_ 360 MXB_LED_81_Anf 3;
BA_ "GenSigSendType" SG_ 360 MXB_LED_82_Anf 3;
BA_ "GenSigSendType" SG_ 360 MXB_LED_83_Anf 3;
BA_ "GenSigSendType" SG_ 360 MXB_LED_84_Anf 3;
BA_ "GenSigSendType" SG_ 360 MXB_LED_85_Anf 3;
BA_ "GenSigSendType" SG_ 360 MXB_LED_86_Anf 3;
BA_ "GenSigSendType" SG_ 360 MXB_LED_87_Anf 3;
BA_ "GenSigSendType" SG_ 360 MXB_LED_88_Anf 3;
BA_ "GenSigSendType" SG_ 360 MXB_LED_89_Anf 3;
BA_ "GenSigSendType" SG_ 360 MXB_LED_90_Anf 3;
BA_ "GenSigSendType" SG_ 361 MXB_LED_91_Anf 3;
BA_ "GenSigSendType" SG_ 361 MXB_LED_92_Anf 3;
BA_ "GenSigSendType" SG_ 361 MXB_LED_93_Anf 3;
BA_ "GenSigSendType" SG_ 361 MXB_LED_94_Anf 3;
BA_ "GenSigSendType" SG_ 361 MXB_LED_95_Anf 3;
BA_ "GenSigSendType" SG_ 361 MXB_LED_96_Anf 3;
BA_ "GenSigSendType" SG_ 361 MXB_LED_97_Anf 3;
BA_ "GenSigSendType" SG_ 361 MXB_LED_98_Anf 3;
BA_ "GenSigSendType" SG_ 361 MXB_LED_99_Anf 3;
BA_ "GenSigSendType" SG_ 361 MXB_LED_100_Anf 3;
BA_ "GenSigSendType" SG_ 2549875330 OBDC_LCM_L_Req_Data 3;
BA_ "GenSigSendType" SG_ 2550006402 OBDC_LCM_L_Resp_Data 3;
BA_ "GenSigSendType" SG_ 2549875331 OBDC_LCM_R_Req_Data 3;
BA_ "GenSigSendType" SG_ 2550006403 OBDC_LCM_R_Resp_Data 3;
BA_ "GenSigSendType" SG_ 2549875350 OBDC_LED_LM_L_Req_Data 3;
BA_ "GenSigSendType" SG_ 2550006422 OBDC_LED_LM_L_Resp_Data 3;
BA_ "GenSigSendType" SG_ 2549875351 OBDC_LED_LM_R_Req_Data 3;
BA_ "GenSigSendType" SG_ 2550006423 OBDC_LED_LM_R_Resp_Data 3;
BA_ "GenSigSendType" SG_ 2527679650 PAHS_L_AFS_Soll_Anf 3;
BA_ "GenSigSwitchedByIgnition" SG_ 2527679650 PAHS_L_AFS_Soll_Anf 0;
BA_ "GenSigSendType" SG_ 2527679650 PAHS_R_AFS_Soll_Anf 3;
BA_ "GenSigSwitchedByIgnition" SG_ 2527679650 PAHS_R_AFS_Soll_Anf 0;
BA_ "GenSigSendType" SG_ 2527679650 PAHS_L_LWR_Soll_Anf 3;
BA_ "GenSigSwitchedByIgnition" SG_ 2527679650 PAHS_L_LWR_Soll_Anf 0;
BA_ "GenSigSendType" SG_ 2527679650 PAHS_R_LWR_Soll_Anf 3;
BA_ "GenSigSwitchedByIgnition" SG_ 2527679650 PAHS_R_LWR_Soll_Anf 0;
BA_ "GenSigSendType" SG_ 2527679650 PAHS_L_GLW_Soll_Anf 3;
BA_ "GenSigSwitchedByIgnition" SG_ 2527679650 PAHS_L_GLW_Soll_Anf 0;
BA_ "GenSigSendType" SG_ 2527679650 PAHS_R_GLW_Soll_Anf 3;
BA_ "GenSigSwitchedByIgnition" SG_ 2527679650 PAHS_R_GLW_Soll_Anf 0;
BA_ "GenSigSendType" SG_ 1440 LS_Helligkeit_IR 0;
BA_ "GenSigStartValue" SG_ 1440 LS_Helligkeit_IR 254;
BA_ "Fehlerwert" SG_ 1440 LS_Helligkeit_IR 255;
BA_ "GenSigMissingSourceValue" SG_ 1440 LS_Helligkeit_IR 255;
BA_ "GenSigSendType" SG_ 1440 LS_Helligkeit_FW 0;
BA_ "GenSigStartValue" SG_ 1440 LS_Helligkeit_FW 1022;
BA_ "Fehlerwert" SG_ 1440 LS_Helligkeit_FW 1023;
BA_ "GenSigMissingSourceValue" SG_ 1440 LS_Helligkeit_FW 1023;
BA_ "GenSigSendType" SG_ 1440 LS_defekt 0;
BA_ "GenSigSendType" SG_ 1440 LS_Verbau 0;
BA_ "GenSigSendType" SG_ 1440 RS_Regenmenge 0;
BA_ "GenSigStartValue" SG_ 1440 RS_Regenmenge 14;
BA_ "Fehlerwert" SG_ 1440 RS_Regenmenge 15;
BA_ "GenSigMissingSourceValue" SG_ 1440 RS_Regenmenge 15;
BA_ "GenSigSendType" SG_ 1440 RS_Verbau 0;
BA_ "GenSigSendType" SG_ 1440 RS_Verglasung_schliessen 0;
BA_ "GenSigSendType" SG_ 1440 RS_defekt 0;
BA_ "GenSigSendType" SG_ 1440 RS_Wischergeschwindigkeit 0;
BA_ "GenSigSendType" SG_ 1440 RLS_Vorfeldhelligkeit_Boost 0;
BA_ "GenSigStartValue" SG_ 1440 RLS_Vorfeldhelligkeit_Boost 15;
BA_ "GenSigSendType" SG_ 1413 SI_Sammel_SG_Fehler 0;
BA_ "GenSigStartValue" SG_ 1413 SI_Sammel_SG_Fehler 63;
BA_ "GenSigSendType" SG_ 1413 SI_Diagnose_Aktiv 3;
BA_ "GenSigSendType" SG_ 1413 SI_QRS_Mode 3;
BA_ "GenSigSendType" SG_ 1413 SI_T_Mode 3;
BA_ "GenSigSendType" SG_ 1413 SI_NWDF 3;
BA_ "GenSigSendType" SG_ 1413 SI_NWDF_gueltig 3;
BA_ "GenSigFuncType" SG_ 1413 SI_NWDF_gueltig 8;
BA_ "GenSigSendType" SG_ 1413 SI_Sammelfehler 3;
BA_ "GenSigSendType" SG_ 1413 GW_KD_Fehler 3;
BA_ "GenSigSendType" SG_ 1413 SI_T_Schutz 3;
BA_ "GenSigSendType" SG_ 1413 SI_BUS_01 3;
BA_ "GenSigStartValue" SG_ 1413 SI_BUS_01 1;
BA_ "GenSigSendType" SG_ 1413 SI_BUS_02 3;
BA_ "GenSigStartValue" SG_ 1413 SI_BUS_02 1;
BA_ "GenSigSendType" SG_ 1413 SI_BUS_03 3;
BA_ "GenSigStartValue" SG_ 1413 SI_BUS_03 1;
BA_ "GenSigSendType" SG_ 1413 SI_BUS_04 3;
BA_ "GenSigStartValue" SG_ 1413 SI_BUS_04 1;
BA_ "GenSigSendType" SG_ 1413 SI_BUS_05 3;
BA_ "GenSigStartValue" SG_ 1413 SI_BUS_05 1;
BA_ "GenSigSendType" SG_ 1413 SI_BUS_06 3;
BA_ "GenSigStartValue" SG_ 1413 SI_BUS_06 1;
BA_ "GenSigSendType" SG_ 1413 SI_BUS_07 3;
BA_ "GenSigStartValue" SG_ 1413 SI_BUS_07 1;
BA_ "GenSigSendType" SG_ 1413 SI_BUS_08 3;
BA_ "GenSigStartValue" SG_ 1413 SI_BUS_08 1;
BA_ "GenSigSendType" SG_ 1413 SI_BUS_09 3;
BA_ "GenSigStartValue" SG_ 1413 SI_BUS_09 1;
BA_ "GenSigSendType" SG_ 1413 SI_BUS_10 3;
BA_ "GenSigStartValue" SG_ 1413 SI_BUS_10 1;
BA_ "GenSigSendType" SG_ 1413 SI_BUS_11 3;
BA_ "GenSigStartValue" SG_ 1413 SI_BUS_11 1;
BA_ "GenSigSendType" SG_ 1413 SI_BUS_12 3;
BA_ "GenSigStartValue" SG_ 1413 SI_BUS_12 1;
BA_ "GenSigSendType" SG_ 1413 SI_BUS_13 3;
BA_ "GenSigStartValue" SG_ 1413 SI_BUS_13 1;
BA_ "GenSigSendType" SG_ 1413 SI_BUS_14 3;
BA_ "GenSigStartValue" SG_ 1413 SI_BUS_14 1;
BA_ "GenSigSendType" SG_ 1413 SI_BUS_15 3;
BA_ "GenSigStartValue" SG_ 1413 SI_BUS_15 1;
BA_ "GenSigSendType" SG_ 1413 SI_Bus_Identifikation 0;
BA_ "GenSigFuncType" SG_ 1413 SI_Bus_Identifikation 8;
BA_ "GenSigSwitchedByIgnition" SG_ 2616989440 XCP_LCM_L_CRO_01_Data 0;
BA_ "GenSigSwitchedByIgnition" SG_ 2616991488 XCP_LCM_R_CRO_01_Data 0;
BA_ "GenSigSwitchedByIgnition" SG_ 2617030400 XCP_LED_DK3_L_CRO_01_Data 0;
BA_ "GenSigSwitchedByIgnition" SG_ 2617032448 XCP_LED_DK3_R_CRO_01_Data 0;
BA_REL_ "GenSigTimeoutTime" BU_SG_REL_ AFS SG_ 1357 MXB_R_Fernl_MXB_Def_1 2000;
BA_REL_ "GenSigTimeoutTime" BU_SG_REL_ FCM SG_ 1357 MXB_R_Fernl_MXB_Def_1 2000;
BA_REL_ "GenSigTimeoutTime" BU_SG_REL_ MXB SG_ 1357 MXB_R_Fernl_MXB_Def_1 2000;
BA_REL_ "GenSigTimeoutTime" BU_SG_REL_ AFS SG_ 1357 MXB_R_Fernl_MXB_Def_2 2000;
BA_REL_ "GenSigTimeoutTime" BU_SG_REL_ FCM SG_ 1357 MXB_R_Fernl_MXB_Def_2 2000;
BA_REL_ "GenSigTimeoutTime" BU_SG_REL_ MXB SG_ 1357 MXB_R_Fernl_MXB_Def_2 2000;
BA_REL_ "GenSigTimeoutTime" BU_SG_REL_ AFS SG_ 1357 MXB_R_Fernl_MXB_Def_3 2000;
BA_REL_ "GenSigTimeoutTime" BU_SG_REL_ FCM SG_ 1357 MXB_R_Fernl_MXB_Def_3 2000;
BA_REL_ "GenSigTimeoutTime" BU_SG_REL_ MXB SG_ 1357 MXB_R_Fernl_MXB_Def_3 2000;
BA_REL_ "GenSigTimeoutTime" BU_SG_REL_ AFS SG_ 1357 MXB_R_Fernl_MXB_Def_4 2000;
BA_REL_ "GenSigTimeoutTime" BU_SG_REL_ FCM SG_ 1357 MXB_R_Fernl_MXB_Def_4 2000;
BA_REL_ "GenSigTimeoutTime" BU_SG_REL_ MXB SG_ 1357 MXB_R_Fernl_MXB_Def_4 2000;
BA_REL_ "GenSigTimeoutTime" BU_SG_REL_ AFS SG_ 1357 MXB_R_Fernl_MXB_Def_5 2000;
BA_REL_ "GenSigTimeoutTime" BU_SG_REL_ FCM SG_ 1357 MXB_R_Fernl_MXB_Def_5 2000;
BA_REL_ "GenSigTimeoutTime" BU_SG_REL_ MXB SG_ 1357 MXB_R_Fernl_MXB_Def_5 2000;
BA_REL_ "GenSigTimeoutTime" BU_SG_REL_ AFS SG_ 1357 MXB_R_Fernl_MXB_Def_6 2000;
BA_REL_ "GenSigTimeoutTime" BU_SG_REL_ FCM SG_ 1357 MXB_R_Fernl_MXB_Def_6 2000;
BA_REL_ "GenSigTimeoutTime" BU_SG_REL_ MXB SG_ 1357 MXB_R_Fernl_MXB_Def_6 2000;
BA_REL_ "GenSigTimeoutTime" BU_SG_REL_ AFS SG_ 1357 MXB_R_Fernl_MXB_Def_7 2000;
BA_REL_ "GenSigTimeoutTime" BU_SG_REL_ FCM SG_ 1357 MXB_R_Fernl_MXB_Def_7 2000;
BA_REL_ "GenSigTimeoutTime" BU_SG_REL_ MXB SG_ 1357 MXB_R_Fernl_MXB_Def_7 2000;
BA_REL_ "GenSigTimeoutTime" BU_SG_REL_ AFS SG_ 1357 MXB_R_Fernl_MXB_Def_Err_Gultig 2000;
BA_REL_ "GenSigTimeoutTime" BU_SG_REL_ FCM SG_ 1357 MXB_R_Fernl_MXB_Def_Err_Gultig 2000;
BA_REL_ "GenSigTimeoutTime" BU_SG_REL_ MXB SG_ 1357 MXB_R_Fernl_MXB_Def_Err_Gultig 2000;
BA_REL_ "GenSigTimeoutTime" BU_SG_REL_ AFS SG_ 1357 MXB_R_Allg_Elektr_Def_1 2000;
BA_REL_ "GenSigTimeoutTime" BU_SG_REL_ FCM SG_ 1357 MXB_R_Allg_Elektr_Def_1 2000;
BA_REL_ "GenSigTimeoutTime" BU_SG_REL_ MXB SG_ 1357 MXB_R_Allg_Elektr_Def_1 2000;
BA_REL_ "GenSigTimeoutTime" BU_SG_REL_ AFS SG_ 1357 MXB_R_Allg_Elektr_Def_2 2000;
BA_REL_ "GenSigTimeoutTime" BU_SG_REL_ FCM SG_ 1357 MXB_R_Allg_Elektr_Def_2 2000;
BA_REL_ "GenSigTimeoutTime" BU_SG_REL_ MXB SG_ 1357 MXB_R_Allg_Elektr_Def_2 2000;
BA_REL_ "GenSigTimeoutTime" BU_SG_REL_ AFS SG_ 1357 MXB_R_Allg_Elektr_Def_3 2000;
BA_REL_ "GenSigTimeoutTime" BU_SG_REL_ FCM SG_ 1357 MXB_R_Allg_Elektr_Def_3 2000;
BA_REL_ "GenSigTimeoutTime" BU_SG_REL_ MXB SG_ 1357 MXB_R_Allg_Elektr_Def_3 2000;
BA_REL_ "GenSigTimeoutTime" BU_SG_REL_ AFS SG_ 1357 MXB_R_Allg_Elektr_Def_4 2000;
BA_REL_ "GenSigTimeoutTime" BU_SG_REL_ FCM SG_ 1357 MXB_R_Allg_Elektr_Def_4 2000;
BA_REL_ "GenSigTimeoutTime" BU_SG_REL_ MXB SG_ 1357 MXB_R_Allg_Elektr_Def_4 2000;
BA_REL_ "GenSigTimeoutTime" BU_SG_REL_ AFS SG_ 1357 MXB_R_Allg_Elektr_Def_5 2000;
BA_REL_ "GenSigTimeoutTime" BU_SG_REL_ FCM SG_ 1357 MXB_R_Allg_Elektr_Def_5 2000;
BA_REL_ "GenSigTimeoutTime" BU_SG_REL_ MXB SG_ 1357 MXB_R_Allg_Elektr_Def_5 2000;
BA_REL_ "GenSigTimeoutTime" BU_SG_REL_ AFS SG_ 1357 MXB_R_Allg_Elektr_Def_6 2000;
BA_REL_ "GenSigTimeoutTime" BU_SG_REL_ FCM SG_ 1357 MXB_R_Allg_Elektr_Def_6 2000;
BA_REL_ "GenSigTimeoutTime" BU_SG_REL_ MXB SG_ 1357 MXB_R_Allg_Elektr_Def_6 2000;
BA_REL_ "GenSigTimeoutTime" BU_SG_REL_ AFS SG_ 1357 MXB_R_Allg_Elektr_Def_7 2000;
BA_REL_ "GenSigTimeoutTime" BU_SG_REL_ FCM SG_ 1357 MXB_R_Allg_Elektr_Def_7 2000;
BA_REL_ "GenSigTimeoutTime" BU_SG_REL_ MXB SG_ 1357 MXB_R_Allg_Elektr_Def_7 2000;
BA_REL_ "GenSigTimeoutTime" BU_SG_REL_ AFS SG_ 1357 MXB_R_Allg_Elektr_Def_8 2000;
BA_REL_ "GenSigTimeoutTime" BU_SG_REL_ FCM SG_ 1357 MXB_R_Allg_Elektr_Def_8 2000;
BA_REL_ "GenSigTimeoutTime" BU_SG_REL_ MXB SG_ 1357 MXB_R_Allg_Elektr_Def_8 2000;
BA_REL_ "GenSigTimeoutTime" BU_SG_REL_ AFS SG_ 1357 MXB_R_Allg_Elektr_Def_Err_Gultig 2000;
BA_REL_ "GenSigTimeoutTime" BU_SG_REL_ FCM SG_ 1357 MXB_R_Allg_Elektr_Def_Err_Gultig 2000;
BA_REL_ "GenSigTimeoutTime" BU_SG_REL_ MXB SG_ 1357 MXB_R_Allg_Elektr_Def_Err_Gultig 2000;
BA_REL_ "GenSigTimeoutTime" BU_SG_REL_ AFS SG_ 1357 MXB_R_Luefter_1_Def_1 2000;
BA_REL_ "GenSigTimeoutTime" BU_SG_REL_ FCM SG_ 1357 MXB_R_Luefter_1_Def_1 2000;
BA_REL_ "GenSigTimeoutTime" BU_SG_REL_ MXB SG_ 1357 MXB_R_Luefter_1_Def_1 2000;
BA_REL_ "GenSigTimeoutTime" BU_SG_REL_ AFS SG_ 1357 MXB_R_Luefter_1_Def_2 2000;
BA_REL_ "GenSigTimeoutTime" BU_SG_REL_ FCM SG_ 1357 MXB_R_Luefter_1_Def_2 2000;
BA_REL_ "GenSigTimeoutTime" BU_SG_REL_ MXB SG_ 1357 MXB_R_Luefter_1_Def_2 2000;
BA_REL_ "GenSigTimeoutTime" BU_SG_REL_ AFS SG_ 1357 MXB_R_Luefter_1_Def_3 2000;
BA_REL_ "GenSigTimeoutTime" BU_SG_REL_ FCM SG_ 1357 MXB_R_Luefter_1_Def_3 2000;
BA_REL_ "GenSigTimeoutTime" BU_SG_REL_ MXB SG_ 1357 MXB_R_Luefter_1_Def_3 2000;
BA_REL_ "GenSigTimeoutTime" BU_SG_REL_ AFS SG_ 1357 MXB_R_Luefter_1_Def_4 2000;
BA_REL_ "GenSigTimeoutTime" BU_SG_REL_ FCM SG_ 1357 MXB_R_Luefter_1_Def_4 2000;
BA_REL_ "GenSigTimeoutTime" BU_SG_REL_ MXB SG_ 1357 MXB_R_Luefter_1_Def_4 2000;
BA_REL_ "GenSigTimeoutTime" BU_SG_REL_ AFS SG_ 1357 MXB_R_Luefter_2_Def_1 2000;
BA_REL_ "GenSigTimeoutTime" BU_SG_REL_ FCM SG_ 1357 MXB_R_Luefter_2_Def_1 2000;
BA_REL_ "GenSigTimeoutTime" BU_SG_REL_ MXB SG_ 1357 MXB_R_Luefter_2_Def_1 2000;
BA_REL_ "GenSigTimeoutTime" BU_SG_REL_ AFS SG_ 1357 MXB_R_Luefter_2_Def_2 2000;
BA_REL_ "GenSigTimeoutTime" BU_SG_REL_ FCM SG_ 1357 MXB_R_Luefter_2_Def_2 2000;
BA_REL_ "GenSigTimeoutTime" BU_SG_REL_ MXB SG_ 1357 MXB_R_Luefter_2_Def_2 2000;
BA_REL_ "GenSigTimeoutTime" BU_SG_REL_ AFS SG_ 1357 MXB_R_Luefter_2_Def_3 2000;
BA_REL_ "GenSigTimeoutTime" BU_SG_REL_ FCM SG_ 1357 MXB_R_Luefter_2_Def_3 2000;
BA_REL_ "GenSigTimeoutTime" BU_SG_REL_ MXB SG_ 1357 MXB_R_Luefter_2_Def_3 2000;
BA_REL_ "GenSigTimeoutTime" BU_SG_REL_ AFS SG_ 1357 MXB_R_Luefter_2_Def_4 2000;
BA_REL_ "GenSigTimeoutTime" BU_SG_REL_ FCM SG_ 1357 MXB_R_Luefter_2_Def_4 2000;
BA_REL_ "GenSigTimeoutTime" BU_SG_REL_ MXB SG_ 1357 MXB_R_Luefter_2_Def_4 2000;
BA_REL_ "GenSigTimeoutTime" BU_SG_REL_ AFS SG_ 1357 MXB_R_Luefter_1_Def_Err_Gultig 2000;
BA_REL_ "GenSigTimeoutTime" BU_SG_REL_ FCM SG_ 1357 MXB_R_Luefter_1_Def_Err_Gultig 2000;
BA_REL_ "GenSigTimeoutTime" BU_SG_REL_ MXB SG_ 1357 MXB_R_Luefter_1_Def_Err_Gultig 2000;
BA_REL_ "GenSigTimeoutTime" BU_SG_REL_ AFS SG_ 1357 MXB_R_Luefter_2_Def_Err_Gultig 2000;
BA_REL_ "GenSigTimeoutTime" BU_SG_REL_ FCM SG_ 1357 MXB_R_Luefter_2_Def_Err_Gultig 2000;
BA_REL_ "GenSigTimeoutTime" BU_SG_REL_ MXB SG_ 1357 MXB_R_Luefter_2_Def_Err_Gultig 2000;
BA_REL_ "GenSigTimeoutTime" BU_SG_REL_ AFS SG_ 1357 MXB_R_Allg_Elektr_Def 2000;
BA_REL_ "GenSigTimeoutTime" BU_SG_REL_ BCM1 SG_ 1357 MXB_R_Allg_Elektr_Def 2000;
BA_REL_ "GenSigTimeoutTime" BU_SG_REL_ FCM SG_ 1357 MXB_R_Allg_Elektr_Def 2000;
BA_REL_ "GenSigTimeoutTime" BU_SG_REL_ MXB SG_ 1357 MXB_R_Allg_Elektr_Def 2000;
BA_REL_ "GenSigTimeoutTime" BU_SG_REL_ AFS SG_ 1357 MXB_R_Fernl_MXB_Def 2000;
BA_REL_ "GenSigTimeoutTime" BU_SG_REL_ BCM1 SG_ 1357 MXB_R_Fernl_MXB_Def 2000;
BA_REL_ "GenSigTimeoutTime" BU_SG_REL_ FCM SG_ 1357 MXB_R_Fernl_MXB_Def 2000;
BA_REL_ "GenSigTimeoutTime" BU_SG_REL_ MXB SG_ 1357 MXB_R_Fernl_MXB_Def 2000;
BA_REL_ "GenSigTimeoutTime" BU_SG_REL_ AFS SG_ 1438 MXB_L_Mux 1000;
BA_REL_ "GenSigTimeoutTime" BU_SG_REL_ FCM SG_ 1438 MXB_L_Mux 1000;
BA_REL_ "GenSigTimeoutTime" BU_SG_REL_ MXB SG_ 1438 MXB_L_Mux 1000;
BA_REL_ "GenSigTimeoutTime" BU_SG_REL_ AFS SG_ 1438 MXB_L_SW_Idt_Z01 1000;
BA_REL_ "GenSigTimeoutTime" BU_SG_REL_ FCM SG_ 1438 MXB_L_SW_Idt_Z01 1000;
BA_REL_ "GenSigTimeoutTime" BU_SG_REL_ MXB SG_ 1438 MXB_L_SW_Idt_Z01 1000;
BA_REL_ "GenSigTimeoutTime" BU_SG_REL_ AFS SG_ 1438 MXB_L_SW_Idt_Z08 1000;
BA_REL_ "GenSigTimeoutTime" BU_SG_REL_ FCM SG_ 1438 MXB_L_SW_Idt_Z08 1000;
BA_REL_ "GenSigTimeoutTime" BU_SG_REL_ MXB SG_ 1438 MXB_L_SW_Idt_Z08 1000;
BA_REL_ "GenSigTimeoutTime" BU_SG_REL_ AFS SG_ 1438 MXB_L_SW_Idx_Z04 1000;
BA_REL_ "GenSigTimeoutTime" BU_SG_REL_ FCM SG_ 1438 MXB_L_SW_Idx_Z04 1000;
BA_REL_ "GenSigTimeoutTime" BU_SG_REL_ MXB SG_ 1438 MXB_L_SW_Idx_Z04 1000;
BA_REL_ "GenSigTimeoutTime" BU_SG_REL_ AFS SG_ 1438 MXB_L_HW_Idt_Z07 1000;
BA_REL_ "GenSigTimeoutTime" BU_SG_REL_ FCM SG_ 1438 MXB_L_HW_Idt_Z07 1000;
BA_REL_ "GenSigTimeoutTime" BU_SG_REL_ MXB SG_ 1438 MXB_L_HW_Idt_Z07 1000;
BA_REL_ "GenSigTimeoutTime" BU_SG_REL_ AFS SG_ 1438 MXB_L_HW_Idx_Z03 1000;
BA_REL_ "GenSigTimeoutTime" BU_SG_REL_ FCM SG_ 1438 MXB_L_HW_Idx_Z03 1000;
BA_REL_ "GenSigTimeoutTime" BU_SG_REL_ MXB SG_ 1438 MXB_L_HW_Idx_Z03 1000;
BA_REL_ "GenSigTimeoutTime" BU_SG_REL_ AFS SG_ 1438 MXB_L_SW_Idt_Z02 1000;
BA_REL_ "GenSigTimeoutTime" BU_SG_REL_ FCM SG_ 1438 MXB_L_SW_Idt_Z02 1000;
BA_REL_ "GenSigTimeoutTime" BU_SG_REL_ MXB SG_ 1438 MXB_L_SW_Idt_Z02 1000;
BA_REL_ "GenSigTimeoutTime" BU_SG_REL_ AFS SG_ 1438 MXB_L_SW_Idt_Z09 1000;
BA_REL_ "GenSigTimeoutTime" BU_SG_REL_ FCM SG_ 1438 MXB_L_SW_Idt_Z09 1000;
BA_REL_ "GenSigTimeoutTime" BU_SG_REL_ MXB SG_ 1438 MXB_L_SW_Idt_Z09 1000;
BA_REL_ "GenSigTimeoutTime" BU_SG_REL_ AFS SG_ 1438 MXB_L_HW_Idt_Z01 1000;
BA_REL_ "GenSigTimeoutTime" BU_SG_REL_ FCM SG_ 1438 MXB_L_HW_Idt_Z01 1000;
BA_REL_ "GenSigTimeoutTime" BU_SG_REL_ MXB SG_ 1438 MXB_L_HW_Idt_Z01 1000;
BA_REL_ "GenSigTimeoutTime" BU_SG_REL_ AFS SG_ 1438 MXB_L_HW_Idt_Z08 1000;
BA_REL_ "GenSigTimeoutTime" BU_SG_REL_ FCM SG_ 1438 MXB_L_HW_Idt_Z08 1000;
BA_REL_ "GenSigTimeoutTime" BU_SG_REL_ MXB SG_ 1438 MXB_L_HW_Idt_Z08 1000;
BA_REL_ "GenSigTimeoutTime" BU_SG_REL_ AFS SG_ 1438 MXB_L_SW_Idt_Z03 1000;
BA_REL_ "GenSigTimeoutTime" BU_SG_REL_ FCM SG_ 1438 MXB_L_SW_Idt_Z03 1000;
BA_REL_ "GenSigTimeoutTime" BU_SG_REL_ MXB SG_ 1438 MXB_L_SW_Idt_Z03 1000;
BA_REL_ "GenSigTimeoutTime" BU_SG_REL_ AFS SG_ 1438 MXB_L_SW_Idt_Z10 1000;
BA_REL_ "GenSigTimeoutTime" BU_SG_REL_ FCM SG_ 1438 MXB_L_SW_Idt_Z10 1000;
BA_REL_ "GenSigTimeoutTime" BU_SG_REL_ MXB SG_ 1438 MXB_L_SW_Idt_Z10 1000;
BA_REL_ "GenSigTimeoutTime" BU_SG_REL_ AFS SG_ 1438 MXB_L_HW_Idt_Z02 1000;
BA_REL_ "GenSigTimeoutTime" BU_SG_REL_ FCM SG_ 1438 MXB_L_HW_Idt_Z02 1000;
BA_REL_ "GenSigTimeoutTime" BU_SG_REL_ MXB SG_ 1438 MXB_L_HW_Idt_Z02 1000;
BA_REL_ "GenSigTimeoutTime" BU_SG_REL_ AFS SG_ 1438 MXB_L_HW_Idt_Z09 1000;
BA_REL_ "GenSigTimeoutTime" BU_SG_REL_ FCM SG_ 1438 MXB_L_HW_Idt_Z09 1000;
BA_REL_ "GenSigTimeoutTime" BU_SG_REL_ MXB SG_ 1438 MXB_L_HW_Idt_Z09 1000;
BA_REL_ "GenSigTimeoutTime" BU_SG_REL_ AFS SG_ 1438 MXB_L_SW_Idt_Z04 1000;
BA_REL_ "GenSigTimeoutTime" BU_SG_REL_ FCM SG_ 1438 MXB_L_SW_Idt_Z04 1000;
BA_REL_ "GenSigTimeoutTime" BU_SG_REL_ MXB SG_ 1438 MXB_L_SW_Idt_Z04 1000;
BA_REL_ "GenSigTimeoutTime" BU_SG_REL_ AFS SG_ 1438 MXB_L_SW_Idt_Z11 1000;
BA_REL_ "GenSigTimeoutTime" BU_SG_REL_ FCM SG_ 1438 MXB_L_SW_Idt_Z11 1000;
BA_REL_ "GenSigTimeoutTime" BU_SG_REL_ MXB SG_ 1438 MXB_L_SW_Idt_Z11 1000;
BA_REL_ "GenSigTimeoutTime" BU_SG_REL_ AFS SG_ 1438 MXB_L_HW_Idt_Z03 1000;
BA_REL_ "GenSigTimeoutTime" BU_SG_REL_ FCM SG_ 1438 MXB_L_HW_Idt_Z03 1000;
BA_REL_ "GenSigTimeoutTime" BU_SG_REL_ MXB SG_ 1438 MXB_L_HW_Idt_Z03 1000;
BA_REL_ "GenSigTimeoutTime" BU_SG_REL_ AFS SG_ 1438 MXB_L_HW_Idt_Z10 1000;
BA_REL_ "GenSigTimeoutTime" BU_SG_REL_ FCM SG_ 1438 MXB_L_HW_Idt_Z10 1000;
BA_REL_ "GenSigTimeoutTime" BU_SG_REL_ MXB SG_ 1438 MXB_L_HW_Idt_Z10 1000;
BA_REL_ "GenSigTimeoutTime" BU_SG_REL_ AFS SG_ 1438 MXB_L_SW_Idt_Z05 1000;
BA_REL_ "GenSigTimeoutTime" BU_SG_REL_ FCM SG_ 1438 MXB_L_SW_Idt_Z05 1000;
BA_REL_ "GenSigTimeoutTime" BU_SG_REL_ MXB SG_ 1438 MXB_L_SW_Idt_Z05 1000;
BA_REL_ "GenSigTimeoutTime" BU_SG_REL_ AFS SG_ 1438 MXB_L_SW_Idx_Z01 1000;
BA_REL_ "GenSigTimeoutTime" BU_SG_REL_ FCM SG_ 1438 MXB_L_SW_Idx_Z01 1000;
BA_REL_ "GenSigTimeoutTime" BU_SG_REL_ MXB SG_ 1438 MXB_L_SW_Idx_Z01 1000;
BA_REL_ "GenSigTimeoutTime" BU_SG_REL_ AFS SG_ 1438 MXB_L_HW_Idt_Z04 1000;
BA_REL_ "GenSigTimeoutTime" BU_SG_REL_ FCM SG_ 1438 MXB_L_HW_Idt_Z04 1000;
BA_REL_ "GenSigTimeoutTime" BU_SG_REL_ MXB SG_ 1438 MXB_L_HW_Idt_Z04 1000;
BA_REL_ "GenSigTimeoutTime" BU_SG_REL_ AFS SG_ 1438 MXB_L_HW_Idt_Z11 1000;
BA_REL_ "GenSigTimeoutTime" BU_SG_REL_ FCM SG_ 1438 MXB_L_HW_Idt_Z11 1000;
BA_REL_ "GenSigTimeoutTime" BU_SG_REL_ MXB SG_ 1438 MXB_L_HW_Idt_Z11 1000;
BA_REL_ "GenSigTimeoutTime" BU_SG_REL_ AFS SG_ 1438 MXB_L_SW_Idt_Z06 1000;
BA_REL_ "GenSigTimeoutTime" BU_SG_REL_ FCM SG_ 1438 MXB_L_SW_Idt_Z06 1000;
BA_REL_ "GenSigTimeoutTime" BU_SG_REL_ MXB SG_ 1438 MXB_L_SW_Idt_Z06 1000;
BA_REL_ "GenSigTimeoutTime" BU_SG_REL_ AFS SG_ 1438 MXB_L_SW_Idx_Z02 1000;
BA_REL_ "GenSigTimeoutTime" BU_SG_REL_ FCM SG_ 1438 MXB_L_SW_Idx_Z02 1000;
BA_REL_ "GenSigTimeoutTime" BU_SG_REL_ MXB SG_ 1438 MXB_L_SW_Idx_Z02 1000;
BA_REL_ "GenSigTimeoutTime" BU_SG_REL_ AFS SG_ 1438 MXB_L_HW_Idt_Z05 1000;
BA_REL_ "GenSigTimeoutTime" BU_SG_REL_ FCM SG_ 1438 MXB_L_HW_Idt_Z05 1000;
BA_REL_ "GenSigTimeoutTime" BU_SG_REL_ MXB SG_ 1438 MXB_L_HW_Idt_Z05 1000;
BA_REL_ "GenSigTimeoutTime" BU_SG_REL_ AFS SG_ 1438 MXB_L_HW_Idx_Z01 1000;
BA_REL_ "GenSigTimeoutTime" BU_SG_REL_ FCM SG_ 1438 MXB_L_HW_Idx_Z01 1000;
BA_REL_ "GenSigTimeoutTime" BU_SG_REL_ MXB SG_ 1438 MXB_L_HW_Idx_Z01 1000;
BA_REL_ "GenSigTimeoutTime" BU_SG_REL_ AFS SG_ 1438 MXB_L_SW_Idt_Z07 1000;
BA_REL_ "GenSigTimeoutTime" BU_SG_REL_ FCM SG_ 1438 MXB_L_SW_Idt_Z07 1000;
BA_REL_ "GenSigTimeoutTime" BU_SG_REL_ MXB SG_ 1438 MXB_L_SW_Idt_Z07 1000;
BA_REL_ "GenSigTimeoutTime" BU_SG_REL_ AFS SG_ 1438 MXB_L_SW_Idx_Z03 1000;
BA_REL_ "GenSigTimeoutTime" BU_SG_REL_ FCM SG_ 1438 MXB_L_SW_Idx_Z03 1000;
BA_REL_ "GenSigTimeoutTime" BU_SG_REL_ MXB SG_ 1438 MXB_L_SW_Idx_Z03 1000;
BA_REL_ "GenSigTimeoutTime" BU_SG_REL_ AFS SG_ 1438 MXB_L_HW_Idt_Z06 1000;
BA_REL_ "GenSigTimeoutTime" BU_SG_REL_ FCM SG_ 1438 MXB_L_HW_Idt_Z06 1000;
BA_REL_ "GenSigTimeoutTime" BU_SG_REL_ MXB SG_ 1438 MXB_L_HW_Idt_Z06 1000;
BA_REL_ "GenSigTimeoutTime" BU_SG_REL_ AFS SG_ 1438 MXB_L_HW_Idx_Z02 1000;
BA_REL_ "GenSigTimeoutTime" BU_SG_REL_ FCM SG_ 1438 MXB_L_HW_Idx_Z02 1000;
BA_REL_ "GenSigTimeoutTime" BU_SG_REL_ MXB SG_ 1438 MXB_L_HW_Idx_Z02 1000;
BA_REL_ "GenSigTimeoutTime" BU_SG_REL_ AFS SG_ 1437 MXB_R_Mux 1000;
BA_REL_ "GenSigTimeoutTime" BU_SG_REL_ FCM SG_ 1437 MXB_R_Mux 1000;
BA_REL_ "GenSigTimeoutTime" BU_SG_REL_ MXB SG_ 1437 MXB_R_Mux 1000;
BA_REL_ "GenSigTimeoutTime" BU_SG_REL_ AFS SG_ 1437 MXB_R_SW_Idt_Z01 1000;
BA_REL_ "GenSigTimeoutTime" BU_SG_REL_ FCM SG_ 1437 MXB_R_SW_Idt_Z01 1000;
BA_REL_ "GenSigTimeoutTime" BU_SG_REL_ MXB SG_ 1437 MXB_R_SW_Idt_Z01 1000;
BA_REL_ "GenSigTimeoutTime" BU_SG_REL_ AFS SG_ 1437 MXB_R_SW_Idt_Z08 1000;
BA_REL_ "GenSigTimeoutTime" BU_SG_REL_ FCM SG_ 1437 MXB_R_SW_Idt_Z08 1000;
BA_REL_ "GenSigTimeoutTime" BU_SG_REL_ MXB SG_ 1437 MXB_R_SW_Idt_Z08 1000;
BA_REL_ "GenSigTimeoutTime" BU_SG_REL_ AFS SG_ 1437 MXB_R_SW_Idx_Z04 1000;
BA_REL_ "GenSigTimeoutTime" BU_SG_REL_ FCM SG_ 1437 MXB_R_SW_Idx_Z04 1000;
BA_REL_ "GenSigTimeoutTime" BU_SG_REL_ MXB SG_ 1437 MXB_R_SW_Idx_Z04 1000;
BA_REL_ "GenSigTimeoutTime" BU_SG_REL_ AFS SG_ 1437 MXB_R_HW_Idt_Z07 1000;
BA_REL_ "GenSigTimeoutTime" BU_SG_REL_ FCM SG_ 1437 MXB_R_HW_Idt_Z07 1000;
BA_REL_ "GenSigTimeoutTime" BU_SG_REL_ MXB SG_ 1437 MXB_R_HW_Idt_Z07 1000;
BA_REL_ "GenSigTimeoutTime" BU_SG_REL_ AFS SG_ 1437 MXB_R_HW_Idx_Z03 1000;
BA_REL_ "GenSigTimeoutTime" BU_SG_REL_ FCM SG_ 1437 MXB_R_HW_Idx_Z03 1000;
BA_REL_ "GenSigTimeoutTime" BU_SG_REL_ MXB SG_ 1437 MXB_R_HW_Idx_Z03 1000;
BA_REL_ "GenSigTimeoutTime" BU_SG_REL_ AFS SG_ 1437 MXB_R_SW_Idt_Z02 1000;
BA_REL_ "GenSigTimeoutTime" BU_SG_REL_ FCM SG_ 1437 MXB_R_SW_Idt_Z02 1000;
BA_REL_ "GenSigTimeoutTime" BU_SG_REL_ MXB SG_ 1437 MXB_R_SW_Idt_Z02 1000;
BA_REL_ "GenSigTimeoutTime" BU_SG_REL_ AFS SG_ 1437 MXB_R_SW_Idt_Z09 1000;
BA_REL_ "GenSigTimeoutTime" BU_SG_REL_ FCM SG_ 1437 MXB_R_SW_Idt_Z09 1000;
BA_REL_ "GenSigTimeoutTime" BU_SG_REL_ MXB SG_ 1437 MXB_R_SW_Idt_Z09 1000;
BA_REL_ "GenSigTimeoutTime" BU_SG_REL_ AFS SG_ 1437 MXB_R_HW_Idt_Z01 1000;
BA_REL_ "GenSigTimeoutTime" BU_SG_REL_ FCM SG_ 1437 MXB_R_HW_Idt_Z01 1000;
BA_REL_ "GenSigTimeoutTime" BU_SG_REL_ MXB SG_ 1437 MXB_R_HW_Idt_Z01 1000;
BA_REL_ "GenSigTimeoutTime" BU_SG_REL_ AFS SG_ 1437 MXB_R_HW_Idt_Z08 1000;
BA_REL_ "GenSigTimeoutTime" BU_SG_REL_ FCM SG_ 1437 MXB_R_HW_Idt_Z08 1000;
BA_REL_ "GenSigTimeoutTime" BU_SG_REL_ MXB SG_ 1437 MXB_R_HW_Idt_Z08 1000;
BA_REL_ "GenSigTimeoutTime" BU_SG_REL_ AFS SG_ 1437 MXB_R_SW_Idt_Z03 1000;
BA_REL_ "GenSigTimeoutTime" BU_SG_REL_ FCM SG_ 1437 MXB_R_SW_Idt_Z03 1000;
BA_REL_ "GenSigTimeoutTime" BU_SG_REL_ MXB SG_ 1437 MXB_R_SW_Idt_Z03 1000;
BA_REL_ "GenSigTimeoutTime" BU_SG_REL_ AFS SG_ 1437 MXB_R_SW_Idt_Z10 1000;
BA_REL_ "GenSigTimeoutTime" BU_SG_REL_ FCM SG_ 1437 MXB_R_SW_Idt_Z10 1000;
BA_REL_ "GenSigTimeoutTime" BU_SG_REL_ MXB SG_ 1437 MXB_R_SW_Idt_Z10 1000;
BA_REL_ "GenSigTimeoutTime" BU_SG_REL_ AFS SG_ 1437 MXB_R_HW_Idt_Z02 1000;
BA_REL_ "GenSigTimeoutTime" BU_SG_REL_ FCM SG_ 1437 MXB_R_HW_Idt_Z02 1000;
BA_REL_ "GenSigTimeoutTime" BU_SG_REL_ MXB SG_ 1437 MXB_R_HW_Idt_Z02 1000;
BA_REL_ "GenSigTimeoutTime" BU_SG_REL_ AFS SG_ 1437 MXB_R_HW_Idt_Z09 1000;
BA_REL_ "GenSigTimeoutTime" BU_SG_REL_ FCM SG_ 1437 MXB_R_HW_Idt_Z09 1000;
BA_REL_ "GenSigTimeoutTime" BU_SG_REL_ MXB SG_ 1437 MXB_R_HW_Idt_Z09 1000;
BA_REL_ "GenSigTimeoutTime" BU_SG_REL_ AFS SG_ 1437 MXB_R_SW_Idt_Z04 1000;
BA_REL_ "GenSigTimeoutTime" BU_SG_REL_ FCM SG_ 1437 MXB_R_SW_Idt_Z04 1000;
BA_REL_ "GenSigTimeoutTime" BU_SG_REL_ MXB SG_ 1437 MXB_R_SW_Idt_Z04 1000;
BA_REL_ "GenSigTimeoutTime" BU_SG_REL_ AFS SG_ 1437 MXB_R_SW_Idt_Z11 1000;
BA_REL_ "GenSigTimeoutTime" BU_SG_REL_ FCM SG_ 1437 MXB_R_SW_Idt_Z11 1000;
BA_REL_ "GenSigTimeoutTime" BU_SG_REL_ MXB SG_ 1437 MXB_R_SW_Idt_Z11 1000;
BA_REL_ "GenSigTimeoutTime" BU_SG_REL_ AFS SG_ 1437 MXB_R_HW_Idt_Z03 1000;
BA_REL_ "GenSigTimeoutTime" BU_SG_REL_ FCM SG_ 1437 MXB_R_HW_Idt_Z03 1000;
BA_REL_ "GenSigTimeoutTime" BU_SG_REL_ MXB SG_ 1437 MXB_R_HW_Idt_Z03 1000;
BA_REL_ "GenSigTimeoutTime" BU_SG_REL_ AFS SG_ 1437 MXB_R_HW_Idt_Z10 1000;
BA_REL_ "GenSigTimeoutTime" BU_SG_REL_ FCM SG_ 1437 MXB_R_HW_Idt_Z10 1000;
BA_REL_ "GenSigTimeoutTime" BU_SG_REL_ MXB SG_ 1437 MXB_R_HW_Idt_Z10 1000;
BA_REL_ "GenSigTimeoutTime" BU_SG_REL_ AFS SG_ 1437 MXB_R_SW_Idt_Z05 1000;
BA_REL_ "GenSigTimeoutTime" BU_SG_REL_ FCM SG_ 1437 MXB_R_SW_Idt_Z05 1000;
BA_REL_ "GenSigTimeoutTime" BU_SG_REL_ MXB SG_ 1437 MXB_R_SW_Idt_Z05 1000;
BA_REL_ "GenSigTimeoutTime" BU_SG_REL_ AFS SG_ 1437 MXB_R_SW_Idx_Z01 1000;
BA_REL_ "GenSigTimeoutTime" BU_SG_REL_ FCM SG_ 1437 MXB_R_SW_Idx_Z01 1000;
BA_REL_ "GenSigTimeoutTime" BU_SG_REL_ MXB SG_ 1437 MXB_R_SW_Idx_Z01 1000;
BA_REL_ "GenSigTimeoutTime" BU_SG_REL_ AFS SG_ 1437 MXB_R_HW_Idt_Z04 1000;
BA_REL_ "GenSigTimeoutTime" BU_SG_REL_ FCM SG_ 1437 MXB_R_HW_Idt_Z04 1000;
BA_REL_ "GenSigTimeoutTime" BU_SG_REL_ MXB SG_ 1437 MXB_R_HW_Idt_Z04 1000;
BA_REL_ "GenSigTimeoutTime" BU_SG_REL_ AFS SG_ 1437 MXB_R_HW_Idt_Z11 1000;
BA_REL_ "GenSigTimeoutTime" BU_SG_REL_ FCM SG_ 1437 MXB_R_HW_Idt_Z11 1000;
BA_REL_ "GenSigTimeoutTime" BU_SG_REL_ MXB SG_ 1437 MXB_R_HW_Idt_Z11 1000;
BA_REL_ "GenSigTimeoutTime" BU_SG_REL_ AFS SG_ 1437 MXB_R_SW_Idt_Z06 1000;
BA_REL_ "GenSigTimeoutTime" BU_SG_REL_ FCM SG_ 1437 MXB_R_SW_Idt_Z06 1000;
BA_REL_ "GenSigTimeoutTime" BU_SG_REL_ MXB SG_ 1437 MXB_R_SW_Idt_Z06 1000;
BA_REL_ "GenSigTimeoutTime" BU_SG_REL_ AFS SG_ 1437 MXB_R_SW_Idx_Z02 1000;
BA_REL_ "GenSigTimeoutTime" BU_SG_REL_ FCM SG_ 1437 MXB_R_SW_Idx_Z02 1000;
BA_REL_ "GenSigTimeoutTime" BU_SG_REL_ MXB SG_ 1437 MXB_R_SW_Idx_Z02 1000;
BA_REL_ "GenSigTimeoutTime" BU_SG_REL_ AFS SG_ 1437 MXB_R_HW_Idt_Z05 1000;
BA_REL_ "GenSigTimeoutTime" BU_SG_REL_ FCM SG_ 1437 MXB_R_HW_Idt_Z05 1000;
BA_REL_ "GenSigTimeoutTime" BU_SG_REL_ MXB SG_ 1437 MXB_R_HW_Idt_Z05 1000;
BA_REL_ "GenSigTimeoutTime" BU_SG_REL_ AFS SG_ 1437 MXB_R_HW_Idx_Z01 1000;
BA_REL_ "GenSigTimeoutTime" BU_SG_REL_ FCM SG_ 1437 MXB_R_HW_Idx_Z01 1000;
BA_REL_ "GenSigTimeoutTime" BU_SG_REL_ MXB SG_ 1437 MXB_R_HW_Idx_Z01 1000;
BA_REL_ "GenSigTimeoutTime" BU_SG_REL_ AFS SG_ 1437 MXB_R_SW_Idt_Z07 1000;
BA_REL_ "GenSigTimeoutTime" BU_SG_REL_ FCM SG_ 1437 MXB_R_SW_Idt_Z07 1000;
BA_REL_ "GenSigTimeoutTime" BU_SG_REL_ MXB SG_ 1437 MXB_R_SW_Idt_Z07 1000;
BA_REL_ "GenSigTimeoutTime" BU_SG_REL_ AFS SG_ 1437 MXB_R_SW_Idx_Z03 1000;
BA_REL_ "GenSigTimeoutTime" BU_SG_REL_ FCM SG_ 1437 MXB_R_SW_Idx_Z03 1000;
BA_REL_ "GenSigTimeoutTime" BU_SG_REL_ MXB SG_ 1437 MXB_R_SW_Idx_Z03 1000;
BA_REL_ "GenSigTimeoutTime" BU_SG_REL_ AFS SG_ 1437 MXB_R_HW_Idt_Z06 1000;
BA_REL_ "GenSigTimeoutTime" BU_SG_REL_ FCM SG_ 1437 MXB_R_HW_Idt_Z06 1000;
BA_REL_ "GenSigTimeoutTime" BU_SG_REL_ MXB SG_ 1437 MXB_R_HW_Idt_Z06 1000;
BA_REL_ "GenSigTimeoutTime" BU_SG_REL_ AFS SG_ 1437 MXB_R_HW_Idx_Z02 1000;
BA_REL_ "GenSigTimeoutTime" BU_SG_REL_ FCM SG_ 1437 MXB_R_HW_Idx_Z02 1000;
BA_REL_ "GenSigTimeoutTime" BU_SG_REL_ MXB SG_ 1437 MXB_R_HW_Idx_Z02 1000;
BA_REL_ "GenSigTimeoutTime" BU_SG_REL_ AFS SG_ 1306 MXB_L_Scheinw_Var_1 1000;
BA_REL_ "GenSigTimeoutTime" BU_SG_REL_ FCM SG_ 1306 MXB_L_Scheinw_Var_1 1000;
BA_REL_ "GenSigTimeoutTime" BU_SG_REL_ MXB SG_ 1306 MXB_L_Scheinw_Var_1 1000;
BA_REL_ "GenSigTimeoutTime" BU_SG_REL_ AFS SG_ 1306 MXB_L_Scheinw_Var_2 1000;
BA_REL_ "GenSigTimeoutTime" BU_SG_REL_ FCM SG_ 1306 MXB_L_Scheinw_Var_2 1000;
BA_REL_ "GenSigTimeoutTime" BU_SG_REL_ MXB SG_ 1306 MXB_L_Scheinw_Var_2 1000;
BA_REL_ "GenSigTimeoutTime" BU_SG_REL_ AFS SG_ 1307 MXB_R_Scheinw_Var_1 1000;
BA_REL_ "GenSigTimeoutTime" BU_SG_REL_ FCM SG_ 1307 MXB_R_Scheinw_Var_1 1000;
BA_REL_ "GenSigTimeoutTime" BU_SG_REL_ MXB SG_ 1307 MXB_R_Scheinw_Var_1 1000;
BA_REL_ "GenSigTimeoutTime" BU_SG_REL_ AFS SG_ 1307 MXB_R_Scheinw_Var_2 1000;
BA_REL_ "GenSigTimeoutTime" BU_SG_REL_ FCM SG_ 1307 MXB_R_Scheinw_Var_2 1000;
BA_REL_ "GenSigTimeoutTime" BU_SG_REL_ MXB SG_ 1307 MXB_R_Scheinw_Var_2 1000;
BA_REL_ "GenSigTimeoutTime" BU_SG_REL_ AFS SG_ 1405 MXB_L_Temp_Abblendl 5000;
BA_REL_ "GenSigTimeoutTime" BU_SG_REL_ FCM SG_ 1405 MXB_L_Temp_Abblendl 5000;
BA_REL_ "GenSigTimeoutTime" BU_SG_REL_ MXB SG_ 1405 MXB_L_Temp_Abblendl 5000;
BA_REL_ "GenSigTimeoutTime" BU_SG_REL_ AFS SG_ 1405 MXB_L_Temp_Fernl 5000;
BA_REL_ "GenSigTimeoutTime" BU_SG_REL_ FCM SG_ 1405 MXB_L_Temp_Fernl 5000;
BA_REL_ "GenSigTimeoutTime" BU_SG_REL_ MXB SG_ 1405 MXB_L_Temp_Fernl 5000;
BA_REL_ "GenSigTimeoutTime" BU_SG_REL_ AFS SG_ 1405 MXB_L_Temp_Elektronik 5000;
BA_REL_ "GenSigTimeoutTime" BU_SG_REL_ FCM SG_ 1405 MXB_L_Temp_Elektronik 5000;
BA_REL_ "GenSigTimeoutTime" BU_SG_REL_ MXB SG_ 1405 MXB_L_Temp_Elektronik 5000;
BA_REL_ "GenSigTimeoutTime" BU_SG_REL_ AFS SG_ 1405 MXB_L_Spannung_Klemme15 5000;
BA_REL_ "GenSigTimeoutTime" BU_SG_REL_ FCM SG_ 1405 MXB_L_Spannung_Klemme15 5000;
BA_REL_ "GenSigTimeoutTime" BU_SG_REL_ MXB SG_ 1405 MXB_L_Spannung_Klemme15 5000;
BA_REL_ "GenSigTimeoutTime" BU_SG_REL_ AFS SG_ 1405 MXB_L_Fernl_Dimmung 5000;
BA_REL_ "GenSigTimeoutTime" BU_SG_REL_ FCM SG_ 1405 MXB_L_Fernl_Dimmung 5000;
BA_REL_ "GenSigTimeoutTime" BU_SG_REL_ MXB SG_ 1405 MXB_L_Fernl_Dimmung 5000;
BA_REL_ "GenSigTimeoutTime" BU_SG_REL_ AFS SG_ 1405 MXB_L_Fernl_Temp_Schutz 5000;
BA_REL_ "GenSigTimeoutTime" BU_SG_REL_ FCM SG_ 1405 MXB_L_Fernl_Temp_Schutz 5000;
BA_REL_ "GenSigTimeoutTime" BU_SG_REL_ MXB SG_ 1405 MXB_L_Fernl_Temp_Schutz 5000;
BA_REL_ "GenSigTimeoutTime" BU_SG_REL_ AFS SG_ 1405 MXB_L_Fernl_Uspg_Schutz 5000;
BA_REL_ "GenSigTimeoutTime" BU_SG_REL_ FCM SG_ 1405 MXB_L_Fernl_Uspg_Schutz 5000;
BA_REL_ "GenSigTimeoutTime" BU_SG_REL_ MXB SG_ 1405 MXB_L_Fernl_Uspg_Schutz 5000;
BA_REL_ "GenSigTimeoutTime" BU_SG_REL_ FCM SG_ 2589283457 MXB_L_Spannung_Kanal1 5000;
BA_REL_ "GenSigTimeoutTime" BU_SG_REL_ MXB SG_ 2589283457 MXB_L_Spannung_Kanal1 5000;
BA_REL_ "GenSigTimeoutTime" BU_SG_REL_ FCM SG_ 2589283457 MXB_L_Spannung_Kanal2 5000;
BA_REL_ "GenSigTimeoutTime" BU_SG_REL_ MXB SG_ 2589283457 MXB_L_Spannung_Kanal2 5000;
BA_REL_ "GenSigTimeoutTime" BU_SG_REL_ FCM SG_ 2589283457 MXB_L_Spannung_Kanal3 5000;
BA_REL_ "GenSigTimeoutTime" BU_SG_REL_ MXB SG_ 2589283457 MXB_L_Spannung_Kanal3 5000;
BA_REL_ "GenSigTimeoutTime" BU_SG_REL_ FCM SG_ 2589283457 MXB_L_Strom_Kanal1 5000;
BA_REL_ "GenSigTimeoutTime" BU_SG_REL_ MXB SG_ 2589283457 MXB_L_Strom_Kanal1 5000;
BA_REL_ "GenSigTimeoutTime" BU_SG_REL_ FCM SG_ 2589283457 MXB_L_Strom_Kanal2 5000;
BA_REL_ "GenSigTimeoutTime" BU_SG_REL_ MXB SG_ 2589283457 MXB_L_Strom_Kanal2 5000;
BA_REL_ "GenSigTimeoutTime" BU_SG_REL_ FCM SG_ 2589283457 MXB_L_Strom_Kanal3 5000;
BA_REL_ "GenSigTimeoutTime" BU_SG_REL_ MXB SG_ 2589283457 MXB_L_Strom_Kanal3 5000;
BA_REL_ "GenSigTimeoutTime" BU_SG_REL_ AFS SG_ 1406 MXB_R_Temp_Abblendl 5000;
BA_REL_ "GenSigTimeoutTime" BU_SG_REL_ FCM SG_ 1406 MXB_R_Temp_Abblendl 5000;
BA_REL_ "GenSigTimeoutTime" BU_SG_REL_ MXB SG_ 1406 MXB_R_Temp_Abblendl 5000;
BA_REL_ "GenSigTimeoutTime" BU_SG_REL_ AFS SG_ 1406 MXB_R_Temp_Fernl 5000;
BA_REL_ "GenSigTimeoutTime" BU_SG_REL_ FCM SG_ 1406 MXB_R_Temp_Fernl 5000;
BA_REL_ "GenSigTimeoutTime" BU_SG_REL_ MXB SG_ 1406 MXB_R_Temp_Fernl 5000;
BA_REL_ "GenSigTimeoutTime" BU_SG_REL_ AFS SG_ 1406 MXB_R_Temp_Elektronik 5000;
BA_REL_ "GenSigTimeoutTime" BU_SG_REL_ FCM SG_ 1406 MXB_R_Temp_Elektronik 5000;
BA_REL_ "GenSigTimeoutTime" BU_SG_REL_ MXB SG_ 1406 MXB_R_Temp_Elektronik 5000;
BA_REL_ "GenSigTimeoutTime" BU_SG_REL_ AFS SG_ 1406 MXB_R_Spannung_Klemme15 5000;
BA_REL_ "GenSigTimeoutTime" BU_SG_REL_ FCM SG_ 1406 MXB_R_Spannung_Klemme15 5000;
BA_REL_ "GenSigTimeoutTime" BU_SG_REL_ MXB SG_ 1406 MXB_R_Spannung_Klemme15 5000;
BA_REL_ "GenSigTimeoutTime" BU_SG_REL_ AFS SG_ 1406 MXB_R_Fernl_Dimmung 5000;
BA_REL_ "GenSigTimeoutTime" BU_SG_REL_ FCM SG_ 1406 MXB_R_Fernl_Dimmung 5000;
BA_REL_ "GenSigTimeoutTime" BU_SG_REL_ MXB SG_ 1406 MXB_R_Fernl_Dimmung 5000;
BA_REL_ "GenSigTimeoutTime" BU_SG_REL_ AFS SG_ 1406 MXB_R_Fernl_Temp_Schutz 5000;
BA_REL_ "GenSigTimeoutTime" BU_SG_REL_ FCM SG_ 1406 MXB_R_Fernl_Temp_Schutz 5000;
BA_REL_ "GenSigTimeoutTime" BU_SG_REL_ MXB SG_ 1406 MXB_R_Fernl_Temp_Schutz 5000;
BA_REL_ "GenSigTimeoutTime" BU_SG_REL_ AFS SG_ 1406 MXB_R_Fernl_Uspg_Schutz 5000;
BA_REL_ "GenSigTimeoutTime" BU_SG_REL_ FCM SG_ 1406 MXB_R_Fernl_Uspg_Schutz 5000;
BA_REL_ "GenSigTimeoutTime" BU_SG_REL_ MXB SG_ 1406 MXB_R_Fernl_Uspg_Schutz 5000;
BA_REL_ "GenSigTimeoutTime" BU_SG_REL_ FCM SG_ 2589283458 MXB_R_Spannung_Kanal1 5000;
BA_REL_ "GenSigTimeoutTime" BU_SG_REL_ MXB SG_ 2589283458 MXB_R_Spannung_Kanal1 5000;
BA_REL_ "GenSigTimeoutTime" BU_SG_REL_ FCM SG_ 2589283458 MXB_R_Spannung_Kanal2 5000;
BA_REL_ "GenSigTimeoutTime" BU_SG_REL_ MXB SG_ 2589283458 MXB_R_Spannung_Kanal2 5000;
BA_REL_ "GenSigTimeoutTime" BU_SG_REL_ FCM SG_ 2589283458 MXB_R_Spannung_Kanal3 5000;
BA_REL_ "GenSigTimeoutTime" BU_SG_REL_ MXB SG_ 2589283458 MXB_R_Spannung_Kanal3 5000;
BA_REL_ "GenSigTimeoutTime" BU_SG_REL_ FCM SG_ 2589283458 MXB_R_Strom_Kanal1 5000;
BA_REL_ "GenSigTimeoutTime" BU_SG_REL_ MXB SG_ 2589283458 MXB_R_Strom_Kanal1 5000;
BA_REL_ "GenSigTimeoutTime" BU_SG_REL_ FCM SG_ 2589283458 MXB_R_Strom_Kanal2 5000;
BA_REL_ "GenSigTimeoutTime" BU_SG_REL_ MXB SG_ 2589283458 MXB_R_Strom_Kanal2 5000;
BA_REL_ "GenSigTimeoutTime" BU_SG_REL_ FCM SG_ 2589283458 MXB_R_Strom_Kanal3 5000;
BA_REL_ "GenSigTimeoutTime" BU_SG_REL_ MXB SG_ 2589283458 MXB_R_Strom_Kanal3 5000;
BA_REL_ "GenSigTimeoutTime" BU_SG_REL_ LED_DK3_LM_L SG_ 352 MXB_LED_01_Anf 2000;
BA_REL_ "GenSigTimeoutTime" BU_SG_REL_ LED_LM_L SG_ 352 MXB_LED_01_Anf 2000;
BA_REL_ "GenSigTimeoutTime" BU_SG_REL_ LLP_L SG_ 352 MXB_LED_01_Anf 2000;
BA_REL_ "GenSigTimeoutTime" BU_SG_REL_ LWR_MXB_L SG_ 352 MXB_LED_01_Anf 2000;
BA_REL_ "GenSigTimeoutTime" BU_SG_REL_ MXB_LM_L SG_ 352 MXB_LED_01_Anf 2000;
BA_REL_ "GenSigTimeoutTime" BU_SG_REL_ LED_DK3_LM_L SG_ 352 MXB_LED_02_Anf 2000;
BA_REL_ "GenSigTimeoutTime" BU_SG_REL_ LED_LM_L SG_ 352 MXB_LED_02_Anf 2000;
BA_REL_ "GenSigTimeoutTime" BU_SG_REL_ LLP_L SG_ 352 MXB_LED_02_Anf 2000;
BA_REL_ "GenSigTimeoutTime" BU_SG_REL_ LWR_MXB_L SG_ 352 MXB_LED_02_Anf 2000;
BA_REL_ "GenSigTimeoutTime" BU_SG_REL_ MXB_LM_L SG_ 352 MXB_LED_02_Anf 2000;
BA_REL_ "GenSigTimeoutTime" BU_SG_REL_ LED_DK3_LM_L SG_ 352 MXB_LED_03_Anf 2000;
BA_REL_ "GenSigTimeoutTime" BU_SG_REL_ LED_LM_L SG_ 352 MXB_LED_03_Anf 2000;
BA_REL_ "GenSigTimeoutTime" BU_SG_REL_ LLP_L SG_ 352 MXB_LED_03_Anf 2000;
BA_REL_ "GenSigTimeoutTime" BU_SG_REL_ LWR_MXB_L SG_ 352 MXB_LED_03_Anf 2000;
BA_REL_ "GenSigTimeoutTime" BU_SG_REL_ MXB_LM_L SG_ 352 MXB_LED_03_Anf 2000;
BA_REL_ "GenSigTimeoutTime" BU_SG_REL_ LED_DK3_LM_L SG_ 352 MXB_LED_04_Anf 2000;
BA_REL_ "GenSigTimeoutTime" BU_SG_REL_ LED_LM_L SG_ 352 MXB_LED_04_Anf 2000;
BA_REL_ "GenSigTimeoutTime" BU_SG_REL_ LLP_L SG_ 352 MXB_LED_04_Anf 2000;
BA_REL_ "GenSigTimeoutTime" BU_SG_REL_ LWR_MXB_L SG_ 352 MXB_LED_04_Anf 2000;
BA_REL_ "GenSigTimeoutTime" BU_SG_REL_ MXB_LM_L SG_ 352 MXB_LED_04_Anf 2000;
BA_REL_ "GenSigTimeoutTime" BU_SG_REL_ LED_DK3_LM_L SG_ 352 MXB_LED_05_Anf 2000;
BA_REL_ "GenSigTimeoutTime" BU_SG_REL_ LED_LM_L SG_ 352 MXB_LED_05_Anf 2000;
BA_REL_ "GenSigTimeoutTime" BU_SG_REL_ LLP_L SG_ 352 MXB_LED_05_Anf 2000;
BA_REL_ "GenSigTimeoutTime" BU_SG_REL_ LWR_MXB_L SG_ 352 MXB_LED_05_Anf 2000;
BA_REL_ "GenSigTimeoutTime" BU_SG_REL_ MXB_LM_L SG_ 352 MXB_LED_05_Anf 2000;
BA_REL_ "GenSigTimeoutTime" BU_SG_REL_ LED_DK3_LM_L SG_ 352 MXB_LED_06_Anf 2000;
BA_REL_ "GenSigTimeoutTime" BU_SG_REL_ LED_LM_L SG_ 352 MXB_LED_06_Anf 2000;
BA_REL_ "GenSigTimeoutTime" BU_SG_REL_ LLP_L SG_ 352 MXB_LED_06_Anf 2000;
BA_REL_ "GenSigTimeoutTime" BU_SG_REL_ LWR_MXB_L SG_ 352 MXB_LED_06_Anf 2000;
BA_REL_ "GenSigTimeoutTime" BU_SG_REL_ MXB_LM_L SG_ 352 MXB_LED_06_Anf 2000;
BA_REL_ "GenSigTimeoutTime" BU_SG_REL_ LED_DK3_LM_L SG_ 352 MXB_LED_07_Anf 2000;
BA_REL_ "GenSigTimeoutTime" BU_SG_REL_ LED_LM_L SG_ 352 MXB_LED_07_Anf 2000;
BA_REL_ "GenSigTimeoutTime" BU_SG_REL_ LLP_L SG_ 352 MXB_LED_07_Anf 2000;
BA_REL_ "GenSigTimeoutTime" BU_SG_REL_ LWR_MXB_L SG_ 352 MXB_LED_07_Anf 2000;
BA_REL_ "GenSigTimeoutTime" BU_SG_REL_ MXB_LM_L SG_ 352 MXB_LED_07_Anf 2000;
BA_REL_ "GenSigTimeoutTime" BU_SG_REL_ LED_DK3_LM_L SG_ 352 MXB_LED_08_Anf 2000;
BA_REL_ "GenSigTimeoutTime" BU_SG_REL_ LED_LM_L SG_ 352 MXB_LED_08_Anf 2000;
BA_REL_ "GenSigTimeoutTime" BU_SG_REL_ LLP_L SG_ 352 MXB_LED_08_Anf 2000;
BA_REL_ "GenSigTimeoutTime" BU_SG_REL_ LWR_MXB_L SG_ 352 MXB_LED_08_Anf 2000;
BA_REL_ "GenSigTimeoutTime" BU_SG_REL_ MXB_LM_L SG_ 352 MXB_LED_08_Anf 2000;
BA_REL_ "GenSigTimeoutTime" BU_SG_REL_ LED_DK3_LM_L SG_ 352 MXB_LED_09_Anf 2000;
BA_REL_ "GenSigTimeoutTime" BU_SG_REL_ LED_LM_L SG_ 352 MXB_LED_09_Anf 2000;
BA_REL_ "GenSigTimeoutTime" BU_SG_REL_ LLP_L SG_ 352 MXB_LED_09_Anf 2000;
BA_REL_ "GenSigTimeoutTime" BU_SG_REL_ LWR_MXB_L SG_ 352 MXB_LED_09_Anf 2000;
BA_REL_ "GenSigTimeoutTime" BU_SG_REL_ MXB_LM_L SG_ 352 MXB_LED_09_Anf 2000;
BA_REL_ "GenSigTimeoutTime" BU_SG_REL_ LED_DK3_LM_L SG_ 352 MXB_LED_10_Anf 2000;
BA_REL_ "GenSigTimeoutTime" BU_SG_REL_ LED_LM_L SG_ 352 MXB_LED_10_Anf 2000;
BA_REL_ "GenSigTimeoutTime" BU_SG_REL_ LLP_L SG_ 352 MXB_LED_10_Anf 2000;
BA_REL_ "GenSigTimeoutTime" BU_SG_REL_ LWR_MXB_L SG_ 352 MXB_LED_10_Anf 2000;
BA_REL_ "GenSigTimeoutTime" BU_SG_REL_ MXB_LM_L SG_ 352 MXB_LED_10_Anf 2000;
BA_REL_ "GenSigTimeoutTime" BU_SG_REL_ LED_DK3_LM_L SG_ 353 MXB_LED_11_Anf 2000;
BA_REL_ "GenSigTimeoutTime" BU_SG_REL_ LED_LM_L SG_ 353 MXB_LED_11_Anf 2000;
BA_REL_ "GenSigTimeoutTime" BU_SG_REL_ LLP_L SG_ 353 MXB_LED_11_Anf 2000;
BA_REL_ "GenSigTimeoutTime" BU_SG_REL_ LWR_MXB_L SG_ 353 MXB_LED_11_Anf 2000;
BA_REL_ "GenSigTimeoutTime" BU_SG_REL_ MXB_LM_L SG_ 353 MXB_LED_11_Anf 2000;
BA_REL_ "GenSigTimeoutTime" BU_SG_REL_ LED_DK3_LM_L SG_ 353 MXB_LED_12_Anf 2000;
BA_REL_ "GenSigTimeoutTime" BU_SG_REL_ LED_LM_L SG_ 353 MXB_LED_12_Anf 2000;
BA_REL_ "GenSigTimeoutTime" BU_SG_REL_ LLP_L SG_ 353 MXB_LED_12_Anf 2000;
BA_REL_ "GenSigTimeoutTime" BU_SG_REL_ LWR_MXB_L SG_ 353 MXB_LED_12_Anf 2000;
BA_REL_ "GenSigTimeoutTime" BU_SG_REL_ MXB_LM_L SG_ 353 MXB_LED_12_Anf 2000;
BA_REL_ "GenSigTimeoutTime" BU_SG_REL_ LED_DK3_LM_L SG_ 353 MXB_LED_13_Anf 2000;
BA_REL_ "GenSigTimeoutTime" BU_SG_REL_ LED_LM_L SG_ 353 MXB_LED_13_Anf 2000;
BA_REL_ "GenSigTimeoutTime" BU_SG_REL_ LLP_L SG_ 353 MXB_LED_13_Anf 2000;
BA_REL_ "GenSigTimeoutTime" BU_SG_REL_ MXB_LM_L SG_ 353 MXB_LED_13_Anf 2000;
BA_REL_ "GenSigTimeoutTime" BU_SG_REL_ LED_DK3_LM_L SG_ 353 MXB_LED_14_Anf 2000;
BA_REL_ "GenSigTimeoutTime" BU_SG_REL_ LED_LM_L SG_ 353 MXB_LED_14_Anf 2000;
BA_REL_ "GenSigTimeoutTime" BU_SG_REL_ LLP_L SG_ 353 MXB_LED_14_Anf 2000;
BA_REL_ "GenSigTimeoutTime" BU_SG_REL_ MXB_LM_L SG_ 353 MXB_LED_14_Anf 2000;
BA_REL_ "GenSigTimeoutTime" BU_SG_REL_ LED_DK3_LM_L SG_ 353 MXB_LED_15_Anf 2000;
BA_REL_ "GenSigTimeoutTime" BU_SG_REL_ LED_LM_L SG_ 353 MXB_LED_15_Anf 2000;
BA_REL_ "GenSigTimeoutTime" BU_SG_REL_ LLP_L SG_ 353 MXB_LED_15_Anf 2000;
BA_REL_ "GenSigTimeoutTime" BU_SG_REL_ MXB_LM_L SG_ 353 MXB_LED_15_Anf 2000;
BA_REL_ "GenSigTimeoutTime" BU_SG_REL_ LED_DK3_LM_L SG_ 353 MXB_LED_16_Anf 2000;
BA_REL_ "GenSigTimeoutTime" BU_SG_REL_ LED_LM_L SG_ 353 MXB_LED_16_Anf 2000;
BA_REL_ "GenSigTimeoutTime" BU_SG_REL_ LLP_L SG_ 353 MXB_LED_16_Anf 2000;
BA_REL_ "GenSigTimeoutTime" BU_SG_REL_ MXB_LM_L SG_ 353 MXB_LED_16_Anf 2000;
BA_REL_ "GenSigTimeoutTime" BU_SG_REL_ LED_DK3_LM_L SG_ 353 MXB_LED_17_Anf 2000;
BA_REL_ "GenSigTimeoutTime" BU_SG_REL_ LED_LM_L SG_ 353 MXB_LED_17_Anf 2000;
BA_REL_ "GenSigTimeoutTime" BU_SG_REL_ LLP_L SG_ 353 MXB_LED_17_Anf 2000;
BA_REL_ "GenSigTimeoutTime" BU_SG_REL_ MXB_LM_L SG_ 353 MXB_LED_17_Anf 2000;
BA_REL_ "GenSigTimeoutTime" BU_SG_REL_ LED_DK3_LM_L SG_ 353 MXB_LED_18_Anf 2000;
BA_REL_ "GenSigTimeoutTime" BU_SG_REL_ LED_LM_L SG_ 353 MXB_LED_18_Anf 2000;
BA_REL_ "GenSigTimeoutTime" BU_SG_REL_ LLP_L SG_ 353 MXB_LED_18_Anf 2000;
BA_REL_ "GenSigTimeoutTime" BU_SG_REL_ MXB_LM_L SG_ 353 MXB_LED_18_Anf 2000;
BA_REL_ "GenSigTimeoutTime" BU_SG_REL_ LED_DK3_LM_L SG_ 353 MXB_LED_19_Anf 2000;
BA_REL_ "GenSigTimeoutTime" BU_SG_REL_ LED_LM_L SG_ 353 MXB_LED_19_Anf 2000;
BA_REL_ "GenSigTimeoutTime" BU_SG_REL_ LLP_L SG_ 353 MXB_LED_19_Anf 2000;
BA_REL_ "GenSigTimeoutTime" BU_SG_REL_ MXB_LM_L SG_ 353 MXB_LED_19_Anf 2000;
BA_REL_ "GenSigTimeoutTime" BU_SG_REL_ LED_DK3_LM_L SG_ 353 MXB_LED_20_Anf 2000;
BA_REL_ "GenSigTimeoutTime" BU_SG_REL_ LED_LM_L SG_ 353 MXB_LED_20_Anf 2000;
BA_REL_ "GenSigTimeoutTime" BU_SG_REL_ LLP_L SG_ 353 MXB_LED_20_Anf 2000;
BA_REL_ "GenSigTimeoutTime" BU_SG_REL_ MXB_LM_L SG_ 353 MXB_LED_20_Anf 2000;
BA_REL_ "GenSigTimeoutTime" BU_SG_REL_ LED_DK3_LM_R SG_ 362 MXB_LED_101_Anf 2000;
BA_REL_ "GenSigTimeoutTime" BU_SG_REL_ LLP_R SG_ 362 MXB_LED_101_Anf 2000;
BA_REL_ "GenSigTimeoutTime" BU_SG_REL_ LED_DK3_LM_R SG_ 362 MXB_LED_102_Anf 2000;
BA_REL_ "GenSigTimeoutTime" BU_SG_REL_ LLP_R SG_ 362 MXB_LED_102_Anf 2000;
BA_REL_ "GenSigTimeoutTime" BU_SG_REL_ LED_DK3_LM_R SG_ 362 MXB_LED_103_Anf 2000;
BA_REL_ "GenSigTimeoutTime" BU_SG_REL_ LLP_R SG_ 362 MXB_LED_103_Anf 2000;
BA_REL_ "GenSigTimeoutTime" BU_SG_REL_ LED_DK3_LM_R SG_ 362 MXB_LED_104_Anf 2000;
BA_REL_ "GenSigTimeoutTime" BU_SG_REL_ LLP_R SG_ 362 MXB_LED_104_Anf 2000;
BA_REL_ "GenSigTimeoutTime" BU_SG_REL_ LED_DK3_LM_R SG_ 362 MXB_LED_105_Anf 2000;
BA_REL_ "GenSigTimeoutTime" BU_SG_REL_ LLP_R SG_ 362 MXB_LED_105_Anf 2000;
BA_REL_ "GenSigTimeoutTime" BU_SG_REL_ LED_DK3_LM_R SG_ 362 MXB_LED_106_Anf 2000;
BA_REL_ "GenSigTimeoutTime" BU_SG_REL_ LLP_R SG_ 362 MXB_LED_106_Anf 2000;
BA_REL_ "GenSigTimeoutTime" BU_SG_REL_ LED_DK3_LM_R SG_ 362 MXB_LED_107_Anf 2000;
BA_REL_ "GenSigTimeoutTime" BU_SG_REL_ LLP_R SG_ 362 MXB_LED_107_Anf 2000;
BA_REL_ "GenSigTimeoutTime" BU_SG_REL_ LED_DK3_LM_R SG_ 362 MXB_LED_108_Anf 2000;
BA_REL_ "GenSigTimeoutTime" BU_SG_REL_ LLP_R SG_ 362 MXB_LED_108_Anf 2000;
BA_REL_ "GenSigTimeoutTime" BU_SG_REL_ LED_DK3_LM_R SG_ 362 MXB_LED_109_Anf 2000;
BA_REL_ "GenSigTimeoutTime" BU_SG_REL_ LLP_R SG_ 362 MXB_LED_109_Anf 2000;
BA_REL_ "GenSigTimeoutTime" BU_SG_REL_ LED_DK3_LM_R SG_ 362 MXB_LED_110_Anf 2000;
BA_REL_ "GenSigTimeoutTime" BU_SG_REL_ LLP_R SG_ 362 MXB_LED_110_Anf 2000;
BA_REL_ "GenSigTimeoutTime" BU_SG_REL_ LED_DK3_LM_R SG_ 363 MXB_LED_111_Anf 2000;
BA_REL_ "GenSigTimeoutTime" BU_SG_REL_ LLP_R SG_ 363 MXB_LED_111_Anf 2000;
BA_REL_ "GenSigTimeoutTime" BU_SG_REL_ LED_DK3_LM_R SG_ 363 MXB_LED_112_Anf 2000;
BA_REL_ "GenSigTimeoutTime" BU_SG_REL_ LLP_R SG_ 363 MXB_LED_112_Anf 2000;
BA_REL_ "GenSigTimeoutTime" BU_SG_REL_ LED_DK3_LM_R SG_ 363 MXB_LED_113_Anf 2000;
BA_REL_ "GenSigTimeoutTime" BU_SG_REL_ LLP_R SG_ 363 MXB_LED_113_Anf 2000;
BA_REL_ "GenSigTimeoutTime" BU_SG_REL_ LED_DK3_LM_R SG_ 363 MXB_LED_114_Anf 2000;
BA_REL_ "GenSigTimeoutTime" BU_SG_REL_ LLP_R SG_ 363 MXB_LED_114_Anf 2000;
BA_REL_ "GenSigTimeoutTime" BU_SG_REL_ LED_DK3_LM_R SG_ 363 MXB_LED_115_Anf 2000;
BA_REL_ "GenSigTimeoutTime" BU_SG_REL_ LLP_R SG_ 363 MXB_LED_115_Anf 2000;
BA_REL_ "GenSigTimeoutTime" BU_SG_REL_ LED_DK3_LM_R SG_ 363 MXB_LED_116_Anf 2000;
BA_REL_ "GenSigTimeoutTime" BU_SG_REL_ LLP_R SG_ 363 MXB_LED_116_Anf 2000;
BA_REL_ "GenSigTimeoutTime" BU_SG_REL_ LED_DK3_LM_R SG_ 363 MXB_LED_117_Anf 2000;
BA_REL_ "GenSigTimeoutTime" BU_SG_REL_ LLP_R SG_ 363 MXB_LED_117_Anf 2000;
BA_REL_ "GenSigTimeoutTime" BU_SG_REL_ LED_DK3_LM_R SG_ 363 MXB_LED_118_Anf 2000;
BA_REL_ "GenSigTimeoutTime" BU_SG_REL_ LLP_R SG_ 363 MXB_LED_118_Anf 2000;
BA_REL_ "GenSigTimeoutTime" BU_SG_REL_ LED_DK3_LM_R SG_ 363 MXB_LED_119_Anf 2000;
BA_REL_ "GenSigTimeoutTime" BU_SG_REL_ LLP_R SG_ 363 MXB_LED_119_Anf 2000;
BA_REL_ "GenSigTimeoutTime" BU_SG_REL_ LED_DK3_LM_R SG_ 363 MXB_LED_120_Anf 2000;
BA_REL_ "GenSigTimeoutTime" BU_SG_REL_ LLP_R SG_ 363 MXB_LED_120_Anf 2000;
BA_REL_ "GenSigTimeoutTime" BU_SG_REL_ LED_DK3_LM_R SG_ 364 MXB_LED_121_Anf 2000;
BA_REL_ "GenSigTimeoutTime" BU_SG_REL_ LLP_R SG_ 364 MXB_LED_121_Anf 2000;
BA_REL_ "GenSigTimeoutTime" BU_SG_REL_ LED_DK3_LM_R SG_ 364 MXB_LED_122_Anf 2000;
BA_REL_ "GenSigTimeoutTime" BU_SG_REL_ LLP_R SG_ 364 MXB_LED_122_Anf 2000;
BA_REL_ "GenSigTimeoutTime" BU_SG_REL_ LED_DK3_LM_R SG_ 364 MXB_LED_123_Anf 2000;
BA_REL_ "GenSigTimeoutTime" BU_SG_REL_ LLP_R SG_ 364 MXB_LED_123_Anf 2000;
BA_REL_ "GenSigTimeoutTime" BU_SG_REL_ LED_DK3_LM_R SG_ 364 MXB_LED_124_Anf 2000;
BA_REL_ "GenSigTimeoutTime" BU_SG_REL_ LLP_R SG_ 364 MXB_LED_124_Anf 2000;
BA_REL_ "GenSigTimeoutTime" BU_SG_REL_ LED_DK3_LM_R SG_ 364 MXB_LED_125_Anf 2000;
BA_REL_ "GenSigTimeoutTime" BU_SG_REL_ LLP_R SG_ 364 MXB_LED_125_Anf 2000;
BA_REL_ "GenSigTimeoutTime" BU_SG_REL_ LED_DK3_LM_R SG_ 364 MXB_LED_126_Anf 2000;
BA_REL_ "GenSigTimeoutTime" BU_SG_REL_ LLP_R SG_ 364 MXB_LED_126_Anf 2000;
BA_REL_ "GenSigTimeoutTime" BU_SG_REL_ LED_DK3_LM_R SG_ 364 MXB_LED_127_Anf 2000;
BA_REL_ "GenSigTimeoutTime" BU_SG_REL_ LLP_R SG_ 364 MXB_LED_127_Anf 2000;
BA_REL_ "GenSigTimeoutTime" BU_SG_REL_ LED_DK3_LM_R SG_ 364 MXB_LED_128_Anf 2000;
BA_REL_ "GenSigTimeoutTime" BU_SG_REL_ LLP_R SG_ 364 MXB_LED_128_Anf 2000;
BA_REL_ "GenSigTimeoutTime" BU_SG_REL_ LED_DK3_LM_R SG_ 364 MXB_LED_129_Anf 2000;
BA_REL_ "GenSigTimeoutTime" BU_SG_REL_ LLP_R SG_ 364 MXB_LED_129_Anf 2000;
BA_REL_ "GenSigTimeoutTime" BU_SG_REL_ LED_DK3_LM_R SG_ 364 MXB_LED_130_Anf 2000;
BA_REL_ "GenSigTimeoutTime" BU_SG_REL_ LLP_R SG_ 364 MXB_LED_130_Anf 2000;
BA_REL_ "GenSigTimeoutTime" BU_SG_REL_ LED_DK3_LM_R SG_ 365 MXB_LED_131_Anf 2000;
BA_REL_ "GenSigTimeoutTime" BU_SG_REL_ LLP_R SG_ 365 MXB_LED_131_Anf 2000;
BA_REL_ "GenSigTimeoutTime" BU_SG_REL_ LED_DK3_LM_R SG_ 365 MXB_LED_132_Anf 2000;
BA_REL_ "GenSigTimeoutTime" BU_SG_REL_ LLP_R SG_ 365 MXB_LED_132_Anf 2000;
BA_REL_ "GenSigTimeoutTime" BU_SG_REL_ LED_DK3_LM_R SG_ 365 MXB_LED_133_Anf 2000;
BA_REL_ "GenSigTimeoutTime" BU_SG_REL_ LLP_R SG_ 365 MXB_LED_133_Anf 2000;
BA_REL_ "GenSigTimeoutTime" BU_SG_REL_ LED_DK3_LM_R SG_ 365 MXB_LED_134_Anf 2000;
BA_REL_ "GenSigTimeoutTime" BU_SG_REL_ LLP_R SG_ 365 MXB_LED_134_Anf 2000;
BA_REL_ "GenSigTimeoutTime" BU_SG_REL_ LED_DK3_LM_R SG_ 365 MXB_LED_135_Anf 2000;
BA_REL_ "GenSigTimeoutTime" BU_SG_REL_ LLP_R SG_ 365 MXB_LED_135_Anf 2000;
BA_REL_ "GenSigTimeoutTime" BU_SG_REL_ LED_DK3_LM_R SG_ 365 MXB_LED_136_Anf 2000;
BA_REL_ "GenSigTimeoutTime" BU_SG_REL_ LLP_R SG_ 365 MXB_LED_136_Anf 2000;
BA_REL_ "GenSigTimeoutTime" BU_SG_REL_ LED_DK3_LM_R SG_ 365 MXB_LED_137_Anf 2000;
BA_REL_ "GenSigTimeoutTime" BU_SG_REL_ LLP_R SG_ 365 MXB_LED_137_Anf 2000;
BA_REL_ "GenSigTimeoutTime" BU_SG_REL_ LED_DK3_LM_R SG_ 365 MXB_LED_138_Anf 2000;
BA_REL_ "GenSigTimeoutTime" BU_SG_REL_ LLP_R SG_ 365 MXB_LED_138_Anf 2000;
BA_REL_ "GenSigTimeoutTime" BU_SG_REL_ LED_DK3_LM_R SG_ 365 MXB_LED_139_Anf 2000;
BA_REL_ "GenSigTimeoutTime" BU_SG_REL_ LLP_R SG_ 365 MXB_LED_139_Anf 2000;
BA_REL_ "GenSigTimeoutTime" BU_SG_REL_ LED_DK3_LM_R SG_ 365 MXB_LED_140_Anf 2000;
BA_REL_ "GenSigTimeoutTime" BU_SG_REL_ LLP_R SG_ 365 MXB_LED_140_Anf 2000;
BA_REL_ "GenSigTimeoutTime" BU_SG_REL_ LED_DK3_LM_R SG_ 366 MXB_LED_141_Anf 2000;
BA_REL_ "GenSigTimeoutTime" BU_SG_REL_ LLP_R SG_ 366 MXB_LED_141_Anf 2000;
BA_REL_ "GenSigTimeoutTime" BU_SG_REL_ LED_DK3_LM_R SG_ 366 MXB_LED_142_Anf 2000;
BA_REL_ "GenSigTimeoutTime" BU_SG_REL_ LLP_R SG_ 366 MXB_LED_142_Anf 2000;
BA_REL_ "GenSigTimeoutTime" BU_SG_REL_ LED_DK3_LM_R SG_ 366 MXB_LED_143_Anf 2000;
BA_REL_ "GenSigTimeoutTime" BU_SG_REL_ LLP_R SG_ 366 MXB_LED_143_Anf 2000;
BA_REL_ "GenSigTimeoutTime" BU_SG_REL_ LED_DK3_LM_R SG_ 366 MXB_LED_144_Anf 2000;
BA_REL_ "GenSigTimeoutTime" BU_SG_REL_ LLP_R SG_ 366 MXB_LED_144_Anf 2000;
BA_REL_ "GenSigTimeoutTime" BU_SG_REL_ LED_DK3_LM_R SG_ 366 MXB_LED_145_Anf 2000;
BA_REL_ "GenSigTimeoutTime" BU_SG_REL_ LLP_R SG_ 366 MXB_LED_145_Anf 2000;
BA_REL_ "GenSigTimeoutTime" BU_SG_REL_ LED_DK3_LM_R SG_ 366 MXB_LED_146_Anf 2000;
BA_REL_ "GenSigTimeoutTime" BU_SG_REL_ LLP_R SG_ 366 MXB_LED_146_Anf 2000;
BA_REL_ "GenSigTimeoutTime" BU_SG_REL_ LED_DK3_LM_R SG_ 366 MXB_LED_147_Anf 2000;
BA_REL_ "GenSigTimeoutTime" BU_SG_REL_ LLP_R SG_ 366 MXB_LED_147_Anf 2000;
BA_REL_ "GenSigTimeoutTime" BU_SG_REL_ LED_DK3_LM_R SG_ 366 MXB_LED_148_Anf 2000;
BA_REL_ "GenSigTimeoutTime" BU_SG_REL_ LLP_R SG_ 366 MXB_LED_148_Anf 2000;
BA_REL_ "GenSigTimeoutTime" BU_SG_REL_ LED_DK3_LM_R SG_ 366 MXB_LED_149_Anf 2000;
BA_REL_ "GenSigTimeoutTime" BU_SG_REL_ LLP_R SG_ 366 MXB_LED_149_Anf 2000;
BA_REL_ "GenSigTimeoutTime" BU_SG_REL_ LED_DK3_LM_R SG_ 366 MXB_LED_150_Anf 2000;
BA_REL_ "GenSigTimeoutTime" BU_SG_REL_ LLP_R SG_ 366 MXB_LED_150_Anf 2000;
BA_REL_ "GenSigTimeoutTime" BU_SG_REL_ LED_DK3_LM_R SG_ 367 MXB_LED_151_Anf 2000;
BA_REL_ "GenSigTimeoutTime" BU_SG_REL_ LLP_R SG_ 367 MXB_LED_151_Anf 2000;
BA_REL_ "GenSigTimeoutTime" BU_SG_REL_ LED_DK3_LM_R SG_ 367 MXB_LED_152_Anf 2000;
BA_REL_ "GenSigTimeoutTime" BU_SG_REL_ LLP_R SG_ 367 MXB_LED_152_Anf 2000;
BA_REL_ "GenSigTimeoutTime" BU_SG_REL_ LED_DK3_LM_R SG_ 367 MXB_LED_153_Anf 2000;
BA_REL_ "GenSigTimeoutTime" BU_SG_REL_ LLP_R SG_ 367 MXB_LED_153_Anf 2000;
BA_REL_ "GenSigTimeoutTime" BU_SG_REL_ LED_DK3_LM_R SG_ 367 MXB_LED_154_Anf 2000;
BA_REL_ "GenSigTimeoutTime" BU_SG_REL_ LLP_R SG_ 367 MXB_LED_154_Anf 2000;
BA_REL_ "GenSigTimeoutTime" BU_SG_REL_ LED_DK3_LM_R SG_ 367 MXB_LED_155_Anf 2000;
BA_REL_ "GenSigTimeoutTime" BU_SG_REL_ LLP_R SG_ 367 MXB_LED_155_Anf 2000;
BA_REL_ "GenSigTimeoutTime" BU_SG_REL_ LED_DK3_LM_R SG_ 367 MXB_LED_156_Anf 2000;
BA_REL_ "GenSigTimeoutTime" BU_SG_REL_ LLP_R SG_ 367 MXB_LED_156_Anf 2000;
BA_REL_ "GenSigTimeoutTime" BU_SG_REL_ LED_DK3_LM_R SG_ 367 MXB_LED_157_Anf 2000;
BA_REL_ "GenSigTimeoutTime" BU_SG_REL_ LLP_R SG_ 367 MXB_LED_157_Anf 2000;
BA_REL_ "GenSigTimeoutTime" BU_SG_REL_ LED_DK3_LM_R SG_ 367 MXB_LED_158_Anf 2000;
BA_REL_ "GenSigTimeoutTime" BU_SG_REL_ LLP_R SG_ 367 MXB_LED_158_Anf 2000;
BA_REL_ "GenSigTimeoutTime" BU_SG_REL_ LED_DK3_LM_R SG_ 367 MXB_LED_159_Anf 2000;
BA_REL_ "GenSigTimeoutTime" BU_SG_REL_ LLP_R SG_ 367 MXB_LED_159_Anf 2000;
BA_REL_ "GenSigTimeoutTime" BU_SG_REL_ LED_DK3_LM_R SG_ 367 MXB_LED_160_Anf 2000;
BA_REL_ "GenSigTimeoutTime" BU_SG_REL_ LLP_R SG_ 367 MXB_LED_160_Anf 2000;
BA_REL_ "GenSigTimeoutTime" BU_SG_REL_ LED_DK3_LM_R SG_ 372 MXB_LED_161_Anf 2000;
BA_REL_ "GenSigTimeoutTime" BU_SG_REL_ LLP_R SG_ 372 MXB_LED_161_Anf 2000;
BA_REL_ "GenSigTimeoutTime" BU_SG_REL_ LED_DK3_LM_R SG_ 372 MXB_LED_162_Anf 2000;
BA_REL_ "GenSigTimeoutTime" BU_SG_REL_ LLP_R SG_ 372 MXB_LED_162_Anf 2000;
BA_REL_ "GenSigTimeoutTime" BU_SG_REL_ LED_DK3_LM_R SG_ 372 MXB_LED_163_Anf 2000;
BA_REL_ "GenSigTimeoutTime" BU_SG_REL_ LLP_R SG_ 372 MXB_LED_163_Anf 2000;
BA_REL_ "GenSigTimeoutTime" BU_SG_REL_ LED_DK3_LM_R SG_ 372 MXB_LED_164_Anf 2000;
BA_REL_ "GenSigTimeoutTime" BU_SG_REL_ LLP_R SG_ 372 MXB_LED_164_Anf 2000;
BA_REL_ "GenSigTimeoutTime" BU_SG_REL_ LED_DK3_LM_R SG_ 372 MXB_LED_165_Anf 2000;
BA_REL_ "GenSigTimeoutTime" BU_SG_REL_ LLP_R SG_ 372 MXB_LED_165_Anf 2000;
BA_REL_ "GenSigTimeoutTime" BU_SG_REL_ LED_DK3_LM_R SG_ 372 MXB_LED_166_Anf 2000;
BA_REL_ "GenSigTimeoutTime" BU_SG_REL_ LLP_R SG_ 372 MXB_LED_166_Anf 2000;
BA_REL_ "GenSigTimeoutTime" BU_SG_REL_ LED_DK3_LM_R SG_ 372 MXB_LED_167_Anf 2000;
BA_REL_ "GenSigTimeoutTime" BU_SG_REL_ LLP_R SG_ 372 MXB_LED_167_Anf 2000;
BA_REL_ "GenSigTimeoutTime" BU_SG_REL_ LED_DK3_LM_R SG_ 372 MXB_LED_168_Anf 2000;
BA_REL_ "GenSigTimeoutTime" BU_SG_REL_ LLP_R SG_ 372 MXB_LED_168_Anf 2000;
BA_REL_ "GenSigTimeoutTime" BU_SG_REL_ LED_DK3_LM_R SG_ 372 MXB_LED_169_Anf 2000;
BA_REL_ "GenSigTimeoutTime" BU_SG_REL_ LLP_R SG_ 372 MXB_LED_169_Anf 2000;
BA_REL_ "GenSigTimeoutTime" BU_SG_REL_ LED_DK3_LM_R SG_ 372 MXB_LED_170_Anf 2000;
BA_REL_ "GenSigTimeoutTime" BU_SG_REL_ LLP_R SG_ 372 MXB_LED_170_Anf 2000;
BA_REL_ "GenSigTimeoutTime" BU_SG_REL_ LED_DK3_LM_R SG_ 373 MXB_LED_171_Anf 2000;
BA_REL_ "GenSigTimeoutTime" BU_SG_REL_ LLP_R SG_ 373 MXB_LED_171_Anf 2000;
BA_REL_ "GenSigTimeoutTime" BU_SG_REL_ LED_DK3_LM_R SG_ 373 MXB_LED_172_Anf 2000;
BA_REL_ "GenSigTimeoutTime" BU_SG_REL_ LLP_R SG_ 373 MXB_LED_172_Anf 2000;
BA_REL_ "GenSigTimeoutTime" BU_SG_REL_ LED_DK3_LM_R SG_ 373 MXB_LED_173_Anf 2000;
BA_REL_ "GenSigTimeoutTime" BU_SG_REL_ LLP_R SG_ 373 MXB_LED_173_Anf 2000;
BA_REL_ "GenSigTimeoutTime" BU_SG_REL_ LED_DK3_LM_R SG_ 373 MXB_LED_174_Anf 2000;
BA_REL_ "GenSigTimeoutTime" BU_SG_REL_ LLP_R SG_ 373 MXB_LED_174_Anf 2000;
BA_REL_ "GenSigTimeoutTime" BU_SG_REL_ LED_DK3_LM_R SG_ 373 MXB_LED_175_Anf 2000;
BA_REL_ "GenSigTimeoutTime" BU_SG_REL_ LLP_R SG_ 373 MXB_LED_175_Anf 2000;
BA_REL_ "GenSigTimeoutTime" BU_SG_REL_ LED_DK3_LM_R SG_ 373 MXB_LED_176_Anf 2000;
BA_REL_ "GenSigTimeoutTime" BU_SG_REL_ LLP_R SG_ 373 MXB_LED_176_Anf 2000;
BA_REL_ "GenSigTimeoutTime" BU_SG_REL_ LED_DK3_LM_R SG_ 373 MXB_LED_177_Anf 2000;
BA_REL_ "GenSigTimeoutTime" BU_SG_REL_ LLP_R SG_ 373 MXB_LED_177_Anf 2000;
BA_REL_ "GenSigTimeoutTime" BU_SG_REL_ LED_DK3_LM_R SG_ 373 MXB_LED_178_Anf 2000;
BA_REL_ "GenSigTimeoutTime" BU_SG_REL_ LLP_R SG_ 373 MXB_LED_178_Anf 2000;
BA_REL_ "GenSigTimeoutTime" BU_SG_REL_ LED_DK3_LM_R SG_ 373 MXB_LED_179_Anf 2000;
BA_REL_ "GenSigTimeoutTime" BU_SG_REL_ LLP_R SG_ 373 MXB_LED_179_Anf 2000;
BA_REL_ "GenSigTimeoutTime" BU_SG_REL_ LED_DK3_LM_R SG_ 373 MXB_LED_180_Anf 2000;
BA_REL_ "GenSigTimeoutTime" BU_SG_REL_ LLP_R SG_ 373 MXB_LED_180_Anf 2000;
BA_REL_ "GenSigTimeoutTime" BU_SG_REL_ LED_DK3_LM_L SG_ 354 MXB_LED_21_Anf 2000;
BA_REL_ "GenSigTimeoutTime" BU_SG_REL_ LED_LM_L SG_ 354 MXB_LED_21_Anf 2000;
BA_REL_ "GenSigTimeoutTime" BU_SG_REL_ LLP_L SG_ 354 MXB_LED_21_Anf 2000;
BA_REL_ "GenSigTimeoutTime" BU_SG_REL_ MXB_LM_L SG_ 354 MXB_LED_21_Anf 2000;
BA_REL_ "GenSigTimeoutTime" BU_SG_REL_ LED_DK3_LM_L SG_ 354 MXB_LED_22_Anf 2000;
BA_REL_ "GenSigTimeoutTime" BU_SG_REL_ LED_LM_L SG_ 354 MXB_LED_22_Anf 2000;
BA_REL_ "GenSigTimeoutTime" BU_SG_REL_ LLP_L SG_ 354 MXB_LED_22_Anf 2000;
BA_REL_ "GenSigTimeoutTime" BU_SG_REL_ MXB_LM_L SG_ 354 MXB_LED_22_Anf 2000;
BA_REL_ "GenSigTimeoutTime" BU_SG_REL_ LED_DK3_LM_L SG_ 354 MXB_LED_23_Anf 2000;
BA_REL_ "GenSigTimeoutTime" BU_SG_REL_ LED_LM_L SG_ 354 MXB_LED_23_Anf 2000;
BA_REL_ "GenSigTimeoutTime" BU_SG_REL_ LLP_L SG_ 354 MXB_LED_23_Anf 2000;
BA_REL_ "GenSigTimeoutTime" BU_SG_REL_ MXB_LM_L SG_ 354 MXB_LED_23_Anf 2000;
BA_REL_ "GenSigTimeoutTime" BU_SG_REL_ LED_DK3_LM_L SG_ 354 MXB_LED_24_Anf 2000;
BA_REL_ "GenSigTimeoutTime" BU_SG_REL_ LED_LM_L SG_ 354 MXB_LED_24_Anf 2000;
BA_REL_ "GenSigTimeoutTime" BU_SG_REL_ LLP_L SG_ 354 MXB_LED_24_Anf 2000;
BA_REL_ "GenSigTimeoutTime" BU_SG_REL_ MXB_LM_L SG_ 354 MXB_LED_24_Anf 2000;
BA_REL_ "GenSigTimeoutTime" BU_SG_REL_ LED_DK3_LM_L SG_ 354 MXB_LED_25_Anf 2000;
BA_REL_ "GenSigTimeoutTime" BU_SG_REL_ LED_LM_L SG_ 354 MXB_LED_25_Anf 2000;
BA_REL_ "GenSigTimeoutTime" BU_SG_REL_ LLP_L SG_ 354 MXB_LED_25_Anf 2000;
BA_REL_ "GenSigTimeoutTime" BU_SG_REL_ MXB_LM_L SG_ 354 MXB_LED_25_Anf 2000;
BA_REL_ "GenSigTimeoutTime" BU_SG_REL_ LED_DK3_LM_L SG_ 354 MXB_LED_26_Anf 2000;
BA_REL_ "GenSigTimeoutTime" BU_SG_REL_ LED_LM_L SG_ 354 MXB_LED_26_Anf 2000;
BA_REL_ "GenSigTimeoutTime" BU_SG_REL_ LLP_L SG_ 354 MXB_LED_26_Anf 2000;
BA_REL_ "GenSigTimeoutTime" BU_SG_REL_ MXB_LM_L SG_ 354 MXB_LED_26_Anf 2000;
BA_REL_ "GenSigTimeoutTime" BU_SG_REL_ LED_DK3_LM_L SG_ 354 MXB_LED_27_Anf 2000;
BA_REL_ "GenSigTimeoutTime" BU_SG_REL_ LED_LM_L SG_ 354 MXB_LED_27_Anf 2000;
BA_REL_ "GenSigTimeoutTime" BU_SG_REL_ LLP_L SG_ 354 MXB_LED_27_Anf 2000;
BA_REL_ "GenSigTimeoutTime" BU_SG_REL_ MXB_LM_L SG_ 354 MXB_LED_27_Anf 2000;
BA_REL_ "GenSigTimeoutTime" BU_SG_REL_ LED_DK3_LM_L SG_ 354 MXB_LED_28_Anf 2000;
BA_REL_ "GenSigTimeoutTime" BU_SG_REL_ LED_LM_L SG_ 354 MXB_LED_28_Anf 2000;
BA_REL_ "GenSigTimeoutTime" BU_SG_REL_ LLP_L SG_ 354 MXB_LED_28_Anf 2000;
BA_REL_ "GenSigTimeoutTime" BU_SG_REL_ MXB_LM_L SG_ 354 MXB_LED_28_Anf 2000;
BA_REL_ "GenSigTimeoutTime" BU_SG_REL_ LED_DK3_LM_L SG_ 354 MXB_LED_29_Anf 2000;
BA_REL_ "GenSigTimeoutTime" BU_SG_REL_ LED_LM_L SG_ 354 MXB_LED_29_Anf 2000;
BA_REL_ "GenSigTimeoutTime" BU_SG_REL_ LLP_L SG_ 354 MXB_LED_29_Anf 2000;
BA_REL_ "GenSigTimeoutTime" BU_SG_REL_ MXB_LM_L SG_ 354 MXB_LED_29_Anf 2000;
BA_REL_ "GenSigTimeoutTime" BU_SG_REL_ LED_DK3_LM_L SG_ 354 MXB_LED_30_Anf 2000;
BA_REL_ "GenSigTimeoutTime" BU_SG_REL_ LED_LM_L SG_ 354 MXB_LED_30_Anf 2000;
BA_REL_ "GenSigTimeoutTime" BU_SG_REL_ LLP_L SG_ 354 MXB_LED_30_Anf 2000;
BA_REL_ "GenSigTimeoutTime" BU_SG_REL_ MXB_LM_L SG_ 354 MXB_LED_30_Anf 2000;
BA_REL_ "GenSigTimeoutTime" BU_SG_REL_ LED_DK3_LM_L SG_ 355 MXB_LED_31_Anf 2000;
BA_REL_ "GenSigTimeoutTime" BU_SG_REL_ LED_LM_L SG_ 355 MXB_LED_31_Anf 2000;
BA_REL_ "GenSigTimeoutTime" BU_SG_REL_ LLP_L SG_ 355 MXB_LED_31_Anf 2000;
BA_REL_ "GenSigTimeoutTime" BU_SG_REL_ MXB_LM_L SG_ 355 MXB_LED_31_Anf 2000;
BA_REL_ "GenSigTimeoutTime" BU_SG_REL_ LED_DK3_LM_L SG_ 355 MXB_LED_32_Anf 2000;
BA_REL_ "GenSigTimeoutTime" BU_SG_REL_ LED_LM_L SG_ 355 MXB_LED_32_Anf 2000;
BA_REL_ "GenSigTimeoutTime" BU_SG_REL_ LLP_L SG_ 355 MXB_LED_32_Anf 2000;
BA_REL_ "GenSigTimeoutTime" BU_SG_REL_ MXB_LM_L SG_ 355 MXB_LED_32_Anf 2000;
BA_REL_ "GenSigTimeoutTime" BU_SG_REL_ LED_DK3_LM_L SG_ 355 MXB_LED_33_Anf 2000;
BA_REL_ "GenSigTimeoutTime" BU_SG_REL_ LED_LM_L SG_ 355 MXB_LED_33_Anf 2000;
BA_REL_ "GenSigTimeoutTime" BU_SG_REL_ LLP_L SG_ 355 MXB_LED_33_Anf 2000;
BA_REL_ "GenSigTimeoutTime" BU_SG_REL_ MXB_LM_L SG_ 355 MXB_LED_33_Anf 2000;
BA_REL_ "GenSigTimeoutTime" BU_SG_REL_ LED_DK3_LM_L SG_ 355 MXB_LED_34_Anf 2000;
BA_REL_ "GenSigTimeoutTime" BU_SG_REL_ LED_LM_L SG_ 355 MXB_LED_34_Anf 2000;
BA_REL_ "GenSigTimeoutTime" BU_SG_REL_ LLP_L SG_ 355 MXB_LED_34_Anf 2000;
BA_REL_ "GenSigTimeoutTime" BU_SG_REL_ MXB_LM_L SG_ 355 MXB_LED_34_Anf 2000;
BA_REL_ "GenSigTimeoutTime" BU_SG_REL_ LED_DK3_LM_L SG_ 355 MXB_LED_35_Anf 2000;
BA_REL_ "GenSigTimeoutTime" BU_SG_REL_ LED_LM_L SG_ 355 MXB_LED_35_Anf 2000;
BA_REL_ "GenSigTimeoutTime" BU_SG_REL_ LLP_L SG_ 355 MXB_LED_35_Anf 2000;
BA_REL_ "GenSigTimeoutTime" BU_SG_REL_ MXB_LM_L SG_ 355 MXB_LED_35_Anf 2000;
BA_REL_ "GenSigTimeoutTime" BU_SG_REL_ LED_DK3_LM_L SG_ 355 MXB_LED_36_Anf 2000;
BA_REL_ "GenSigTimeoutTime" BU_SG_REL_ LED_LM_L SG_ 355 MXB_LED_36_Anf 2000;
BA_REL_ "GenSigTimeoutTime" BU_SG_REL_ LLP_L SG_ 355 MXB_LED_36_Anf 2000;
BA_REL_ "GenSigTimeoutTime" BU_SG_REL_ MXB_LM_L SG_ 355 MXB_LED_36_Anf 2000;
BA_REL_ "GenSigTimeoutTime" BU_SG_REL_ LED_DK3_LM_L SG_ 355 MXB_LED_37_Anf 2000;
BA_REL_ "GenSigTimeoutTime" BU_SG_REL_ LED_LM_L SG_ 355 MXB_LED_37_Anf 2000;
BA_REL_ "GenSigTimeoutTime" BU_SG_REL_ LLP_L SG_ 355 MXB_LED_37_Anf 2000;
BA_REL_ "GenSigTimeoutTime" BU_SG_REL_ MXB_LM_L SG_ 355 MXB_LED_37_Anf 2000;
BA_REL_ "GenSigTimeoutTime" BU_SG_REL_ LED_DK3_LM_L SG_ 355 MXB_LED_38_Anf 2000;
BA_REL_ "GenSigTimeoutTime" BU_SG_REL_ LED_LM_L SG_ 355 MXB_LED_38_Anf 2000;
BA_REL_ "GenSigTimeoutTime" BU_SG_REL_ LLP_L SG_ 355 MXB_LED_38_Anf 2000;
BA_REL_ "GenSigTimeoutTime" BU_SG_REL_ MXB_LM_L SG_ 355 MXB_LED_38_Anf 2000;
BA_REL_ "GenSigTimeoutTime" BU_SG_REL_ LED_DK3_LM_L SG_ 355 MXB_LED_39_Anf 2000;
BA_REL_ "GenSigTimeoutTime" BU_SG_REL_ LED_LM_L SG_ 355 MXB_LED_39_Anf 2000;
BA_REL_ "GenSigTimeoutTime" BU_SG_REL_ LLP_L SG_ 355 MXB_LED_39_Anf 2000;
BA_REL_ "GenSigTimeoutTime" BU_SG_REL_ MXB_LM_L SG_ 355 MXB_LED_39_Anf 2000;
BA_REL_ "GenSigTimeoutTime" BU_SG_REL_ LED_DK3_LM_L SG_ 355 MXB_LED_40_Anf 2000;
BA_REL_ "GenSigTimeoutTime" BU_SG_REL_ LED_LM_L SG_ 355 MXB_LED_40_Anf 2000;
BA_REL_ "GenSigTimeoutTime" BU_SG_REL_ LLP_L SG_ 355 MXB_LED_40_Anf 2000;
BA_REL_ "GenSigTimeoutTime" BU_SG_REL_ MXB_LM_L SG_ 355 MXB_LED_40_Anf 2000;
BA_REL_ "GenSigTimeoutTime" BU_SG_REL_ LED_DK3_LM_L SG_ 356 MXB_LED_41_Anf 2000;
BA_REL_ "GenSigTimeoutTime" BU_SG_REL_ LED_LM_L SG_ 356 MXB_LED_41_Anf 2000;
BA_REL_ "GenSigTimeoutTime" BU_SG_REL_ LLP_L SG_ 356 MXB_LED_41_Anf 2000;
BA_REL_ "GenSigTimeoutTime" BU_SG_REL_ MXB_LM_L SG_ 356 MXB_LED_41_Anf 2000;
BA_REL_ "GenSigTimeoutTime" BU_SG_REL_ LED_DK3_LM_L SG_ 356 MXB_LED_42_Anf 2000;
BA_REL_ "GenSigTimeoutTime" BU_SG_REL_ LED_LM_L SG_ 356 MXB_LED_42_Anf 2000;
BA_REL_ "GenSigTimeoutTime" BU_SG_REL_ LLP_L SG_ 356 MXB_LED_42_Anf 2000;
BA_REL_ "GenSigTimeoutTime" BU_SG_REL_ MXB_LM_L SG_ 356 MXB_LED_42_Anf 2000;
BA_REL_ "GenSigTimeoutTime" BU_SG_REL_ LED_DK3_LM_L SG_ 356 MXB_LED_43_Anf 2000;
BA_REL_ "GenSigTimeoutTime" BU_SG_REL_ LED_LM_L SG_ 356 MXB_LED_43_Anf 2000;
BA_REL_ "GenSigTimeoutTime" BU_SG_REL_ LLP_L SG_ 356 MXB_LED_43_Anf 2000;
BA_REL_ "GenSigTimeoutTime" BU_SG_REL_ MXB_LM_L SG_ 356 MXB_LED_43_Anf 2000;
BA_REL_ "GenSigTimeoutTime" BU_SG_REL_ LED_DK3_LM_L SG_ 356 MXB_LED_44_Anf 2000;
BA_REL_ "GenSigTimeoutTime" BU_SG_REL_ LED_LM_L SG_ 356 MXB_LED_44_Anf 2000;
BA_REL_ "GenSigTimeoutTime" BU_SG_REL_ LLP_L SG_ 356 MXB_LED_44_Anf 2000;
BA_REL_ "GenSigTimeoutTime" BU_SG_REL_ MXB_LM_L SG_ 356 MXB_LED_44_Anf 2000;
BA_REL_ "GenSigTimeoutTime" BU_SG_REL_ LED_DK3_LM_L SG_ 356 MXB_LED_45_Anf 2000;
BA_REL_ "GenSigTimeoutTime" BU_SG_REL_ LED_LM_L SG_ 356 MXB_LED_45_Anf 2000;
BA_REL_ "GenSigTimeoutTime" BU_SG_REL_ LLP_L SG_ 356 MXB_LED_45_Anf 2000;
BA_REL_ "GenSigTimeoutTime" BU_SG_REL_ MXB_LM_L SG_ 356 MXB_LED_45_Anf 2000;
BA_REL_ "GenSigTimeoutTime" BU_SG_REL_ LWR_MXB_L SG_ 356 MXB_Sta_Diag 2000;
BA_REL_ "GenSigTimeoutTime" BU_SG_REL_ LWR_MXB_R SG_ 356 MXB_Sta_Diag 2000;
BA_REL_ "GenSigTimeoutTime" BU_SG_REL_ MXB_LM_L SG_ 356 MXB_Sta_Diag 2000;
BA_REL_ "GenSigTimeoutTime" BU_SG_REL_ MXB_LM_R SG_ 356 MXB_Sta_Diag 2000;
BA_REL_ "GenSigTimeoutTime" BU_SG_REL_ LED_DK3_LM_L SG_ 356 MXB_LED_46_Anf 2000;
BA_REL_ "GenSigTimeoutTime" BU_SG_REL_ LED_LM_R SG_ 356 MXB_LED_46_Anf 2000;
BA_REL_ "GenSigTimeoutTime" BU_SG_REL_ LLP_L SG_ 356 MXB_LED_46_Anf 2000;
BA_REL_ "GenSigTimeoutTime" BU_SG_REL_ LWR_MXB_R SG_ 356 MXB_LED_46_Anf 2000;
BA_REL_ "GenSigTimeoutTime" BU_SG_REL_ MXB_LM_R SG_ 356 MXB_LED_46_Anf 2000;
BA_REL_ "GenSigTimeoutTime" BU_SG_REL_ LED_DK3_LM_L SG_ 356 MXB_LED_47_Anf 2000;
BA_REL_ "GenSigTimeoutTime" BU_SG_REL_ LED_LM_R SG_ 356 MXB_LED_47_Anf 2000;
BA_REL_ "GenSigTimeoutTime" BU_SG_REL_ LLP_L SG_ 356 MXB_LED_47_Anf 2000;
BA_REL_ "GenSigTimeoutTime" BU_SG_REL_ LWR_MXB_R SG_ 356 MXB_LED_47_Anf 2000;
BA_REL_ "GenSigTimeoutTime" BU_SG_REL_ MXB_LM_R SG_ 356 MXB_LED_47_Anf 2000;
BA_REL_ "GenSigTimeoutTime" BU_SG_REL_ LED_DK3_LM_L SG_ 356 MXB_LED_48_Anf 2000;
BA_REL_ "GenSigTimeoutTime" BU_SG_REL_ LED_LM_R SG_ 356 MXB_LED_48_Anf 2000;
BA_REL_ "GenSigTimeoutTime" BU_SG_REL_ LLP_L SG_ 356 MXB_LED_48_Anf 2000;
BA_REL_ "GenSigTimeoutTime" BU_SG_REL_ LWR_MXB_R SG_ 356 MXB_LED_48_Anf 2000;
BA_REL_ "GenSigTimeoutTime" BU_SG_REL_ MXB_LM_R SG_ 356 MXB_LED_48_Anf 2000;
BA_REL_ "GenSigTimeoutTime" BU_SG_REL_ LED_DK3_LM_L SG_ 356 MXB_LED_49_Anf 2000;
BA_REL_ "GenSigTimeoutTime" BU_SG_REL_ LED_LM_R SG_ 356 MXB_LED_49_Anf 2000;
BA_REL_ "GenSigTimeoutTime" BU_SG_REL_ LLP_L SG_ 356 MXB_LED_49_Anf 2000;
BA_REL_ "GenSigTimeoutTime" BU_SG_REL_ LWR_MXB_R SG_ 356 MXB_LED_49_Anf 2000;
BA_REL_ "GenSigTimeoutTime" BU_SG_REL_ MXB_LM_R SG_ 356 MXB_LED_49_Anf 2000;
BA_REL_ "GenSigTimeoutTime" BU_SG_REL_ LED_DK3_LM_L SG_ 356 MXB_LED_50_Anf 2000;
BA_REL_ "GenSigTimeoutTime" BU_SG_REL_ LED_LM_R SG_ 356 MXB_LED_50_Anf 2000;
BA_REL_ "GenSigTimeoutTime" BU_SG_REL_ LLP_L SG_ 356 MXB_LED_50_Anf 2000;
BA_REL_ "GenSigTimeoutTime" BU_SG_REL_ LWR_MXB_R SG_ 356 MXB_LED_50_Anf 2000;
BA_REL_ "GenSigTimeoutTime" BU_SG_REL_ MXB_LM_R SG_ 356 MXB_LED_50_Anf 2000;
BA_REL_ "GenSigTimeoutTime" BU_SG_REL_ LED_DK3_LM_L SG_ 357 MXB_LED_51_Anf 2000;
BA_REL_ "GenSigTimeoutTime" BU_SG_REL_ LED_LM_R SG_ 357 MXB_LED_51_Anf 2000;
BA_REL_ "GenSigTimeoutTime" BU_SG_REL_ LLP_L SG_ 357 MXB_LED_51_Anf 2000;
BA_REL_ "GenSigTimeoutTime" BU_SG_REL_ LWR_MXB_R SG_ 357 MXB_LED_51_Anf 2000;
BA_REL_ "GenSigTimeoutTime" BU_SG_REL_ MXB_LM_R SG_ 357 MXB_LED_51_Anf 2000;
BA_REL_ "GenSigTimeoutTime" BU_SG_REL_ LED_DK3_LM_L SG_ 357 MXB_LED_52_Anf 2000;
BA_REL_ "GenSigTimeoutTime" BU_SG_REL_ LED_LM_R SG_ 357 MXB_LED_52_Anf 2000;
BA_REL_ "GenSigTimeoutTime" BU_SG_REL_ LLP_L SG_ 357 MXB_LED_52_Anf 2000;
BA_REL_ "GenSigTimeoutTime" BU_SG_REL_ LWR_MXB_R SG_ 357 MXB_LED_52_Anf 2000;
BA_REL_ "GenSigTimeoutTime" BU_SG_REL_ MXB_LM_R SG_ 357 MXB_LED_52_Anf 2000;
BA_REL_ "GenSigTimeoutTime" BU_SG_REL_ LED_DK3_LM_L SG_ 357 MXB_LED_53_Anf 2000;
BA_REL_ "GenSigTimeoutTime" BU_SG_REL_ LED_LM_R SG_ 357 MXB_LED_53_Anf 2000;
BA_REL_ "GenSigTimeoutTime" BU_SG_REL_ LLP_L SG_ 357 MXB_LED_53_Anf 2000;
BA_REL_ "GenSigTimeoutTime" BU_SG_REL_ LWR_MXB_R SG_ 357 MXB_LED_53_Anf 2000;
BA_REL_ "GenSigTimeoutTime" BU_SG_REL_ MXB_LM_R SG_ 357 MXB_LED_53_Anf 2000;
BA_REL_ "GenSigTimeoutTime" BU_SG_REL_ LED_DK3_LM_L SG_ 357 MXB_LED_54_Anf 2000;
BA_REL_ "GenSigTimeoutTime" BU_SG_REL_ LED_LM_R SG_ 357 MXB_LED_54_Anf 2000;
BA_REL_ "GenSigTimeoutTime" BU_SG_REL_ LLP_L SG_ 357 MXB_LED_54_Anf 2000;
BA_REL_ "GenSigTimeoutTime" BU_SG_REL_ LWR_MXB_R SG_ 357 MXB_LED_54_Anf 2000;
BA_REL_ "GenSigTimeoutTime" BU_SG_REL_ MXB_LM_R SG_ 357 MXB_LED_54_Anf 2000;
BA_REL_ "GenSigTimeoutTime" BU_SG_REL_ LED_DK3_LM_L SG_ 357 MXB_LED_55_Anf 2000;
BA_REL_ "GenSigTimeoutTime" BU_SG_REL_ LED_LM_R SG_ 357 MXB_LED_55_Anf 2000;
BA_REL_ "GenSigTimeoutTime" BU_SG_REL_ LLP_L SG_ 357 MXB_LED_55_Anf 2000;
BA_REL_ "GenSigTimeoutTime" BU_SG_REL_ LWR_MXB_R SG_ 357 MXB_LED_55_Anf 2000;
BA_REL_ "GenSigTimeoutTime" BU_SG_REL_ MXB_LM_R SG_ 357 MXB_LED_55_Anf 2000;
BA_REL_ "GenSigTimeoutTime" BU_SG_REL_ LED_DK3_LM_L SG_ 357 MXB_LED_56_Anf 2000;
BA_REL_ "GenSigTimeoutTime" BU_SG_REL_ LED_LM_R SG_ 357 MXB_LED_56_Anf 2000;
BA_REL_ "GenSigTimeoutTime" BU_SG_REL_ LLP_L SG_ 357 MXB_LED_56_Anf 2000;
BA_REL_ "GenSigTimeoutTime" BU_SG_REL_ LWR_MXB_R SG_ 357 MXB_LED_56_Anf 2000;
BA_REL_ "GenSigTimeoutTime" BU_SG_REL_ MXB_LM_R SG_ 357 MXB_LED_56_Anf 2000;
BA_REL_ "GenSigTimeoutTime" BU_SG_REL_ LED_DK3_LM_L SG_ 357 MXB_LED_57_Anf 2000;
BA_REL_ "GenSigTimeoutTime" BU_SG_REL_ LED_LM_R SG_ 357 MXB_LED_57_Anf 2000;
BA_REL_ "GenSigTimeoutTime" BU_SG_REL_ LLP_L SG_ 357 MXB_LED_57_Anf 2000;
BA_REL_ "GenSigTimeoutTime" BU_SG_REL_ LWR_MXB_R SG_ 357 MXB_LED_57_Anf 2000;
BA_REL_ "GenSigTimeoutTime" BU_SG_REL_ MXB_LM_R SG_ 357 MXB_LED_57_Anf 2000;
BA_REL_ "GenSigTimeoutTime" BU_SG_REL_ LED_DK3_LM_L SG_ 357 MXB_LED_58_Anf 2000;
BA_REL_ "GenSigTimeoutTime" BU_SG_REL_ LED_LM_R SG_ 357 MXB_LED_58_Anf 2000;
BA_REL_ "GenSigTimeoutTime" BU_SG_REL_ LLP_L SG_ 357 MXB_LED_58_Anf 2000;
BA_REL_ "GenSigTimeoutTime" BU_SG_REL_ MXB_LM_R SG_ 357 MXB_LED_58_Anf 2000;
BA_REL_ "GenSigTimeoutTime" BU_SG_REL_ LED_DK3_LM_L SG_ 357 MXB_LED_59_Anf 2000;
BA_REL_ "GenSigTimeoutTime" BU_SG_REL_ LED_LM_R SG_ 357 MXB_LED_59_Anf 2000;
BA_REL_ "GenSigTimeoutTime" BU_SG_REL_ LLP_L SG_ 357 MXB_LED_59_Anf 2000;
BA_REL_ "GenSigTimeoutTime" BU_SG_REL_ MXB_LM_R SG_ 357 MXB_LED_59_Anf 2000;
BA_REL_ "GenSigTimeoutTime" BU_SG_REL_ LED_DK3_LM_L SG_ 357 MXB_LED_60_Anf 2000;
BA_REL_ "GenSigTimeoutTime" BU_SG_REL_ LED_LM_R SG_ 357 MXB_LED_60_Anf 2000;
BA_REL_ "GenSigTimeoutTime" BU_SG_REL_ LLP_L SG_ 357 MXB_LED_60_Anf 2000;
BA_REL_ "GenSigTimeoutTime" BU_SG_REL_ MXB_LM_R SG_ 357 MXB_LED_60_Anf 2000;
BA_REL_ "GenSigTimeoutTime" BU_SG_REL_ LED_DK3_LM_L SG_ 358 MXB_LED_61_Anf 2000;
BA_REL_ "GenSigTimeoutTime" BU_SG_REL_ LED_LM_R SG_ 358 MXB_LED_61_Anf 2000;
BA_REL_ "GenSigTimeoutTime" BU_SG_REL_ LLP_L SG_ 358 MXB_LED_61_Anf 2000;
BA_REL_ "GenSigTimeoutTime" BU_SG_REL_ MXB_LM_R SG_ 358 MXB_LED_61_Anf 2000;
BA_REL_ "GenSigTimeoutTime" BU_SG_REL_ LED_DK3_LM_L SG_ 358 MXB_LED_62_Anf 2000;
BA_REL_ "GenSigTimeoutTime" BU_SG_REL_ LED_LM_R SG_ 358 MXB_LED_62_Anf 2000;
BA_REL_ "GenSigTimeoutTime" BU_SG_REL_ LLP_L SG_ 358 MXB_LED_62_Anf 2000;
BA_REL_ "GenSigTimeoutTime" BU_SG_REL_ MXB_LM_R SG_ 358 MXB_LED_62_Anf 2000;
BA_REL_ "GenSigTimeoutTime" BU_SG_REL_ LED_DK3_LM_L SG_ 358 MXB_LED_63_Anf 2000;
BA_REL_ "GenSigTimeoutTime" BU_SG_REL_ LED_LM_R SG_ 358 MXB_LED_63_Anf 2000;
BA_REL_ "GenSigTimeoutTime" BU_SG_REL_ LLP_L SG_ 358 MXB_LED_63_Anf 2000;
BA_REL_ "GenSigTimeoutTime" BU_SG_REL_ MXB_LM_R SG_ 358 MXB_LED_63_Anf 2000;
BA_REL_ "GenSigTimeoutTime" BU_SG_REL_ LED_DK3_LM_L SG_ 358 MXB_LED_64_Anf 2000;
BA_REL_ "GenSigTimeoutTime" BU_SG_REL_ LED_LM_R SG_ 358 MXB_LED_64_Anf 2000;
BA_REL_ "GenSigTimeoutTime" BU_SG_REL_ LLP_L SG_ 358 MXB_LED_64_Anf 2000;
BA_REL_ "GenSigTimeoutTime" BU_SG_REL_ MXB_LM_R SG_ 358 MXB_LED_64_Anf 2000;
BA_REL_ "GenSigTimeoutTime" BU_SG_REL_ LED_DK3_LM_L SG_ 358 MXB_LED_65_Anf 2000;
BA_REL_ "GenSigTimeoutTime" BU_SG_REL_ LED_LM_R SG_ 358 MXB_LED_65_Anf 2000;
BA_REL_ "GenSigTimeoutTime" BU_SG_REL_ LLP_L SG_ 358 MXB_LED_65_Anf 2000;
BA_REL_ "GenSigTimeoutTime" BU_SG_REL_ MXB_LM_R SG_ 358 MXB_LED_65_Anf 2000;
BA_REL_ "GenSigTimeoutTime" BU_SG_REL_ LED_DK3_LM_L SG_ 358 MXB_LED_66_Anf 2000;
BA_REL_ "GenSigTimeoutTime" BU_SG_REL_ LED_LM_R SG_ 358 MXB_LED_66_Anf 2000;
BA_REL_ "GenSigTimeoutTime" BU_SG_REL_ LLP_L SG_ 358 MXB_LED_66_Anf 2000;
BA_REL_ "GenSigTimeoutTime" BU_SG_REL_ MXB_LM_R SG_ 358 MXB_LED_66_Anf 2000;
BA_REL_ "GenSigTimeoutTime" BU_SG_REL_ LED_DK3_LM_L SG_ 358 MXB_LED_67_Anf 2000;
BA_REL_ "GenSigTimeoutTime" BU_SG_REL_ LED_LM_R SG_ 358 MXB_LED_67_Anf 2000;
BA_REL_ "GenSigTimeoutTime" BU_SG_REL_ LLP_L SG_ 358 MXB_LED_67_Anf 2000;
BA_REL_ "GenSigTimeoutTime" BU_SG_REL_ MXB_LM_R SG_ 358 MXB_LED_67_Anf 2000;
BA_REL_ "GenSigTimeoutTime" BU_SG_REL_ LED_DK3_LM_L SG_ 358 MXB_LED_68_Anf 2000;
BA_REL_ "GenSigTimeoutTime" BU_SG_REL_ LED_LM_R SG_ 358 MXB_LED_68_Anf 2000;
BA_REL_ "GenSigTimeoutTime" BU_SG_REL_ LLP_L SG_ 358 MXB_LED_68_Anf 2000;
BA_REL_ "GenSigTimeoutTime" BU_SG_REL_ MXB_LM_R SG_ 358 MXB_LED_68_Anf 2000;
BA_REL_ "GenSigTimeoutTime" BU_SG_REL_ LED_DK3_LM_L SG_ 358 MXB_LED_69_Anf 2000;
BA_REL_ "GenSigTimeoutTime" BU_SG_REL_ LED_LM_R SG_ 358 MXB_LED_69_Anf 2000;
BA_REL_ "GenSigTimeoutTime" BU_SG_REL_ LLP_L SG_ 358 MXB_LED_69_Anf 2000;
BA_REL_ "GenSigTimeoutTime" BU_SG_REL_ MXB_LM_R SG_ 358 MXB_LED_69_Anf 2000;
BA_REL_ "GenSigTimeoutTime" BU_SG_REL_ LED_DK3_LM_L SG_ 358 MXB_LED_70_Anf 2000;
BA_REL_ "GenSigTimeoutTime" BU_SG_REL_ LED_LM_R SG_ 358 MXB_LED_70_Anf 2000;
BA_REL_ "GenSigTimeoutTime" BU_SG_REL_ LLP_L SG_ 358 MXB_LED_70_Anf 2000;
BA_REL_ "GenSigTimeoutTime" BU_SG_REL_ MXB_LM_R SG_ 358 MXB_LED_70_Anf 2000;
BA_REL_ "GenSigTimeoutTime" BU_SG_REL_ LED_DK3_LM_L SG_ 359 MXB_LED_71_Anf 2000;
BA_REL_ "GenSigTimeoutTime" BU_SG_REL_ LED_LM_R SG_ 359 MXB_LED_71_Anf 2000;
BA_REL_ "GenSigTimeoutTime" BU_SG_REL_ LLP_L SG_ 359 MXB_LED_71_Anf 2000;
BA_REL_ "GenSigTimeoutTime" BU_SG_REL_ MXB_LM_R SG_ 359 MXB_LED_71_Anf 2000;
BA_REL_ "GenSigTimeoutTime" BU_SG_REL_ LED_DK3_LM_L SG_ 359 MXB_LED_72_Anf 2000;
BA_REL_ "GenSigTimeoutTime" BU_SG_REL_ LED_LM_R SG_ 359 MXB_LED_72_Anf 2000;
BA_REL_ "GenSigTimeoutTime" BU_SG_REL_ LLP_L SG_ 359 MXB_LED_72_Anf 2000;
BA_REL_ "GenSigTimeoutTime" BU_SG_REL_ MXB_LM_R SG_ 359 MXB_LED_72_Anf 2000;
BA_REL_ "GenSigTimeoutTime" BU_SG_REL_ LED_DK3_LM_L SG_ 359 MXB_LED_73_Anf 2000;
BA_REL_ "GenSigTimeoutTime" BU_SG_REL_ LED_LM_R SG_ 359 MXB_LED_73_Anf 2000;
BA_REL_ "GenSigTimeoutTime" BU_SG_REL_ LLP_L SG_ 359 MXB_LED_73_Anf 2000;
BA_REL_ "GenSigTimeoutTime" BU_SG_REL_ MXB_LM_R SG_ 359 MXB_LED_73_Anf 2000;
BA_REL_ "GenSigTimeoutTime" BU_SG_REL_ LED_DK3_LM_L SG_ 359 MXB_LED_74_Anf 2000;
BA_REL_ "GenSigTimeoutTime" BU_SG_REL_ LED_LM_R SG_ 359 MXB_LED_74_Anf 2000;
BA_REL_ "GenSigTimeoutTime" BU_SG_REL_ LLP_L SG_ 359 MXB_LED_74_Anf 2000;
BA_REL_ "GenSigTimeoutTime" BU_SG_REL_ MXB_LM_R SG_ 359 MXB_LED_74_Anf 2000;
BA_REL_ "GenSigTimeoutTime" BU_SG_REL_ LED_DK3_LM_L SG_ 359 MXB_LED_75_Anf 2000;
BA_REL_ "GenSigTimeoutTime" BU_SG_REL_ LED_LM_R SG_ 359 MXB_LED_75_Anf 2000;
BA_REL_ "GenSigTimeoutTime" BU_SG_REL_ LLP_L SG_ 359 MXB_LED_75_Anf 2000;
BA_REL_ "GenSigTimeoutTime" BU_SG_REL_ MXB_LM_R SG_ 359 MXB_LED_75_Anf 2000;
BA_REL_ "GenSigTimeoutTime" BU_SG_REL_ LED_DK3_LM_L SG_ 359 MXB_LED_76_Anf 2000;
BA_REL_ "GenSigTimeoutTime" BU_SG_REL_ LED_LM_R SG_ 359 MXB_LED_76_Anf 2000;
BA_REL_ "GenSigTimeoutTime" BU_SG_REL_ LLP_L SG_ 359 MXB_LED_76_Anf 2000;
BA_REL_ "GenSigTimeoutTime" BU_SG_REL_ MXB_LM_R SG_ 359 MXB_LED_76_Anf 2000;
BA_REL_ "GenSigTimeoutTime" BU_SG_REL_ LED_DK3_LM_L SG_ 359 MXB_LED_77_Anf 2000;
BA_REL_ "GenSigTimeoutTime" BU_SG_REL_ LED_LM_R SG_ 359 MXB_LED_77_Anf 2000;
BA_REL_ "GenSigTimeoutTime" BU_SG_REL_ LLP_L SG_ 359 MXB_LED_77_Anf 2000;
BA_REL_ "GenSigTimeoutTime" BU_SG_REL_ MXB_LM_R SG_ 359 MXB_LED_77_Anf 2000;
BA_REL_ "GenSigTimeoutTime" BU_SG_REL_ LED_DK3_LM_L SG_ 359 MXB_LED_78_Anf 2000;
BA_REL_ "GenSigTimeoutTime" BU_SG_REL_ LED_LM_R SG_ 359 MXB_LED_78_Anf 2000;
BA_REL_ "GenSigTimeoutTime" BU_SG_REL_ LLP_L SG_ 359 MXB_LED_78_Anf 2000;
BA_REL_ "GenSigTimeoutTime" BU_SG_REL_ MXB_LM_R SG_ 359 MXB_LED_78_Anf 2000;
BA_REL_ "GenSigTimeoutTime" BU_SG_REL_ LED_DK3_LM_L SG_ 359 MXB_LED_79_Anf 2000;
BA_REL_ "GenSigTimeoutTime" BU_SG_REL_ LED_LM_R SG_ 359 MXB_LED_79_Anf 2000;
BA_REL_ "GenSigTimeoutTime" BU_SG_REL_ LLP_L SG_ 359 MXB_LED_79_Anf 2000;
BA_REL_ "GenSigTimeoutTime" BU_SG_REL_ MXB_LM_R SG_ 359 MXB_LED_79_Anf 2000;
BA_REL_ "GenSigTimeoutTime" BU_SG_REL_ LED_DK3_LM_L SG_ 359 MXB_LED_80_Anf 2000;
BA_REL_ "GenSigTimeoutTime" BU_SG_REL_ LED_LM_R SG_ 359 MXB_LED_80_Anf 2000;
BA_REL_ "GenSigTimeoutTime" BU_SG_REL_ LLP_L SG_ 359 MXB_LED_80_Anf 2000;
BA_REL_ "GenSigTimeoutTime" BU_SG_REL_ MXB_LM_R SG_ 359 MXB_LED_80_Anf 2000;
BA_REL_ "GenSigTimeoutTime" BU_SG_REL_ LED_DK3_LM_L SG_ 360 MXB_LED_81_Anf 2000;
BA_REL_ "GenSigTimeoutTime" BU_SG_REL_ LED_LM_R SG_ 360 MXB_LED_81_Anf 2000;
BA_REL_ "GenSigTimeoutTime" BU_SG_REL_ LLP_L SG_ 360 MXB_LED_81_Anf 2000;
BA_REL_ "GenSigTimeoutTime" BU_SG_REL_ MXB_LM_R SG_ 360 MXB_LED_81_Anf 2000;
BA_REL_ "GenSigTimeoutTime" BU_SG_REL_ LED_DK3_LM_L SG_ 360 MXB_LED_82_Anf 2000;
BA_REL_ "GenSigTimeoutTime" BU_SG_REL_ LED_LM_R SG_ 360 MXB_LED_82_Anf 2000;
BA_REL_ "GenSigTimeoutTime" BU_SG_REL_ LLP_L SG_ 360 MXB_LED_82_Anf 2000;
BA_REL_ "GenSigTimeoutTime" BU_SG_REL_ MXB_LM_R SG_ 360 MXB_LED_82_Anf 2000;
BA_REL_ "GenSigTimeoutTime" BU_SG_REL_ LED_DK3_LM_L SG_ 360 MXB_LED_83_Anf 2000;
BA_REL_ "GenSigTimeoutTime" BU_SG_REL_ LED_LM_R SG_ 360 MXB_LED_83_Anf 2000;
BA_REL_ "GenSigTimeoutTime" BU_SG_REL_ LLP_L SG_ 360 MXB_LED_83_Anf 2000;
BA_REL_ "GenSigTimeoutTime" BU_SG_REL_ MXB_LM_R SG_ 360 MXB_LED_83_Anf 2000;
BA_REL_ "GenSigTimeoutTime" BU_SG_REL_ LED_DK3_LM_L SG_ 360 MXB_LED_84_Anf 2000;
BA_REL_ "GenSigTimeoutTime" BU_SG_REL_ LED_LM_R SG_ 360 MXB_LED_84_Anf 2000;
BA_REL_ "GenSigTimeoutTime" BU_SG_REL_ LLP_L SG_ 360 MXB_LED_84_Anf 2000;
BA_REL_ "GenSigTimeoutTime" BU_SG_REL_ MXB_LM_R SG_ 360 MXB_LED_84_Anf 2000;
BA_REL_ "GenSigTimeoutTime" BU_SG_REL_ LED_DK3_LM_L SG_ 360 MXB_LED_85_Anf 2000;
BA_REL_ "GenSigTimeoutTime" BU_SG_REL_ LED_LM_R SG_ 360 MXB_LED_85_Anf 2000;
BA_REL_ "GenSigTimeoutTime" BU_SG_REL_ LLP_L SG_ 360 MXB_LED_85_Anf 2000;
BA_REL_ "GenSigTimeoutTime" BU_SG_REL_ MXB_LM_R SG_ 360 MXB_LED_85_Anf 2000;
BA_REL_ "GenSigTimeoutTime" BU_SG_REL_ LED_DK3_LM_L SG_ 360 MXB_LED_86_Anf 2000;
BA_REL_ "GenSigTimeoutTime" BU_SG_REL_ LED_LM_R SG_ 360 MXB_LED_86_Anf 2000;
BA_REL_ "GenSigTimeoutTime" BU_SG_REL_ LLP_L SG_ 360 MXB_LED_86_Anf 2000;
BA_REL_ "GenSigTimeoutTime" BU_SG_REL_ MXB_LM_R SG_ 360 MXB_LED_86_Anf 2000;
BA_REL_ "GenSigTimeoutTime" BU_SG_REL_ LED_DK3_LM_L SG_ 360 MXB_LED_87_Anf 2000;
BA_REL_ "GenSigTimeoutTime" BU_SG_REL_ LED_LM_R SG_ 360 MXB_LED_87_Anf 2000;
BA_REL_ "GenSigTimeoutTime" BU_SG_REL_ LLP_L SG_ 360 MXB_LED_87_Anf 2000;
BA_REL_ "GenSigTimeoutTime" BU_SG_REL_ MXB_LM_R SG_ 360 MXB_LED_87_Anf 2000;
BA_REL_ "GenSigTimeoutTime" BU_SG_REL_ LED_DK3_LM_L SG_ 360 MXB_LED_88_Anf 2000;
BA_REL_ "GenSigTimeoutTime" BU_SG_REL_ LED_LM_R SG_ 360 MXB_LED_88_Anf 2000;
BA_REL_ "GenSigTimeoutTime" BU_SG_REL_ LLP_L SG_ 360 MXB_LED_88_Anf 2000;
BA_REL_ "GenSigTimeoutTime" BU_SG_REL_ MXB_LM_R SG_ 360 MXB_LED_88_Anf 2000;
BA_REL_ "GenSigTimeoutTime" BU_SG_REL_ LED_DK3_LM_L SG_ 360 MXB_LED_89_Anf 2000;
BA_REL_ "GenSigTimeoutTime" BU_SG_REL_ LED_LM_R SG_ 360 MXB_LED_89_Anf 2000;
BA_REL_ "GenSigTimeoutTime" BU_SG_REL_ LLP_L SG_ 360 MXB_LED_89_Anf 2000;
BA_REL_ "GenSigTimeoutTime" BU_SG_REL_ MXB_LM_R SG_ 360 MXB_LED_89_Anf 2000;
BA_REL_ "GenSigTimeoutTime" BU_SG_REL_ LED_DK3_LM_L SG_ 360 MXB_LED_90_Anf 2000;
BA_REL_ "GenSigTimeoutTime" BU_SG_REL_ LED_LM_R SG_ 360 MXB_LED_90_Anf 2000;
BA_REL_ "GenSigTimeoutTime" BU_SG_REL_ LLP_L SG_ 360 MXB_LED_90_Anf 2000;
BA_REL_ "GenSigTimeoutTime" BU_SG_REL_ MXB_LM_R SG_ 360 MXB_LED_90_Anf 2000;
BA_REL_ "GenSigTimeoutTime" BU_SG_REL_ LED_DK3_LM_R SG_ 361 MXB_LED_91_Anf 2000;
BA_REL_ "GenSigTimeoutTime" BU_SG_REL_ LLP_R SG_ 361 MXB_LED_91_Anf 2000;
BA_REL_ "GenSigTimeoutTime" BU_SG_REL_ LED_DK3_LM_R SG_ 361 MXB_LED_92_Anf 2000;
BA_REL_ "GenSigTimeoutTime" BU_SG_REL_ LLP_R SG_ 361 MXB_LED_92_Anf 2000;
BA_REL_ "GenSigTimeoutTime" BU_SG_REL_ LED_DK3_LM_R SG_ 361 MXB_LED_93_Anf 2000;
BA_REL_ "GenSigTimeoutTime" BU_SG_REL_ LLP_R SG_ 361 MXB_LED_93_Anf 2000;
BA_REL_ "GenSigTimeoutTime" BU_SG_REL_ LED_DK3_LM_R SG_ 361 MXB_LED_94_Anf 2000;
BA_REL_ "GenSigTimeoutTime" BU_SG_REL_ LLP_R SG_ 361 MXB_LED_94_Anf 2000;
BA_REL_ "GenSigTimeoutTime" BU_SG_REL_ LED_DK3_LM_R SG_ 361 MXB_LED_95_Anf 2000;
BA_REL_ "GenSigTimeoutTime" BU_SG_REL_ LLP_R SG_ 361 MXB_LED_95_Anf 2000;
BA_REL_ "GenSigTimeoutTime" BU_SG_REL_ LED_DK3_LM_R SG_ 361 MXB_LED_96_Anf 2000;
BA_REL_ "GenSigTimeoutTime" BU_SG_REL_ LLP_R SG_ 361 MXB_LED_96_Anf 2000;
BA_REL_ "GenSigTimeoutTime" BU_SG_REL_ LED_DK3_LM_R SG_ 361 MXB_LED_97_Anf 2000;
BA_REL_ "GenSigTimeoutTime" BU_SG_REL_ LLP_R SG_ 361 MXB_LED_97_Anf 2000;
BA_REL_ "GenSigTimeoutTime" BU_SG_REL_ LED_DK3_LM_R SG_ 361 MXB_LED_98_Anf 2000;
BA_REL_ "GenSigTimeoutTime" BU_SG_REL_ LLP_R SG_ 361 MXB_LED_98_Anf 2000;
BA_REL_ "GenSigTimeoutTime" BU_SG_REL_ LED_DK3_LM_R SG_ 361 MXB_LED_99_Anf 2000;
BA_REL_ "GenSigTimeoutTime" BU_SG_REL_ LLP_R SG_ 361 MXB_LED_99_Anf 2000;
BA_REL_ "GenSigTimeoutTime" BU_SG_REL_ LED_DK3_LM_R SG_ 361 MXB_LED_100_Anf 2000;
BA_REL_ "GenSigTimeoutTime" BU_SG_REL_ LLP_R SG_ 361 MXB_LED_100_Anf 2000;
BA_REL_ "GenSigTimeoutTime" BU_SG_REL_ BCM1 SG_ 2527679650 PAHS_L_AFS_Soll_Anf 5000;
BA_REL_ "GenSigTimeoutTime" BU_SG_REL_ BCM1 SG_ 2527679650 PAHS_R_AFS_Soll_Anf 5000;
BA_REL_ "GenSigTimeoutTime" BU_SG_REL_ BCM1 SG_ 2527679650 PAHS_L_LWR_Soll_Anf 5000;
BA_REL_ "GenSigTimeoutTime" BU_SG_REL_ BCM1 SG_ 2527679650 PAHS_R_LWR_Soll_Anf 5000;
BA_REL_ "GenSigTimeoutTime" BU_SG_REL_ BCM1 SG_ 2527679650 PAHS_L_GLW_Soll_Anf 5000;
BA_REL_ "GenSigTimeoutTime" BU_SG_REL_ BCM1 SG_ 2527679650 PAHS_R_GLW_Soll_Anf 5000;
BA_REL_ "GenSigTimeoutTime" BU_SG_REL_ LCM_L SG_ 1440 LS_Helligkeit_FW 2000;
BA_REL_ "GenSigTimeoutTime" BU_SG_REL_ LCM_R SG_ 1440 LS_Helligkeit_FW 2000;
BA_REL_ "GenSigTimeoutTime" BU_SG_REL_ LLP_L SG_ 1440 LS_Helligkeit_FW 2000;
BA_REL_ "GenSigTimeoutTime" BU_SG_REL_ LLP_R SG_ 1440 LS_Helligkeit_FW 2000;
BA_REL_ "GenSigTimeoutTime" BU_SG_REL_ LCM_L SG_ 1413 SI_NWDF 5000;
BA_REL_ "GenSigTimeoutTime" BU_SG_REL_ LCM_R SG_ 1413 SI_NWDF 5000;
BA_REL_ "GenSigTimeoutTime" BU_SG_REL_ LED_DK3_LM_L SG_ 1413 SI_NWDF 5000;
BA_REL_ "GenSigTimeoutTime" BU_SG_REL_ LED_DK3_LM_R SG_ 1413 SI_NWDF 5000;
BA_REL_ "GenSigTimeoutTime" BU_SG_REL_ LLP_L SG_ 1413 SI_NWDF 5000;
BA_REL_ "GenSigTimeoutTime" BU_SG_REL_ LLP_R SG_ 1413 SI_NWDF 5000;
BA_REL_ "GenSigTimeoutTime" BU_SG_REL_ LCM_L SG_ 1413 SI_NWDF_gueltig 5000;
BA_REL_ "GenSigTimeoutTime" BU_SG_REL_ LCM_R SG_ 1413 SI_NWDF_gueltig 5000;
BA_REL_ "GenSigTimeoutTime" BU_SG_REL_ LED_DK3_LM_L SG_ 1413 SI_NWDF_gueltig 5000;
BA_REL_ "GenSigTimeoutTime" BU_SG_REL_ LED_DK3_LM_R SG_ 1413 SI_NWDF_gueltig 5000;
BA_REL_ "GenSigTimeoutTime" BU_SG_REL_ LLP_L SG_ 1413 SI_NWDF_gueltig 5000;
BA_REL_ "GenSigTimeoutTime" BU_SG_REL_ LLP_R SG_ 1413 SI_NWDF_gueltig 5000;
VAL_ 1357 MXB_R_Fernl_MXB_Def_1 0 "kein_Fehler" 1 "Fehler" ;
VAL_ 1357 MXB_R_Fernl_MXB_Def_2 0 "kein_Fehler" 1 "Fehler" ;
VAL_ 1357 MXB_R_Fernl_MXB_Def_3 0 "kein_Fehler" 1 "Fehler" ;
VAL_ 1357 MXB_R_Fernl_MXB_Def_4 0 "kein_Fehler" 1 "Fehler" ;
VAL_ 1357 MXB_R_Fernl_MXB_Def_5 0 "kein_Fehler" 1 "Fehler" ;
VAL_ 1357 MXB_R_Fernl_MXB_Def_6 0 "kein_Fehler" 1 "Fehler" ;
VAL_ 1357 MXB_R_Fernl_MXB_Def_7 0 "kein_Fehler" 1 "Fehler" ;
VAL_ 1357 MXB_R_Fernl_MXB_Def_Err_Gultig 0 "Fehler_nicht_gueltig" 1 "Fehler_gueltig" ;
VAL_ 1357 MXB_R_Allg_Elektr_Def_1 0 "kein_Fehler" 1 "Fehler" ;
VAL_ 1357 MXB_R_Allg_Elektr_Def_2 0 "kein_Fehler" 1 "Fehler" ;
VAL_ 1357 MXB_R_Allg_Elektr_Def_3 0 "kein_Fehler" 1 "Fehler" ;
VAL_ 1357 MXB_R_Allg_Elektr_Def_4 0 "kein_Fehler" 1 "Fehler" ;
VAL_ 1357 MXB_R_Allg_Elektr_Def_5 0 "kein_Fehler" 1 "Fehler" ;
VAL_ 1357 MXB_R_Allg_Elektr_Def_6 0 "kein_Fehler" 1 "Fehler" ;
VAL_ 1357 MXB_R_Allg_Elektr_Def_7 0 "kein_Fehler" 1 "Fehler" ;
VAL_ 1357 MXB_R_Allg_Elektr_Def_8 0 "kein_Fehler" 1 "Fehler" ;
VAL_ 1357 MXB_R_Allg_Elektr_Def_Err_Gultig 0 "Fehler_nicht_gueltig" 1 "Fehler_gueltig" ;
VAL_ 1357 MXB_R_Luefter_1_Def_1 0 "kein_Fehler" 1 "Fehler" ;
VAL_ 1357 MXB_R_Luefter_1_Def_2 0 "kein_Fehler" 1 "Fehler" ;
VAL_ 1357 MXB_R_Luefter_1_Def_3 0 "kein_Fehler" 1 "Fehler" ;
VAL_ 1357 MXB_R_Luefter_1_Def_4 0 "kein_Fehler" 1 "Fehler" ;
VAL_ 1357 MXB_R_Luefter_2_Def_1 0 "kein_Fehler" 1 "Fehler" ;
VAL_ 1357 MXB_R_Luefter_2_Def_2 0 "kein_Fehler" 1 "Fehler" ;
VAL_ 1357 MXB_R_Luefter_2_Def_3 0 "kein_Fehler" 1 "Fehler" ;
VAL_ 1357 MXB_R_Luefter_2_Def_4 0 "kein_Fehler" 1 "Fehler" ;
VAL_ 1357 MXB_R_Luefter_1_Def_Err_Gultig 0 "Fehler_nicht_gueltig" 1 "Fehler_gueltig" ;
VAL_ 1357 MXB_R_Luefter_2_Def_Err_Gultig 0 "Fehler_nicht_gueltig" 1 "Fehler_gueltig" ;
VAL_ 1357 MXB_R_Allg_Elektr_Def 0 "Init" ;
VAL_ 1357 MXB_R_Fernl_MXB_Def 0 "Init" ;
VAL_ 1405 MXB_L_Temp_Abblendl 0 "Init" 255 "Fehler" ;
VAL_ 1405 MXB_L_Temp_Fernl 0 "Init" 255 "Fehler" ;
VAL_ 1405 MXB_L_Temp_Elektronik 0 "Init" 255 "Fehler" ;
VAL_ 1405 MXB_L_Spannung_Klemme15 0 "Init" 255 "Fehler" ;
VAL_ 1405 MXB_L_Fernl_Dimmung 0 "Init" ;
VAL_ 1405 MXB_L_Fernl_Temp_Schutz 0 "Temperaturschutz_nicht_aktiv" 1 "Temperaturschutz_aktiv" ;
VAL_ 1405 MXB_L_Fernl_Uspg_Schutz 0 "Unterspannungsschutz_nicht_aktiv" 1 "Unterspannungsschutz_aktiv" ;
VAL_ 2589283457 MXB_L_Spannung_Kanal1 253 "Init" 255 "Fehler" ;
VAL_ 2589283457 MXB_L_Spannung_Kanal2 253 "Init" 255 "Fehler" ;
VAL_ 2589283457 MXB_L_Spannung_Kanal3 253 "Init" 255 "Fehler" ;
VAL_ 2589283457 MXB_L_Strom_Kanal1 1021 "Init" 1023 "Fehler" ;
VAL_ 2589283457 MXB_L_Strom_Kanal2 1021 "Init" 1023 "Fehler" ;
VAL_ 2589283457 MXB_L_Strom_Kanal3 1021 "Init" 1023 "Fehler" ;
VAL_ 1406 MXB_R_Temp_Abblendl 0 "Init" 255 "Fehler" ;
VAL_ 1406 MXB_R_Temp_Fernl 0 "Init" 255 "Fehler" ;
VAL_ 1406 MXB_R_Temp_Elektronik 0 "Init" 255 "Fehler" ;
VAL_ 1406 MXB_R_Spannung_Klemme15 0 "Init" 255 "Fehler" ;
VAL_ 1406 MXB_R_Fernl_Dimmung 0 "Init" ;
VAL_ 1406 MXB_R_Fernl_Temp_Schutz 0 "Temperaturschutz_nicht_aktiv" 1 "Temperaturschutz_aktiv" ;
VAL_ 1406 MXB_R_Fernl_Uspg_Schutz 0 "Unterspannungsschutz_nicht_aktiv" 1 "Unterspannungsschutz_aktiv" ;
VAL_ 2589283458 MXB_R_Spannung_Kanal1 253 "Init" 255 "Fehler" ;
VAL_ 2589283458 MXB_R_Spannung_Kanal2 253 "Init" 255 "Fehler" ;
VAL_ 2589283458 MXB_R_Spannung_Kanal3 253 "Init" 255 "Fehler" ;
VAL_ 2589283458 MXB_R_Strom_Kanal1 1021 "Init" 1023 "Fehler" ;
VAL_ 2589283458 MXB_R_Strom_Kanal2 1021 "Init" 1023 "Fehler" ;
VAL_ 2589283458 MXB_R_Strom_Kanal3 1021 "Init" 1023 "Fehler" ;
VAL_ 352 MXB_LED_01_Anf 0 "Init" ;
VAL_ 352 MXB_LED_02_Anf 0 "Init" ;
VAL_ 352 MXB_LED_03_Anf 0 "Init" ;
VAL_ 352 MXB_LED_04_Anf 0 "Init" ;
VAL_ 352 MXB_LED_05_Anf 0 "Init" ;
VAL_ 352 MXB_LED_06_Anf 0 "Init" ;
VAL_ 352 MXB_LED_07_Anf 0 "Init" ;
VAL_ 352 MXB_LED_08_Anf 0 "Init" ;
VAL_ 352 MXB_LED_09_Anf 0 "Init" ;
VAL_ 352 MXB_LED_10_Anf 0 "Init" ;
VAL_ 353 MXB_LED_11_Anf 0 "Init" ;
VAL_ 353 MXB_LED_12_Anf 0 "Init" ;
VAL_ 353 MXB_LED_13_Anf 0 "Init" ;
VAL_ 353 MXB_LED_14_Anf 0 "Init" ;
VAL_ 353 MXB_LED_15_Anf 0 "Init" ;
VAL_ 353 MXB_LED_16_Anf 0 "Init" ;
VAL_ 353 MXB_LED_17_Anf 0 "Init" ;
VAL_ 353 MXB_LED_18_Anf 0 "Init" ;
VAL_ 353 MXB_LED_19_Anf 0 "Init" ;
VAL_ 353 MXB_LED_20_Anf 0 "Init" ;
VAL_ 362 MXB_LED_101_Anf 0 "Init" ;
VAL_ 362 MXB_LED_102_Anf 0 "Init" ;
VAL_ 362 MXB_LED_103_Anf 0 "Init" ;
VAL_ 362 MXB_LED_104_Anf 0 "Init" ;
VAL_ 362 MXB_LED_105_Anf 0 "Init" ;
VAL_ 362 MXB_LED_106_Anf 0 "Init" ;
VAL_ 362 MXB_LED_107_Anf 0 "Init" ;
VAL_ 362 MXB_LED_108_Anf 0 "Init" ;
VAL_ 362 MXB_LED_109_Anf 0 "Init" ;
VAL_ 362 MXB_LED_110_Anf 0 "Init" ;
VAL_ 363 MXB_LED_111_Anf 0 "Init" ;
VAL_ 363 MXB_LED_112_Anf 0 "Init" ;
VAL_ 363 MXB_LED_113_Anf 0 "Init" ;
VAL_ 363 MXB_LED_114_Anf 0 "Init" ;
VAL_ 363 MXB_LED_115_Anf 0 "Init" ;
VAL_ 363 MXB_LED_116_Anf 0 "Init" ;
VAL_ 363 MXB_LED_117_Anf 0 "Init" ;
VAL_ 363 MXB_LED_118_Anf 0 "Init" ;
VAL_ 363 MXB_LED_119_Anf 0 "Init" ;
VAL_ 363 MXB_LED_120_Anf 0 "Init" ;
VAL_ 364 MXB_LED_121_Anf 0 "Init" ;
VAL_ 364 MXB_LED_122_Anf 0 "Init" ;
VAL_ 364 MXB_LED_123_Anf 0 "Init" ;
VAL_ 364 MXB_LED_124_Anf 0 "Init" ;
VAL_ 364 MXB_LED_125_Anf 0 "Init" ;
VAL_ 364 MXB_LED_126_Anf 0 "Init" ;
VAL_ 364 MXB_LED_127_Anf 0 "Init" ;
VAL_ 364 MXB_LED_128_Anf 0 "Init" ;
VAL_ 364 MXB_LED_129_Anf 0 "Init" ;
VAL_ 364 MXB_LED_130_Anf 0 "Init" ;
VAL_ 365 MXB_LED_131_Anf 0 "Init" ;
VAL_ 365 MXB_LED_132_Anf 0 "Init" ;
VAL_ 365 MXB_LED_133_Anf 0 "Init" ;
VAL_ 365 MXB_LED_134_Anf 0 "Init" ;
VAL_ 365 MXB_LED_135_Anf 0 "Init" ;
VAL_ 365 MXB_LED_136_Anf 0 "Init" ;
VAL_ 365 MXB_LED_137_Anf 0 "Init" ;
VAL_ 365 MXB_LED_138_Anf 0 "Init" ;
VAL_ 365 MXB_LED_139_Anf 0 "Init" ;
VAL_ 365 MXB_LED_140_Anf 0 "Init" ;
VAL_ 366 MXB_LED_141_Anf 0 "Init" ;
VAL_ 366 MXB_LED_142_Anf 0 "Init" ;
VAL_ 366 MXB_LED_143_Anf 0 "Init" ;
VAL_ 366 MXB_LED_144_Anf 0 "Init" ;
VAL_ 366 MXB_LED_145_Anf 0 "Init" ;
VAL_ 366 MXB_LED_146_Anf 0 "Init" ;
VAL_ 366 MXB_LED_147_Anf 0 "Init" ;
VAL_ 366 MXB_LED_148_Anf 0 "Init" ;
VAL_ 366 MXB_LED_149_Anf 0 "Init" ;
VAL_ 366 MXB_LED_150_Anf 0 "Init" ;
VAL_ 367 MXB_LED_151_Anf 0 "Init" ;
VAL_ 367 MXB_LED_152_Anf 0 "Init" ;
VAL_ 367 MXB_LED_153_Anf 0 "Init" ;
VAL_ 367 MXB_LED_154_Anf 0 "Init" ;
VAL_ 367 MXB_LED_155_Anf 0 "Init" ;
VAL_ 367 MXB_LED_156_Anf 0 "Init" ;
VAL_ 367 MXB_LED_157_Anf 0 "Init" ;
VAL_ 367 MXB_LED_158_Anf 0 "Init" ;
VAL_ 367 MXB_LED_159_Anf 0 "Init" ;
VAL_ 367 MXB_LED_160_Anf 0 "Init" ;
VAL_ 372 MXB_LED_161_Anf 0 "Init" ;
VAL_ 372 MXB_LED_162_Anf 0 "Init" ;
VAL_ 372 MXB_LED_163_Anf 0 "Init" ;
VAL_ 372 MXB_LED_164_Anf 0 "Init" ;
VAL_ 372 MXB_LED_165_Anf 0 "Init" ;
VAL_ 372 MXB_LED_166_Anf 0 "Init" ;
VAL_ 372 MXB_LED_167_Anf 0 "Init" ;
VAL_ 372 MXB_LED_168_Anf 0 "Init" ;
VAL_ 372 MXB_LED_169_Anf 0 "Init" ;
VAL_ 372 MXB_LED_170_Anf 0 "Init" ;
VAL_ 373 MXB_LED_171_Anf 0 "Init" ;
VAL_ 373 MXB_LED_172_Anf 0 "Init" ;
VAL_ 373 MXB_LED_173_Anf 0 "Init" ;
VAL_ 373 MXB_LED_174_Anf 0 "Init" ;
VAL_ 373 MXB_LED_175_Anf 0 "Init" ;
VAL_ 373 MXB_LED_176_Anf 0 "Init" ;
VAL_ 373 MXB_LED_177_Anf 0 "Init" ;
VAL_ 373 MXB_LED_178_Anf 0 "Init" ;
VAL_ 373 MXB_LED_179_Anf 0 "Init" ;
VAL_ 373 MXB_LED_180_Anf 0 "Init" ;
VAL_ 354 MXB_LED_21_Anf 0 "Init" ;
VAL_ 354 MXB_LED_22_Anf 0 "Init" ;
VAL_ 354 MXB_LED_23_Anf 0 "Init" ;
VAL_ 354 MXB_LED_24_Anf 0 "Init" ;
VAL_ 354 MXB_LED_25_Anf 0 "Init" ;
VAL_ 354 MXB_LED_26_Anf 0 "Init" ;
VAL_ 354 MXB_LED_27_Anf 0 "Init" ;
VAL_ 354 MXB_LED_28_Anf 0 "Init" ;
VAL_ 354 MXB_LED_29_Anf 0 "Init" ;
VAL_ 354 MXB_LED_30_Anf 0 "Init" ;
VAL_ 355 MXB_LED_31_Anf 0 "Init" ;
VAL_ 355 MXB_LED_32_Anf 0 "Init" ;
VAL_ 355 MXB_LED_33_Anf 0 "Init" ;
VAL_ 355 MXB_LED_34_Anf 0 "Init" ;
VAL_ 355 MXB_LED_35_Anf 0 "Init" ;
VAL_ 355 MXB_LED_36_Anf 0 "Init" ;
VAL_ 355 MXB_LED_37_Anf 0 "Init" ;
VAL_ 355 MXB_LED_38_Anf 0 "Init" ;
VAL_ 355 MXB_LED_39_Anf 0 "Init" ;
VAL_ 355 MXB_LED_40_Anf 0 "Init" ;
VAL_ 356 MXB_LED_41_Anf 0 "Init" ;
VAL_ 356 MXB_LED_42_Anf 0 "Init" ;
VAL_ 356 MXB_LED_43_Anf 0 "Init" ;
VAL_ 356 MXB_LED_44_Anf 0 "Init" ;
VAL_ 356 MXB_LED_45_Anf 0 "Init" ;
VAL_ 356 MXB_Sta_Diag 0 "Init" 5 "Diagnose_VAS_Tester_laeuft" 10 "Diagnose_nicht_eingeleitet" 15 "Codierung_eingeleitet" ;
VAL_ 356 MXB_LED_46_Anf 0 "Init" ;
VAL_ 356 MXB_LED_47_Anf 0 "Init" ;
VAL_ 356 MXB_LED_48_Anf 0 "Init" ;
VAL_ 356 MXB_LED_49_Anf 0 "Init" ;
VAL_ 356 MXB_LED_50_Anf 0 "Init" ;
VAL_ 357 MXB_LED_51_Anf 0 "Init" ;
VAL_ 357 MXB_LED_52_Anf 0 "Init" ;
VAL_ 357 MXB_LED_53_Anf 0 "Init" ;
VAL_ 357 MXB_LED_54_Anf 0 "Init" ;
VAL_ 357 MXB_LED_55_Anf 0 "Init" ;
VAL_ 357 MXB_LED_56_Anf 0 "Init" ;
VAL_ 357 MXB_LED_57_Anf 0 "Init" ;
VAL_ 357 MXB_LED_58_Anf 0 "Init" ;
VAL_ 357 MXB_LED_59_Anf 0 "Init" ;
VAL_ 357 MXB_LED_60_Anf 0 "Init" ;
VAL_ 358 MXB_LED_61_Anf 0 "Init" ;
VAL_ 358 MXB_LED_62_Anf 0 "Init" ;
VAL_ 358 MXB_LED_63_Anf 0 "Init" ;
VAL_ 358 MXB_LED_64_Anf 0 "Init" ;
VAL_ 358 MXB_LED_65_Anf 0 "Init" ;
VAL_ 358 MXB_LED_66_Anf 0 "Init" ;
VAL_ 358 MXB_LED_67_Anf 0 "Init" ;
VAL_ 358 MXB_LED_68_Anf 0 "Init" ;
VAL_ 358 MXB_LED_69_Anf 0 "Init" ;
VAL_ 358 MXB_LED_70_Anf 0 "Init" ;
VAL_ 359 MXB_LED_71_Anf 0 "Init" ;
VAL_ 359 MXB_LED_72_Anf 0 "Init" ;
VAL_ 359 MXB_LED_73_Anf 0 "Init" ;
VAL_ 359 MXB_LED_74_Anf 0 "Init" ;
VAL_ 359 MXB_LED_75_Anf 0 "Init" ;
VAL_ 359 MXB_LED_76_Anf 0 "Init" ;
VAL_ 359 MXB_LED_77_Anf 0 "Init" ;
VAL_ 359 MXB_LED_78_Anf 0 "Init" ;
VAL_ 359 MXB_LED_79_Anf 0 "Init" ;
VAL_ 359 MXB_LED_80_Anf 0 "Init" ;
VAL_ 360 MXB_LED_81_Anf 0 "Init" ;
VAL_ 360 MXB_LED_82_Anf 0 "Init" ;
VAL_ 360 MXB_LED_83_Anf 0 "Init" ;
VAL_ 360 MXB_LED_84_Anf 0 "Init" ;
VAL_ 360 MXB_LED_85_Anf 0 "Init" ;
VAL_ 360 MXB_LED_86_Anf 0 "Init" ;
VAL_ 360 MXB_LED_87_Anf 0 "Init" ;
VAL_ 360 MXB_LED_88_Anf 0 "Init" ;
VAL_ 360 MXB_LED_89_Anf 0 "Init" ;
VAL_ 360 MXB_LED_90_Anf 0 "Init" ;
VAL_ 361 MXB_LED_91_Anf 0 "Init" ;
VAL_ 361 MXB_LED_92_Anf 0 "Init" ;
VAL_ 361 MXB_LED_93_Anf 0 "Init" ;
VAL_ 361 MXB_LED_94_Anf 0 "Init" ;
VAL_ 361 MXB_LED_95_Anf 0 "Init" ;
VAL_ 361 MXB_LED_96_Anf 0 "Init" ;
VAL_ 361 MXB_LED_97_Anf 0 "Init" ;
VAL_ 361 MXB_LED_98_Anf 0 "Init" ;
VAL_ 361 MXB_LED_99_Anf 0 "Init" ;
VAL_ 361 MXB_LED_100_Anf 0 "Init" ;
VAL_ 2527679650 PAHS_L_AFS_Soll_Anf 0 "nicht_angefordert" 1 "angefordert" ;
VAL_ 2527679650 PAHS_R_AFS_Soll_Anf 0 "nicht_angefordert" 1 "angefordert" ;
VAL_ 2527679650 PAHS_L_LWR_Soll_Anf 0 "nicht_angefordert" 1 "angefordert" ;
VAL_ 2527679650 PAHS_R_LWR_Soll_Anf 0 "nicht_angefordert" 1 "angefordert" ;
VAL_ 2527679650 PAHS_L_GLW_Soll_Anf 0 "nicht_angefordert" 1 "angefordert" ;
VAL_ 2527679650 PAHS_R_GLW_Soll_Anf 0 "nicht_angefordert" 1 "angefordert" ;
VAL_ 1440 LS_Helligkeit_IR 254 "Init" 255 "Fehler" ;
VAL_ 1440 LS_Helligkeit_FW 1022 "Init" 1023 "Fehler" ;
VAL_ 1440 LS_defekt 0 "OK" 1 "defekt" ;
VAL_ 1440 LS_Verbau 1 "Lichtsensor verbaut" ;
VAL_ 1440 RS_Regenmenge 14 "Init" 15 "Fehler" ;
VAL_ 1440 RS_Verbau 1 "Regensensor verbaut" ;
VAL_ 1440 RS_Verglasung_schliessen 0 "Verglasung nicht schliessen" 1 "Verglasung schliessen" ;
VAL_ 1440 RS_defekt 0 "OK" 1 "defekt" ;
VAL_ 1440 RS_Wischergeschwindigkeit 0 "kein Wischen" 1 "42 Huebe/min" 2 "45 Huebe/min" 3 "48 Huebe/min" 4 "51 Huebe/min" 5 "54 Huebe/min" 6 "57 Huebe/min" 7 "60 Huebe/min" ;
VAL_ 1440 RLS_Vorfeldhelligkeit_Boost 0 "groesser_24413_Lux" 1 "bis_24413_Lux" 2 "bis_22193_Lux" 3 "bis_20176_Lux" 4 "bis_18342_Lux" 5 "bis_16647_Lux" 6 "bis_15158_Lux" 7 "bis_13780_Lux" 8 "bis_12527_Lux" 9 "bis_11388_Lux" 10 "bis_10353_Lux" 11 "bis_9412_Lux" 12 "bis_8556_Lux" 13 "bis_7778_Lux" 14 "bis_7071_Lux" 15 "bis_6428_Lux" ;
VAL_ 1413 SI_Sammel_SG_Fehler 61 "Reserviert" 62 "Overflow" 63 "ungueltig" ;
VAL_ 1413 SI_Diagnose_Aktiv 0 "inaktiv" 1 "aktiv" ;
VAL_ 1413 SI_QRS_Mode 0 "QRS_Messmodus_nicht_aktiv" 1 "QRS_Messmodus_aktiv" ;
VAL_ 1413 SI_T_Mode 0 "Transportmodus_nicht_aktiv" 1 "Transportmodus_aktiv" ;
VAL_ 1413 SI_NWDF 0 "Ueberwachung_nicht_freigegeben" 1 "Ueberwachung_freigegeben" ;
VAL_ 1413 SI_NWDF_gueltig 0 "NWDF_wird_nicht_unterstuetzt" 1 "NWDF_wird_unterstuetzt" ;
VAL_ 1413 SI_Sammelfehler 0 "kein_Sammelfehler" 1 "Sammelfehler" ;
VAL_ 1413 GW_KD_Fehler 0 "kein_KD_Fehler" 1 "KD_Fehler" ;
VAL_ 1413 SI_T_Schutz 0 "Transportschutz_nicht_aktiv" 1 "Transportschutz_aktiv" ;
VAL_ 1413 SI_BUS_01 0 "keine_Busruhe" 1 "Busruhe" ;
VAL_ 1413 SI_BUS_02 0 "keine_Busruhe" 1 "Busruhe" ;
VAL_ 1413 SI_BUS_03 0 "keine_Busruhe" 1 "Busruhe" ;
VAL_ 1413 SI_BUS_04 0 "keine_Busruhe" 1 "Busruhe" ;
VAL_ 1413 SI_BUS_05 0 "keine_Busruhe" 1 "Busruhe" ;
VAL_ 1413 SI_BUS_06 0 "keine_Busruhe" 1 "Busruhe" ;
VAL_ 1413 SI_BUS_07 0 "keine_Busruhe" 1 "Busruhe" ;
VAL_ 1413 SI_BUS_08 0 "keine_Busruhe" 1 "Busruhe" ;
VAL_ 1413 SI_BUS_09 0 "keine_Busruhe" 1 "Busruhe" ;
VAL_ 1413 SI_BUS_10 0 "keine_Busruhe" 1 "Busruhe" ;
VAL_ 1413 SI_BUS_11 0 "keine_Busruhe" 1 "Busruhe" ;
VAL_ 1413 SI_BUS_12 0 "keine_Busruhe" 1 "Busruhe" ;
VAL_ 1413 SI_BUS_13 0 "keine_Busruhe" 1 "Busruhe" ;
VAL_ 1413 SI_BUS_14 0 "keine_Busruhe" 1 "Busruhe" ;
VAL_ 1413 SI_BUS_15 0 "keine_Busruhe" 1 "Busruhe" ;
VAL_ 1413 SI_Bus_Identifikation 16 "CAN_Diagnose" 17 "CAN_Antrieb" 18 "CAN_Komfort" 19 "CAN_Infotainment" 20 "CAN_Fahrwerk" 21 "CAN_Extended" 22 "CAN_Hybrid" 23 "CAN_Lade" 24 "CAN_Kombi" 25 "CAN_Komfort_2" 48 "FlexRay_A" 49 "FlexRay_B" ;
